VERSION ""

NS_ :

BS_:

BU_: BAP_Tester BedienDisp_vo BedienSG_hi CGS DDA Gateway Gateway_PAG GurtMikrofon OTA_FC ZR_High ZR_LIMU ZR_MIB_TOP_ab_Gen3 ZR_Standard

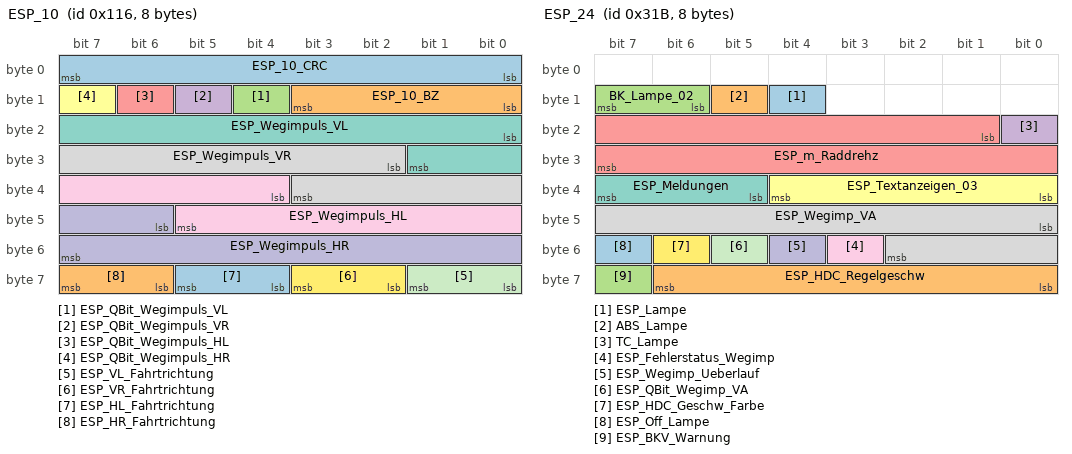
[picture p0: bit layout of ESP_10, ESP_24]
BO_ 278 ESP_10: 8 Gateway_MQB
 SG_ ESP_10_CRC : 0|8@1+ (1,0) [0|255] "" Airbag_MQB,Motor_Diesel_MQB,Motor_Hybrid_MQB,Motor_Otto_MQB
 SG_ ESP_10_BZ : 8|4@1+ (1,0) [0|15] "" Airbag_MQB,Motor_Diesel_MQB,Motor_Hybrid_MQB,Motor_Otto_MQB
 SG_ ESP_QBit_Wegimpuls_VL : 12|1@1+ (1,0) [0|1] "" Getriebe_DQ_Hybrid_MQB,Getriebe_DQ_MQB,Motor_Diesel_MQB,Motor_Hybrid_MQB,Motor_Otto_MQB
 SG_ ESP_QBit_Wegimpuls_VR : 13|1@1+ (1,0) [0|1] "" Getriebe_DQ_Hybrid_MQB,Getriebe_DQ_MQB,Motor_Diesel_MQB,Motor_Hybrid_MQB,Motor_Otto_MQB
 SG_ ESP_QBit_Wegimpuls_HL : 14|1@1+ (1,0) [0|1] "" Getriebe_DQ_Hybrid_MQB,Getriebe_DQ_MQB,Motor_Diesel_MQB,Motor_Hybrid_MQB,Motor_Otto_MQB
 SG_ ESP_QBit_Wegimpuls_HR : 15|1@1+ (1,0) [0|1] "" Getriebe_DQ_Hybrid_MQB,Getriebe_DQ_MQB,Motor_Diesel_MQB,Motor_Hybrid_MQB,Motor_Otto_MQB
 SG_ ESP_Wegimpuls_VL : 16|10@1+ (1,0) [0|1000] "" Getriebe_DQ_Hybrid_MQB,Getriebe_DQ_MQB,Motor_Diesel_MQB,Motor_Hybrid_MQB,Motor_Otto_MQB
 SG_ ESP_Wegimpuls_VR : 26|10@1+ (1,0) [0|1000] "" Getriebe_DQ_Hybrid_MQB,Getriebe_DQ_MQB,Motor_Diesel_MQB,Motor_Hybrid_MQB,Motor_Otto_MQB
 SG_ ESP_Wegimpuls_HL : 36|10@1+ (1,0) [0|1000] "" Getriebe_DQ_Hybrid_MQB,Getriebe_DQ_MQB,Motor_Diesel_MQB,Motor_Hybrid_MQB,Motor_Otto_MQB
 SG_ ESP_Wegimpuls_HR : 46|10@1+ (1,0) [0|1000] "" Getriebe_DQ_Hybrid_MQB,Getriebe_DQ_MQB,Motor_Diesel_MQB,Motor_Hybrid_MQB,Motor_Otto_MQB
 SG_ ESP_VL_Fahrtrichtung : 56|2@1+ (1,0) [0|3] "" Airbag_MQB,Getriebe_DQ_Hybrid_MQB,Getriebe_DQ_MQB,Motor_Diesel_MQB,Motor_Hybrid_MQB,Motor_Otto_MQB
 SG_ ESP_VR_Fahrtrichtung : 58|2@1+ (1,0) [0|3] "" Airbag_MQB,Getriebe_DQ_Hybrid_MQB,Getriebe_DQ_MQB,Motor_Diesel_MQB,Motor_Hybrid_MQB,Motor_Otto_MQB
 SG_ ESP_HL_Fahrtrichtung : 60|2@1+ (1,0) [0|3] "" Airbag_MQB,Getriebe_DQ_Hybrid_MQB,Getriebe_DQ_MQB,Motor_Diesel_MQB,Motor_Hybrid_MQB,Motor_Otto_MQB
 SG_ ESP_HR_Fahrtrichtung : 62|2@1+ (1,0) [0|3] "" Airbag_MQB,Getriebe_DQ_Hybrid_MQB,Getriebe_DQ_MQB,Motor_Diesel_MQB,Motor_Hybrid_MQB,Motor_Otto_MQB

BO_ 253 ESP_21: 8 Gateway
 SG_ CHECKSUM : 0|8@1+ (1,0) [0|255] ""  Vector__XXX
 SG_ COUNTER : 8|4@1+ (1,0) [0|15] ""  Vector__XXX
 SG_ BR_Eingriffsmoment : 12|10@1+ (1,-509) [-509|509] ""  Vector__XXX
 SG_ ESP_Diagnose : 23|1@1+ (1.0,0.0) [0.0|1] ""  ZR_High
 SG_ ESC_v_Signal_Qualifier_High_Low : 24|3@1+ (1.0,0.0) [0.0|7] ""  Vector__XXX
 SG_ ESP_Vorsteuerung : 28|1@1+ (1.0,0.0) [0.0|1] ""  Vector__XXX
 SG_ OBD_Schlechtweg : 30|1@1+ (1.0,0.0) [0.0|1] ""  ZR_High
 SG_ OBD_QBit_Schlechtweg : 31|1@1+ (1.0,0.0) [0.0|1] ""  ZR_High
 SG_ ESP_v_Signal : 32|16@1+ (0.01,0) [0.00|655.32] "Unit_KiloMeterPerHour"  BedienSG_hi,DDA,OTA_FC,ZR_High,ZR_LIMU,ZR_MIB_TOP_ab_Gen3,ZR_Standard
 SG_ ASR_Tastung_passiv : 48|1@1+ (1.0,0.0) [0.0|1] ""  OTA_FC
 SG_ ESP_Tastung_passiv : 49|1@1+ (1.0,0.0) [0.0|1] ""  OTA_FC,ZR_High,ZR_LIMU,ZR_MIB_TOP_ab_Gen3
 SG_ ESP_Systemstatus : 50|1@1+ (1.0,0.0) [0.0|1] ""  OTA_FC
 SG_ ASR_Schalteingriff : 51|2@1+ (1.0,0.0) [0.0|3] ""  Vector__XXX
 SG_ ESP_QBit_v_Signal : 55|1@1+ (1.0,0.0) [0.0|1] ""  ZR_High,ZR_LIMU,ZR_MIB_TOP_ab_Gen3,ZR_Standard
 SG_ ABS_Bremsung : 56|1@1+ (1.0,0.0) [0.0|1] ""  OTA_FC,ZR_High,ZR_LIMU,ZR_MIB_TOP_ab_Gen3
 SG_ ASR_Anf : 57|1@1+ (1.0,0.0) [0.0|1] ""  ZR_High
 SG_ MSR_Anf : 58|1@1+ (1.0,0.0) [0.0|1] ""  OTA_FC,ZR_High
 SG_ EBV_Eingriff : 59|1@1+ (1.0,0.0) [0.0|1] ""  Vector__XXX
 SG_ EDS_Eingriff : 60|1@1+ (1.0,0.0) [0.0|1] ""  Vector__XXX
 SG_ ESP_Eingriff : 61|1@1+ (1.0,0.0) [0.0|1] ""  OTA_FC,ZR_High
 SG_ ESP_ASP : 62|1@1+ (1.0,0.0) [0.0|1] ""  ZR_High
 SG_ ESC_Neutralschaltung : 63|1@1+ (1.0,0.0) [0.0|1] ""  Vector__XXX

BO_ 795 ESP_24: 8 Gateway
 SG_ ESP_Lampe : 12|1@1+ (1,0) [0|1] ""  Sub_Gateway
 SG_ ABS_Lampe : 13|1@1+ (1,0) [0|1] ""  Sub_Gateway
 SG_ BK_Lampe_02 : 14|2@1+ (1,0) [0|3] ""  Sub_Gateway
 SG_ TC_Lampe : 16|1@1+ (1,0) [0|1] ""  Sub_Gateway
 SG_ ESP_m_Raddrehz : 17|15@1+ (0.002,0) [0|65.278] "Unit_Hertz"  Sub_Gateway
 SG_ ESP_Textanzeigen_03 : 32|5@1+ (1,0) [0|31] ""  Sub_Gateway
 SG_ ESP_Meldungen : 37|3@1+ (1,0) [0|7] ""  Sub_Gateway
 SG_ ESP_Wegimp_VA : 40|11@1+ (1,0) [0|2047] ""  Sub_Gateway
 SG_ ESP_Fehlerstatus_Wegimp : 51|1@1+ (1,0) [0|1] ""  Sub_Gateway
 SG_ ESP_Wegimp_Ueberlauf : 52|1@1+ (1,0) [0|1] ""  Sub_Gateway
 SG_ ESP_QBit_Wegimp_VA : 53|1@1+ (1,0) [0|1] ""  Sub_Gateway
 SG_ ESP_HDC_Geschw_Farbe : 54|1@1+ (1,0) [0|1] ""  Sub_Gateway
 SG_ ESP_Off_Lampe : 55|1@1+ (1,0) [0|1] ""  Sub_Gateway
 SG_ ESP_HDC_Regelgeschw : 56|7@1+ (0.32,0) [0.32|39.68] "Unit_KiloMeterPerHour"  Sub_Gateway
 SG_ ESP_BKV_Warnung : 63|1@1+ (1,0) [0|1] ""  Sub_Gateway

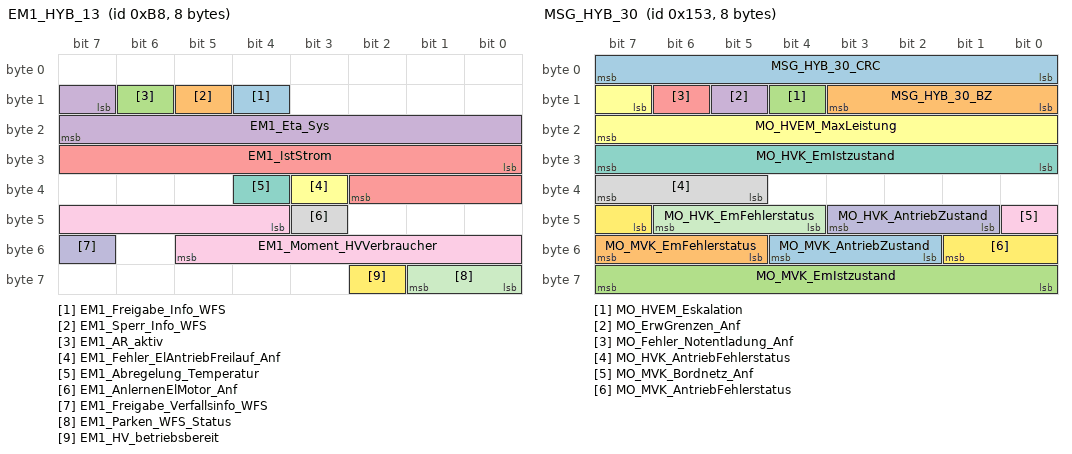
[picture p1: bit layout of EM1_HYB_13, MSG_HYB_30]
BO_ 184 EM1_HYB_13: 8 Gateway
 SG_ EM1_Freigabe_Info_WFS : 12|1@1+ (1,0) [0|1] ""  Sub_Gateway
 SG_ EM1_Sperr_Info_WFS : 13|1@1+ (1,0) [0|1] ""  Sub_Gateway
 SG_ EM1_AR_aktiv : 14|1@1+ (1,0) [0|1] ""  Sub_Gateway
 SG_ EM1_Eta_Sys : 15|9@1+ (0.2,0) [0|101.8] "Unit_PerCent"  Sub_Gateway
 SG_ EM1_IstStrom : 24|11@1+ (1,-1023) [-1023|1022] "Unit_Amper"  Sub_Gateway
 SG_ EM1_Fehler_ElAntriebFreilauf_Anf : 35|1@1+ (1,0) [0|1] ""  Sub_Gateway
 SG_ EM1_Abregelung_Temperatur : 36|1@1+ (1,0) [0|1] ""  Sub_Gateway
 SG_ EM1_AnlernenElMotor_Anf : 43|1@1+ (1,0) [0|1] ""  Sub_Gateway
 SG_ EM1_Moment_HVVerbraucher : 44|10@1+ (1,-511) [-511|511] "Unit_NewtoMeter"  Sub_Gateway
 SG_ EM1_Freigabe_Verfallsinfo_WFS : 55|1@1+ (1,0) [0|1] ""  Sub_Gateway
 SG_ EM1_Parken_WFS_Status : 56|2@1+ (1,0) [0|3] ""  Sub_Gateway
 SG_ EM1_HV_betriebsbereit : 58|1@1+ (1,0) [0|1] ""  Sub_Gateway

BO_ 339 MSG_HYB_30: 8 Gateway
 SG_ MSG_HYB_30_CRC : 0|8@1+ (1,0) [0|255] ""  Ladegeraet_Konzern
 SG_ MSG_HYB_30_BZ : 8|4@1+ (1,0) [0|15] ""  Ladegeraet_Konzern
 SG_ MO_HVEM_Eskalation : 12|1@1+ (1,0) [0|1] "" Vector__XXX
 SG_ MO_ErwGrenzen_Anf : 13|1@1+ (1,0) [0|1] ""  BMC_MLBevo
 SG_ MO_Fehler_Notentladung_Anf : 14|1@1+ (1,0) [0|1] "" Vector__XXX
 SG_ MO_HVEM_MaxLeistung : 15|9@1+ (50,0) [0|25450] "Unit_Watt" Vector__XXX
 SG_ MO_HVK_EmIstzustand : 24|8@1+ (1,0) [0|255] "" Vector__XXX
 SG_ MO_HVK_AntriebFehlerstatus : 37|3@1+ (1,0) [0|7] "" Vector__XXX
 SG_ MO_MVK_Bordnetz_Anf : 40|1@1+ (1,0) [0|1] "" Vector__XXX
 SG_ MO_HVK_AntriebZustand : 41|3@1+ (1,0) [0|7] ""  TME
 SG_ MO_HVK_EmFehlerstatus : 44|3@1+ (1,0) [0|7] "" Vector__XXX
 SG_ MO_MVK_AntriebFehlerstatus : 47|3@1+ (1,0) [0|7] "" Vector__XXX
 SG_ MO_MVK_AntriebZustand : 50|3@1+ (1,0) [0|7] "" Vector__XXX
 SG_ MO_MVK_EmFehlerstatus : 53|3@1+ (1,0) [0|7] "" Vector__XXX
 SG_ MO_MVK_EmIstzustand : 56|8@1+ (1,0) [0|255] "" Vector__XXX

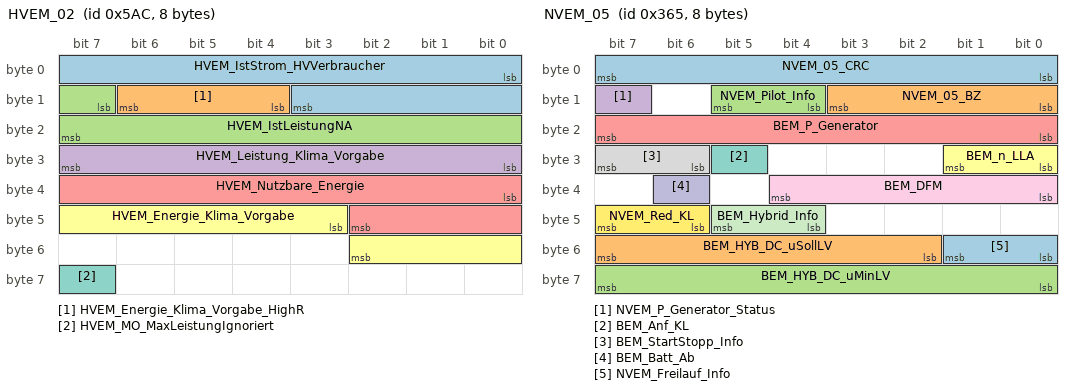
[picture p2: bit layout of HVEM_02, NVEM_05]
BO_ 1452 HVEM_02: 8 Gateway
 SG_ HVEM_IstStrom_HVVerbraucher : 0|12@1+ (0.1,-204.7) [-204.7|204.6] "Unit_Amper" Vector__XXX
 SG_ HVEM_Energie_Klima_Vorgabe_HighR : 12|3@1+ (10,0) [0|50] "Unit_WattHour"  TME
 SG_ HVEM_IstLeistungNA : 15|9@1+ (50,0) [0|25450] "Unit_Watt" Vector__XXX
 SG_ HVEM_Leistung_Klima_Vorgabe : 24|8@1+ (50,0) [0|12650] "Unit_Watt"  TME
 SG_ HVEM_Nutzbare_Energie : 32|11@1+ (50,0) [0|102200] "Unit_WattHour"  Ladegeraet_Konzern
 SG_ HVEM_Energie_Klima_Vorgabe : 43|8@1+ (50,0) [0|12650] "Unit_WattHour"  TME
 SG_ HVEM_MO_MaxLeistungIgnoriert : 63|1@1+ (1,0) [0|1] "" Vector__XXX

BO_ 869 NVEM_05: 8 Gateway
 SG_ NVEM_05_CRC : 0|8@1+ (1,0) [0|255] "" Vector__XXX
 SG_ NVEM_05_BZ : 8|4@1+ (1,0) [0|15] "" Vector__XXX
 SG_ NVEM_Pilot_Info : 12|2@1+ (1,0) [0|3] "" Vector__XXX
 SG_ NVEM_P_Generator_Status : 15|1@1+ (1,0) [0|1] "" Vector__XXX
 SG_ BEM_P_Generator : 16|8@1+ (50,0) [0|12700] "Unit_Watt" Vector__XXX
 SG_ BEM_n_LLA : 24|2@1+ (1,0) [0|3] "" Vector__XXX
 SG_ BEM_Anf_KL : 29|1@1+ (1,0) [0|1] "" Vector__XXX
 SG_ BEM_StartStopp_Info : 30|2@1+ (1,0) [0|3] "" Vector__XXX
 SG_ BEM_DFM : 32|5@1+ (3.225,0.025) [0.025|100] "" Vector__XXX
 SG_ BEM_Batt_Ab : 38|1@1+ (1,0) [0|1] ""  DCDC_800V_PAG,DCDC_IHEV
 SG_ BEM_Hybrid_Info : 44|2@1+ (1,0) [0|3] "" Vector__XXX
 SG_ NVEM_Red_KL : 46|2@1+ (1,0) [0|3] ""  TME
 SG_ NVEM_Freilauf_Info : 48|2@1+ (1,0) [0|3] "" Vector__XXX
 SG_ BEM_HYB_DC_uSollLV : 50|6@1+ (0.1,10.6) [10.6|16] "Unit_Volt"  DCDC_800V_PAG,DCDC_HV,LE_MLBevo
 SG_ BEM_HYB_DC_uMinLV : 56|8@1+ (0.1,0) [0|25.3] "Unit_Volt" Vector__XXX

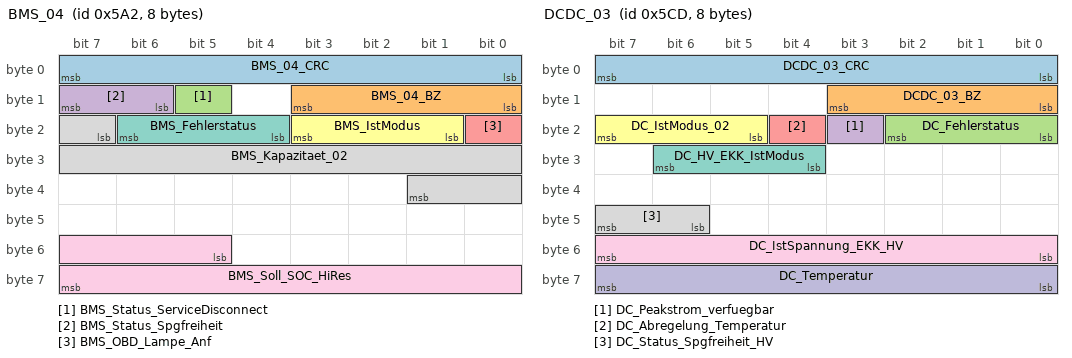
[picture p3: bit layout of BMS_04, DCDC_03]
BO_ 1442 BMS_04: 8 BMC_MLBevo
 SG_ BMS_04_CRC : 0|8@1+ (1,0) [0|255] ""  Gateway,Gateway_PAG,Sub_Gateway
 SG_ BMS_04_BZ : 8|4@1+ (1,0) [0|15] ""  Gateway,Gateway_PAG,Sub_Gateway
 SG_ BMS_Status_ServiceDisconnect : 13|1@1+ (1,0) [0|1] ""  DCDC_800V_PAG,DCDC_HV,Gateway,Gateway_PAG,Sub_Gateway
 SG_ BMS_Status_Spgfreiheit : 14|2@1+ (1,0) [0|3] ""  Gateway,Gateway_PAG,Sub_Gateway
 SG_ BMS_OBD_Lampe_Anf : 16|1@1+ (1,0) [0|1] ""  Gateway,Gateway_PAG,Sub_Gateway
 SG_ BMS_IstModus : 17|3@1+ (1,0) [0|7] ""  AWC,Gateway,Gateway_PAG,Ladegeraet_Konzern,LE1,LE2,LE2_3_MLBevo_LB,Sub_Gateway,TME
 SG_ BMS_Fehlerstatus : 20|3@1+ (1,0) [0|7] ""  AWC,DCDC_800V_PAG,DCDC_HV,Gateway,Gateway_PAG,Ladegeraet_Konzern,Sub_Gateway
 SG_ BMS_Kapazitaet_02 : 23|11@1+ (0.2,0) [0|409.2] "Unit_AmperHour"  Gateway,Gateway_PAG,Ladegeraet_Konzern,Sub_Gateway
 SG_ BMS_Soll_SOC_HiRes : 53|11@1+ (0.05,0) [0|100] "Unit_PerCent"  Gateway,Gateway_PAG,Sub_Gateway

BO_ 1485 DCDC_03: 8 DCDC_800V_PAG
 SG_ DCDC_03_CRC : 0|8@1+ (1,0) [0|255] ""  Gateway,Gateway_PAG,Sub_Gateway
 SG_ DCDC_03_BZ : 8|4@1+ (1,0) [0|15] ""  Gateway,Gateway_PAG,Sub_Gateway
 SG_ DC_Fehlerstatus : 16|3@1+ (1,0) [0|7] ""  Gateway,Gateway_PAG,Sub_Gateway
 SG_ DC_Peakstrom_verfuegbar : 19|1@1+ (1,0) [0|1] ""  Gateway,Gateway_PAG,Sub_Gateway
 SG_ DC_Abregelung_Temperatur : 20|1@1+ (1,0) [0|1] ""  Gateway_PAG,Sub_Gateway,TME
 SG_ DC_IstModus_02 : 21|3@1+ (1,0) [0|7] ""  DCDC_HV_02,Gateway,Gateway_PAG,Ladegeraet_Konzern,Sub_Gateway,TME
 SG_ DC_HV_EKK_IstModus : 28|3@1+ (1,0) [0|7] ""  Gateway,Gateway_PAG,Sub_Gateway,TME
 SG_ DC_Status_Spgfreiheit_HV : 46|2@1+ (1,0) [0|3] ""  Gateway,Gateway_PAG,Sub_Gateway
 SG_ DC_IstSpannung_EKK_HV : 48|8@1+ (2,0) [0|508] "Unit_Volt"  Gateway,Gateway_PAG,Sub_Gateway
 SG_ DC_Temperatur : 56|8@1+ (1,-40) [-40|213] "Unit_DegreCelsi"  Gateway,Gateway_PAG,Sub_Gateway,TME

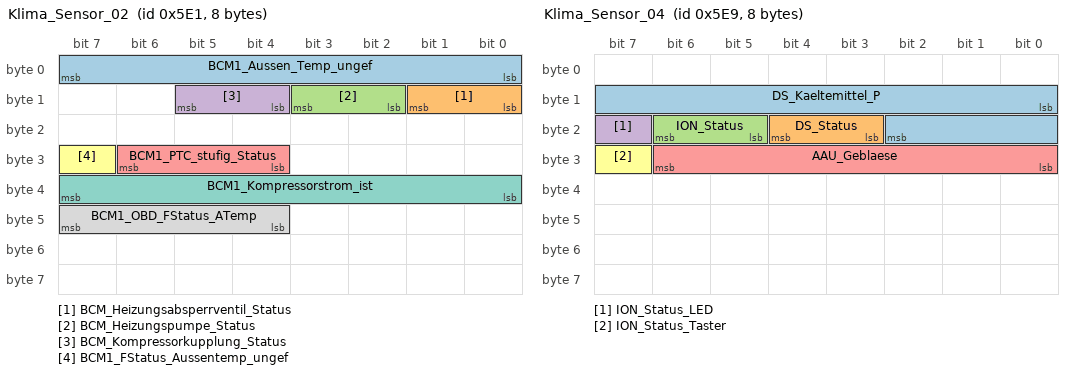
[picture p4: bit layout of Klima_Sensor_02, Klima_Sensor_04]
BO_ 1505 Klima_Sensor_02: 8 Gateway
 SG_ BCM1_Aussen_Temp_ungef : 0|8@1+ (0.5,-50) [-50|76] "Unit_DegreCelsi"  BMC_MLBevo,BMS_NV,FCU_MLBevo_FCEV,Ladegeraet_Konzern,TME
 SG_ BCM_Heizungsabsperrventil_Status : 8|2@1+ (1,0) [0|3] "" Vector__XXX
 SG_ BCM_Heizungspumpe_Status : 10|2@1+ (1,0) [0|3] "" Vector__XXX
 SG_ BCM_Kompressorkupplung_Status : 12|2@1+ (1,0) [0|3] "" Vector__XXX
 SG_ BCM1_PTC_stufig_Status : 28|3@1+ (1,0) [0|7] "" Vector__XXX
 SG_ BCM1_FStatus_Aussentemp_ungef : 31|1@1+ (1,0) [0|1] ""  TME
 SG_ BCM1_Kompressorstrom_ist : 32|8@1+ (4,0) [0|1000] "Unit_MilliAmper" Vector__XXX
 SG_ BCM1_OBD_FStatus_ATemp : 44|4@1+ (1,0) [0|15] ""  BMC_MLBevo,Ladegeraet_Konzern,TME

BO_ 1513 Klima_Sensor_04: 8 Gateway
 SG_ DS_Kaeltemittel_P : 8|11@1+ (0.0161,0) [0|32.9245] "Unit_Bar"  TME
 SG_ DS_Status : 19|2@1+ (1,0) [0|3] ""  TME
 SG_ ION_Status : 21|2@1+ (1,0) [0|3] "" Vector__XXX
 SG_ ION_Status_LED : 23|1@1+ (1,0) [0|1] "" Vector__XXX
 SG_ AAU_Geblaese : 24|7@1+ (1,0) [0|100] "Unit_PerCent" Vector__XXX
 SG_ ION_Status_Taster : 31|1@1+ (1,0) [0|1] "" Vector__XXX

BO_ 1600 Motor_07: 8 Motor_Diesel_MQB
 SG_ MO_QBit_Ansaugluft_Temp : 0|1@1+ (1,0) [0|1] "" Gateway_MQB
 SG_ MO_QBit_Oel_Temp : 1|1@1+ (1,0) [0|1] "" Gateway_MQB,Getriebe_DQ_Hybrid_MQB,Getriebe_DQ_MQB
 SG_ MO_QBit_Kuehlmittel_Temp : 2|1@1+ (1,0) [0|1] "" Gateway_MQB,Getriebe_DQ_Hybrid_MQB,Getriebe_DQ_MQB,LEH_MQB
 SG_ MO_Stellgliedtest_Soundaktuator : 3|1@1+ (1,0) [0|1] "" Gateway_MQB
 SG_ MO_HYB_Fehler_HV_Netz : 4|1@1+ (1,0) [0|1] "" Gateway_MQB
 SG_ MO_aktives_Getriebeheizen : 5|1@1+ (1,0) [0|1] "" Gateway_MQB,Getriebe_DQ_Hybrid_MQB,Getriebe_DQ_MQB
 SG_ MO_Absperrventil_oeffnen : 6|2@1+ (1,0) [0|3] "" Gateway_MQB
 SG_ MO_Ansaugluft_Temp : 8|8@1+ (0.75,-48) [-48|141.75] "Unit_DegreCelsi" Gateway_MQB
 SG_ MO_Oel_Temp : 16|8@1+ (1,-60) [-60|192] "Unit_DegreCelsi" Gateway_MQB,Getriebe_DQ_Hybrid_MQB,Getriebe_DQ_MQB
 SG_ MO_Kuehlmittel_Temp : 24|8@1+ (0.75,-48) [-48|141.75] "Unit_DegreCelsi" Gateway_MQB,Getriebe_DQ_Hybrid_MQB,Getriebe_DQ_MQB,LEH_MQB
 SG_ MO_Hoeheninfo : 32|8@1+ (0.00781,0) [0|1.98374] "" Gateway_MQB,Getriebe_DQ_Hybrid_MQB,Getriebe_DQ_MQB
 SG_ MO_Kennfeldk : 40|1@1+ (1,0) [0|1] "" Gateway_MQB
 SG_ MO_Versionsinfo : 41|6@1+ (1,0) [0|63] "" Gateway_MQB
 SG_ MO_Getriebe_kuehlen : 47|1@1+ (1,0) [0|1] "" Gateway_MQB,Getriebe_DQ_Hybrid_MQB,Getriebe_DQ_MQB
 SG_ MO_Mom_Traegheit_02 : 48|5@1+ (0.01,0) [0|0.31] "Unit_KiloGramMeterSquar" Gateway_MQB,Getriebe_DQ_Hybrid_MQB,Getriebe_DQ_MQB
 SG_ MO_Heizungspumpenansteuerung : 53|4@1+ (10,0) [0|100] "Unit_PerCent" Gateway_MQB
 SG_ MO_SpannungsAnf : 57|1@1+ (1,0) [0|1] "" Gateway_MQB
 SG_ MO_Nachlaufzeit_Heizungspumpe : 58|6@1+ (15,0) [0|945] "Unit_Secon" Gateway_MQB

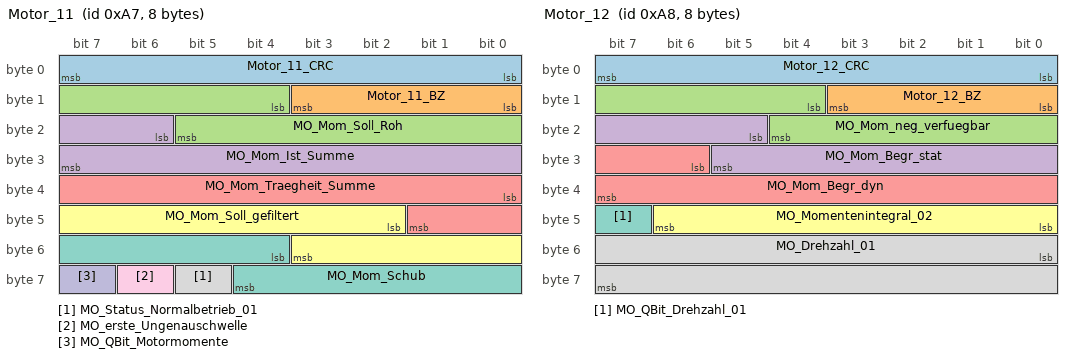
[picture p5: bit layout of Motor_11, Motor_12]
BO_ 167 Motor_11: 8 Motor_Diesel_MQB
 SG_ Motor_11_CRC : 0|8@1+ (1,0) [0|255] "" Gateway_MQB,Getriebe_DQ_Hybrid_MQB,Getriebe_DQ_MQB
 SG_ Motor_11_BZ : 8|4@1+ (1,0) [0|15] "" Gateway_MQB,Getriebe_DQ_Hybrid_MQB,Getriebe_DQ_MQB
 SG_ MO_Mom_Soll_Roh : 12|10@1+ (1,-509) [-509|509] "Unit_NewtoMeter" Gateway_MQB,Getriebe_DQ_Hybrid_MQB,Getriebe_DQ_MQB
 SG_ MO_Mom_Ist_Summe : 22|10@1+ (1,-509) [-509|509] "Unit_NewtoMeter" Gateway_MQB,Getriebe_DQ_Hybrid_MQB,Getriebe_DQ_MQB,SAK_MQB
 SG_ MO_Mom_Traegheit_Summe : 32|10@1+ (1,-509) [-509|509] "Unit_NewtoMeter" Gateway_MQB,Getriebe_DQ_Hybrid_MQB,Getriebe_DQ_MQB
 SG_ MO_Mom_Soll_gefiltert : 42|10@1+ (1,-509) [-509|509] "Unit_NewtoMeter" Gateway_MQB,Getriebe_DQ_Hybrid_MQB,Getriebe_DQ_MQB
 SG_ MO_Mom_Schub : 52|9@1+ (1,-509) [-509|0] "Unit_NewtoMeter" Gateway_MQB,Getriebe_DQ_Hybrid_MQB,Getriebe_DQ_MQB
 SG_ MO_Status_Normalbetrieb_01 : 61|1@1+ (1,0) [0|1] "" Gateway_MQB,Getriebe_DQ_Hybrid_MQB,Getriebe_DQ_MQB
 SG_ MO_erste_Ungenauschwelle : 62|1@1+ (1,0) [0|1] "" Gateway_MQB
 SG_ MO_QBit_Motormomente : 63|1@1+ (1,0) [0|1] "" Gateway_MQB,Getriebe_DQ_Hybrid_MQB,Getriebe_DQ_MQB

BO_ 168 Motor_12: 8 Motor_Diesel_MQB
 SG_ Motor_12_CRC : 0|8@1+ (1,0) [0|255] "" Gateway_MQB,Getriebe_DQ_Hybrid_MQB,Getriebe_DQ_MQB,LEH_MQB
 SG_ Motor_12_BZ : 8|4@1+ (1,0) [0|15] "" BMS_MQB,Gateway_MQB,Getriebe_DQ_Hybrid_MQB,Getriebe_DQ_MQB,LEH_MQB
 SG_ MO_Mom_neg_verfuegbar : 12|9@1+ (1,-509) [-509|0] "Unit_NewtoMeter" Gateway_MQB
 SG_ MO_Mom_Begr_stat : 21|9@1+ (1,0) [0|509] "Unit_NewtoMeter" Gateway_MQB,Getriebe_DQ_Hybrid_MQB,Getriebe_DQ_MQB
 SG_ MO_Mom_Begr_dyn : 30|10@1+ (1,-509) [-509|509] "Unit_NewtoMeter" Gateway_MQB
 SG_ MO_Momentenintegral_02 : 40|7@1+ (1,0) [0|100] "Unit_PerCent" Gateway_MQB,Getriebe_DQ_Hybrid_MQB,Getriebe_DQ_MQB
 SG_ MO_QBit_Drehzahl_01 : 47|1@1+ (1,0) [0|1] "" BMS_MQB,Gateway_MQB,Getriebe_DQ_Hybrid_MQB,Getriebe_DQ_MQB,LEH_MQB
 SG_ MO_Drehzahl_01 : 48|16@1+ (0.25,0) [0|16383] "Unit_MinutInver" BMS_MQB,Gateway_MQB,Getriebe_DQ_Hybrid_MQB,Getriebe_DQ_MQB,LEH_MQB,SAK_MQB

BO_ 958 Motor_14: 8 Gateway
 SG_ CHECKSUM : 0|8@1+ (1,0) [0|255] ""  XXX
 SG_ COUNTER : 8|4@1+ (1,0) [0|15] ""  XXX
 SG_ MO_StartStopp_Status : 12|2@1+ (1,0) [0|3] ""  Sub_Gateway,TME
 SG_ MO_StartStopp_Wiederstart : 14|1@1+ (1,0) [0|1] ""  BMS_NV,Sub_Gateway,TME
 SG_ MO_StartStopp_Motorstopp : 15|1@1+ (1,0) [0|1] ""  BMS_NV,Sub_Gateway,TME
 SG_ MO_Freig_Reku : 16|2@1+ (1,0) [0|3] ""  Sub_Gateway
 SG_ MO_Kl_75 : 18|1@1+ (1,0) [0|1] ""  Sub_Gateway,TME
 SG_ MO_Kl_50 : 19|1@1+ (1,0) [0|1] ""  DCDC_IHEV,Ladegeraet_Konzern,Sub_Gateway
 SG_ MO_Gangposition : 20|4@1+ (1,0) [0|15] ""  AWC,Sub_Gateway,TME
 SG_ MO_StartStopp_Fahrerwunsch : 24|2@1+ (1,0) [0|3] ""  Sub_Gateway,TME
 SG_ MO_HYB_Fahrbereitschaft : 26|1@1+ (1,0) [0|1] ""  AWC,BMS_NV,Ladegeraet_Konzern,Sub_Gateway,TME
 SG_ MO_Ext_E_Fahrt_aktiv : 27|1@1+ (1,0) [0|1] ""  Sub_Gateway,TME
 SG_ MO_Fahrer_bremst : 28|1@1+ (1,0) [0|1] ""  Sub_Gateway
 SG_ MO_QBit_Fahrer_bremst : 29|1@1+ (1,0) [0|1] ""  Sub_Gateway
 SG_ MO_BLS : 30|1@1+ (1,0) [0|1] ""  Sub_Gateway
 SG_ MO_Konsistenz_Bremsped : 31|1@1+ (1,0) [0|1] ""  Sub_Gateway
 SG_ MO_KomFehler_ESP : 32|1@1+ (1,0) [0|1] ""  Sub_Gateway
 SG_ MO_Klima_Eingr : 33|2@1+ (1,0) [0|3] ""  Sub_Gateway,TME
 SG_ MO_Aussp_Anlass : 35|1@1+ (1,0) [0|1] ""  Sub_Gateway
 SG_ MO_Freig_Anlass : 36|1@1+ (1,0) [0|1] ""  Sub_Gateway
 SG_ MO_Kuppl_schalter : 37|1@1+ (1,0) [0|1] ""  Sub_Gateway
 SG_ MO_Interlock : 38|1@1+ (1,0) [0|1] ""  Sub_Gateway
 SG_ MO_Motor_laeuft : 39|1@1+ (1,0) [0|1] ""  Sub_Gateway,TME
 SG_ MO_Kickdown : 40|1@1+ (1,0) [0|1] ""  Sub_Gateway,TME
 SG_ MO_QBit_KL_75 : 41|1@1+ (1,0) [0|1] ""  Sub_Gateway
 SG_ MO_EKlKomLeiRed : 42|2@1+ (1,0) [0|3] ""  Sub_Gateway
 SG_ MO_Handshake_STH : 44|1@1+ (1,0) [0|1] ""  Sub_Gateway
 SG_ MO_BKV_Unterdruckwarnung : 45|1@1+ (1,0) [0|1] ""  Sub_Gateway
 SG_ MO_Freigabe_Segeln : 46|1@1+ (1,0) [0|1] ""  Sub_Gateway
 SG_ MO_PTC_Status : 47|3@1+ (1,0) [0|7] ""  Sub_Gateway
 SG_ MO_QBit_Gangposition : 50|1@1+ (1,0) [0|1] ""  Sub_Gateway
 SG_ MO_Signalquelle_Gangposition : 51|1@1+ (1,0) [0|1] ""  Sub_Gateway
 SG_ MO_Remotestart_Betrieb : 52|1@1+ (1,0) [0|1] ""  Sub_Gateway
 SG_ MO_Remotestart_moeglich : 53|1@1+ (1,0) [0|1] ""  Sub_Gateway
 SG_ MO_FMAus_aktiv : 55|1@1+ (1,0) [0|1] ""  BMS_NV,Sub_Gateway
 SG_ MO_FMAus_Startvariante : 56|2@1+ (1,0) [0|3] ""  Sub_Gateway
 SG_ MO_BMS_NV_Anf_stuetzen : 58|1@1+ (1,0) [0|1] ""  Sub_Gateway
 SG_ MO_Zylinderabschaltung : 59|2@1+ (1,0) [0|3] ""  Sub_Gateway
 SG_ MO_HYB_VM_aktiv : 61|1@1+ (1,0) [0|1] ""  Sub_Gateway
 SG_ MO_StartVorauss_erfuellt : 62|2@1+ (1,0) [0|3] ""  AWC,Ladegeraet_Konzern,Sub_Gateway

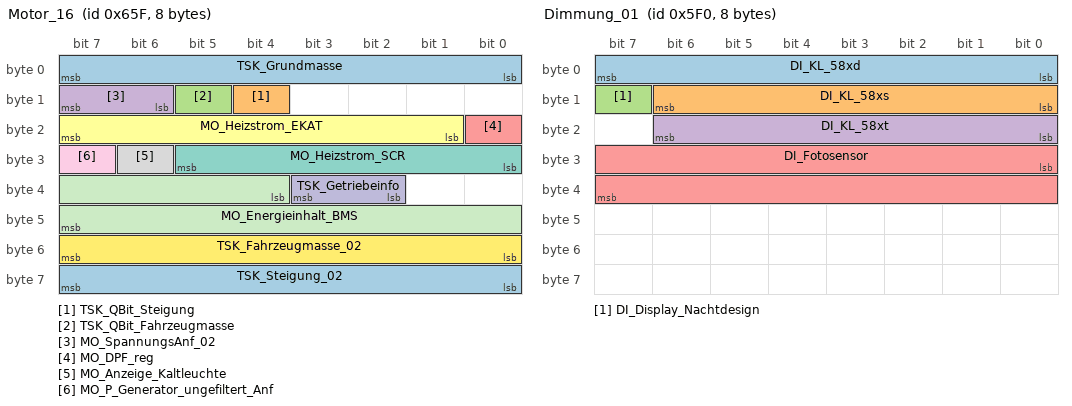
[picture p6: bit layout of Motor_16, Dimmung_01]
BO_ 1631 Motor_16: 8 Gateway
 SG_ TSK_Grundmasse : 0|8@1+ (32,0) [0|8128] "Unit_KiloGram"  ZR_High
 SG_ TSK_QBit_Steigung : 12|1@1+ (1.0,0.0) [0.0|1] ""  Vector__XXX
 SG_ TSK_QBit_Fahrzeugmasse : 13|1@1+ (1.0,0.0) [0.0|1] ""  ZR_High
 SG_ MO_SpannungsAnf_02 : 14|2@1+ (1.0,0.0) [0.0|3] ""  Vector__XXX
 SG_ MO_DPF_reg : 16|1@1+ (1.0,0.0) [0.0|1] ""  ZR_High
 SG_ MO_Heizstrom_EKAT : 17|7@1+ (1,0) [0|126] "Unit_Amper"  Vector__XXX
 SG_ MO_Heizstrom_SCR : 24|6@1+ (1,0) [0|62] "Unit_Amper"  Vector__XXX
 SG_ MO_Anzeige_Kaltleuchte : 30|1@1+ (1.0,0.0) [0.0|1] ""  Vector__XXX
 SG_ MO_P_Generator_ungefiltert_Anf : 31|1@1+ (1.0,0.0) [0.0|1] ""  Vector__XXX
 SG_ TSK_Getriebeinfo : 34|2@1+ (1.0,0.0) [0.0|3] ""  Vector__XXX
 SG_ MO_Energieinhalt_BMS : 36|12@1+ (25,0) [0|102325] "Unit_WattHour"  Vector__XXX
 SG_ TSK_Fahrzeugmasse_02 : 48|8@1+ (32,0) [0|8128] "Unit_KiloGram"  OTA_FC,ZR_High
 SG_ TSK_Steigung_02 : 56|8@1+ (0.8,-101.6) [-100.8|101.6] "Unit_PerCent"  OTA_FC

BO_ 1648 Motor_18: 8 Gateway
 SG_ MO_max_Ladedruck : 0|6@1+ (0.1,0) [0|6.3] "Unit_Bar"  Sub_Gateway
 SG_ MO_ANC_Kennfeld_Anf : 6|2@1+ (1,0) [0|3] ""  Sub_Gateway
 SG_ MO_Bremslicht_Reku : 8|1@1+ (1,0) [0|1] ""  Sub_Gateway
 SG_ MO_StartStopp_PopUp : 9|2@1+ (1,0) [0|3] ""  Sub_Gateway
 SG_ MO1_Sperr_Info_WFS : 11|1@1+ (1,0) [0|1] ""  Sub_Gateway
 SG_ MO1_Freigabe_Info_WFS : 12|1@1+ (1,0) [0|1] ""  Sub_Gateway
 SG_ MO_EPCL : 13|3@1+ (1,0) [0|7] ""  Sub_Gateway
 SG_ MO_Zylabsch_Texte_02 : 16|4@1+ (1,0) [0|15] ""  Sub_Gateway
 SG_ MO_Fahrzeugtyp : 20|3@1+ (1,0) [0|7] ""  BMS_NV,Sub_Gateway
 SG_ MO_NMAX_Schaltanzeige : 23|9@1+ (25,0) [0|12775] "Unit_MinutInver"  Sub_Gateway
 SG_ MO_Abstellzeit : 32|8@1+ (8,0) [0|2024] "Unit_Minut"  BMS_NV,Sub_Gateway,TME
 SG_ MO_Abstellzeit_Status : 40|2@1+ (1,0) [0|3] ""  BMS_NV,Sub_Gateway,TME
 SG_ MO1_Freigabe_Verfallsinfo_WFS : 42|1@1+ (1,0) [0|1] ""  Sub_Gateway
 SG_ MO_Hybrid_StartStopp_LED : 43|2@1+ (1,0) [0|3] ""  Sub_Gateway
 SG_ MO_Fehler_Zylabsch : 45|2@1+ (1,0) [0|3] ""  Sub_Gateway
 SG_ MO_Anzahl_Abgesch_Zyl : 47|3@1+ (1,0) [0|7] ""  Sub_Gateway
 SG_ MO_Zylabsch_Texte : 50|2@1+ (1,0) [0|3] ""  Sub_Gateway
 SG_ MO_Ethanol_BS_Texte : 52|3@1+ (1,0) [0|7] ""  Sub_Gateway
 SG_ MO_Drehzahl_Warnung : 55|1@1+ (1,0) [0|1] ""  Sub_Gateway
 SG_ MO_obere_Drehzahlgrenze : 56|8@1+ (50,0) [50|12750] "Unit_MinutInver"  Sub_Gateway

BO_ 967 Motor_26: 8 Gateway
 SG_ MO_Kuehlerluefter_MUX M : 0|1@1+ (1,0) [0|1] ""  TME
 SG_ MO_Kuehlerluefter_1 m0 : 1|7@1+ (1,0) [0|100] "Unit_PerCent"  TME
 SG_ MO_Kuehlerluefter_2 m1 : 1|7@1+ (1,0) [0|100] "Unit_PerCent"  TME
 SG_ MO_EFLEX_Lampe : 8|2@1+ (1,0) [0|3] "" Vector__XXX
 SG_ MO_KJS_nicht_bereit : 10|1@1+ (1,0) [0|1] "" Vector__XXX
 SG_ MO_ITM_Warnung_Pumpe : 11|1@1+ (1,0) [0|1] "" Vector__XXX
 SG_ WIV_Anzeige_aktiv : 12|1@1+ (1,0) [0|1] "" Vector__XXX
 SG_ WIV_Oelmin_Warn : 13|1@1+ (1,0) [0|1] "" Vector__XXX
 SG_ WIV_Sensorfehler : 14|1@1+ (1,0) [0|1] "" Vector__XXX
 SG_ WIV_Schieflage : 15|1@1+ (1,0) [0|1] "" Vector__XXX
 SG_ WIV_Oelstand : 16|4@1+ (12.5,0) [0|100] "Unit_PerCent" Vector__XXX
 SG_ MO_Zustand_HWP : 20|2@1+ (1,0) [0|3] ""  TME
 SG_ OLEV_Systemstoerung : 22|1@1+ (1,0) [0|1] "" Vector__XXX
 SG_ MO_Oelwarnung_max : 23|1@1+ (1,0) [0|1] "" Vector__XXX
 SG_ WIV_Oelsystem_aktiv : 24|1@1+ (1,0) [0|1] "" Vector__XXX
 SG_ WIV_nicht_betriebswarm : 25|1@1+ (1,0) [0|1] "" Vector__XXX
 SG_ WIV_Ueberfuell_Warn : 26|1@1+ (1,0) [0|1] "" Vector__XXX
 SG_ WIV_laufender_Motor : 27|1@1+ (1,0) [0|1] "" Vector__XXX
 SG_ MO_E_Warnungen : 28|4@1+ (1,0) [0|15] "" Vector__XXX
 SG_ MO_Text_Motorstart : 32|4@1+ (1,0) [0|15] "" Vector__XXX
 SG_ MO_E_Texte : 36|4@1+ (1,0) [0|15] "" Vector__XXX
 SG_ WIV_Oeldyn_avl : 40|1@1+ (1,0) [0|1] "" Vector__XXX
 SG_ MO_Text_Partikelfil_Reg : 41|1@1+ (1,0) [0|1] "" Vector__XXX
 SG_ OLEV_Oelstand_nicht_vorhanden : 42|1@1+ (1,0) [0|1] "" Vector__XXX
 SG_ WIV_Oelmenge : 43|5@1+ (125,0) [0|3875] "Unit_MilliLiter" Vector__XXX
 SG_ MO_Systemlampe : 48|1@1+ (1,0) [0|1] "" Vector__XXX
 SG_ MO_OBD2_Lampe : 49|1@1+ (1,0) [0|1] "" Vector__XXX
 SG_ MO_Heissleuchte : 50|1@1+ (1,0) [0|1] ""  TME
 SG_ MO_Partikel_Lampe : 51|1@1+ (1,0) [0|1] "" Vector__XXX
 SG_ MO_RedFahrleistung_Lampe : 52|1@1+ (1,0) [0|1] "" Vector__XXX
 SG_ WIV_Oelstand_nicht_vorhanden : 53|1@1+ (1,0) [0|1] "" Vector__XXX
 SG_ WIV_nachfuellanzeige_ein : 54|1@1+ (1,0) [0|1] "" Vector__XXX
 SG_ WIV_Ueberfuell_deaktiv : 55|1@1+ (1,0) [0|1] "" Vector__XXX
 SG_ WIV_Unterfuell_Warn : 56|1@1+ (1,0) [0|1] "" Vector__XXX
 SG_ MO_Tankdeckel_Lampe : 57|1@1+ (1,0) [0|1] "" Vector__XXX
 SG_ MO_Text_Tankdeckelwarn : 58|1@1+ (1,0) [0|1] "" Vector__XXX
 SG_ MO_Vorglueh_Lampe : 59|1@1+ (1,0) [0|1] "" Vector__XXX
 SG_ WIV_Oeldr_Warn_Motor : 60|1@1+ (1,0) [0|1] "" Vector__XXX
 SG_ MO_E_Mode : 61|3@1+ (1,0) [0|7] "" Vector__XXX

BO_ 916 WBA_03: 8 Gateway
 SG_ WBA_03_CRC : 0|8@1+ (1,0) [0|255] ""  Sub_Gateway
 SG_ WBA_03_BZ : 8|4@1+ (1,0) [0|15] ""  Sub_Gateway
 SG_ WBA_Fahrstufe_02 : 12|4@1+ (1,0) [0|15] ""  Sub_Gateway
 SG_ WBA_ZielFahrstufe : 16|4@1+ (1,0) [0|15] ""  Sub_Gateway
 SG_ WBA_GE_Warnung_02 : 20|4@1+ (1,0) [0|15] ""  Sub_Gateway
 SG_ WBA_eing_Gang_02 : 24|4@1+ (1,0) [0|15] ""  Sub_Gateway
 SG_ WBA_GE_Texte : 28|3@1+ (1,0) [0|7] ""  Sub_Gateway
 SG_ WBA_Segeln_aktiv : 31|1@1+ (1,0) [0|1] ""  Sub_Gateway
 SG_ WBA_Schaltschema : 32|5@1+ (1,0) [0|31] ""  Sub_Gateway
 SG_ WBA_GE_Zusatzwarnungen : 37|3@1+ (1,0) [0|7] ""  Sub_Gateway
 SG_ GE_Sollgang : 40|4@1+ (1,0) [0|15] ""  Sub_Gateway
 SG_ GE_Tipschaltempf_verfuegbar : 44|1@1+ (1,0) [0|1] ""  Sub_Gateway
 SG_ WBA_GE_Texte_02 : 45|3@1+ (1,0) [0|7] ""  Sub_Gateway
 SG_ WBA_GE_Texte_03 : 48|4@1+ (1,0) [0|15] ""  Sub_Gateway
 SG_ WBA_Blinken : 54|1@1+ (1,0) [0|1] ""  Sub_Gateway
 SG_ GE_Wiederstart_Anz_Std : 55|1@1+ (1,0) [0|1] ""  Sub_Gateway
 SG_ GE_Stoppverbot_Anz_01 : 56|1@1+ (1,0) [0|1] ""  Sub_Gateway
 SG_ GE_Stoppverbot_Anz_02 : 57|1@1+ (1,0) [0|1] ""  Sub_Gateway
 SG_ GE_Stoppverbot_Anz_03 : 58|1@1+ (1,0) [0|1] ""  Sub_Gateway
 SG_ GE_Stoppverbot_Anz_04 : 59|1@1+ (1,0) [0|1] ""  Sub_Gateway
 SG_ GE_Stoppverbot_Anz_05 : 60|1@1+ (1,0) [0|1] ""  Sub_Gateway
 SG_ GE_Stoppverbot_Anz_06 : 61|1@1+ (1,0) [0|1] ""  Sub_Gateway
 SG_ GE_Stoppverbot_Anz_07 : 62|1@1+ (1,0) [0|1] ""  Sub_Gateway
 SG_ GE_Stoppverbot_Anz_Std : 63|1@1+ (1,0) [0|1] ""  Sub_Gateway

BO_ 1283 HVK_01: 8 Gateway
 SG_ HVK_01_CRC : 0|8@1+ (1,0) [0|255] ""  BMC_MLBevo,DCDC_800V_PAG,DCDC_HV,DCDC_HV_02,FCU_MLBevo_FCEV,Ladegeraet_2,Ladegeraet_Konzern,LE1,LE2,LE_MLBevo,TME
 SG_ HVK_01_BZ : 8|4@1+ (1,0) [0|15] ""  BMC_MLBevo,DCDC_800V_PAG,DCDC_HV,DCDC_HV_02,FCU_MLBevo_FCEV,Ladegeraet_2,Ladegeraet_Konzern,LE1,LE2,LE_MLBevo,TME
 SG_ HVK_Istmodus_Anf : 12|1@1+ (1,0) [0|1] ""  BMC_MLBevo,DCDC_HV,FCU_MLBevo_FCEV,Ladegeraet_2,Ladegeraet_Konzern,LE1,LE2,LE_MLBevo
 SG_ HVK_TN1_Sollmodus : 13|2@1+ (1,0) [0|3] ""  DCDC_HV_02,FCU_MLBevo_FCEV
 SG_ HVK_MO_EmSollzustand : 16|8@1+ (1,0) [0|255] ""  FCU_MLBevo_FCEV
 SG_ HVK_BMS_Sollmodus : 24|3@1+ (1,0) [0|7] ""  BMC_MLBevo,FCU_MLBevo_FCEV
 SG_ HVK_DCDC_Sollmodus : 27|3@1+ (1,0) [0|7] ""  DCDC_800V_PAG,DCDC_HV,FCU_MLBevo_FCEV,LE_MLBevo
 SG_ HVK_EKK_Sollmodus : 30|3@1+ (1,0) [0|7] ""  FCU_MLBevo_FCEV,TME
 SG_ HVK_HVPTC_Sollmodus : 33|3@1+ (1,0) [0|7] ""  FCU_MLBevo_FCEV,TME
 SG_ HVK_HVLM_Sollmodus : 36|3@1+ (1,0) [0|7] ""  DCDC_HV_02,FCU_MLBevo_FCEV,Ladegeraet_Konzern
 SG_ HVK_HV_Netz_Warnungen : 39|2@1+ (1,0) [0|3] ""  FCU_MLBevo_FCEV
 SG_ HV_Bordnetz_aktiv : 41|1@1+ (1,0) [0|1] ""  DCDC_HV_02,FCU_MLBevo_FCEV,Ladegeraet_Konzern,LE1,LE2,LE_MLBevo
 SG_ HV_Bordnetz_Fehler : 42|1@1+ (1,0) [0|1] ""  FCU_MLBevo_FCEV,Ladegeraet_Konzern,TME
 SG_ HVK_Gesamtst_Spgfreiheit : 43|2@1+ (1,0) [0|3] ""  FCU_MLBevo_FCEV
 SG_ HVK_AktiveEntladung_Anf : 45|1@1+ (1,0) [0|1] ""  DCDC_800V_PAG,DCDC_HV,DCDC_HV_02,FCU_MLBevo_FCEV,LE1,LE2,LE_MLBevo
 SG_ HVK_Iso_Messung_Start : 50|3@1+ (1,0) [0|7] ""  BMC_MLBevo,FCU_MLBevo_FCEV
 SG_ HVK_DCDC_EKK_Sollmodus : 62|2@1+ (1,0) [0|3] ""  DCDC_800V_PAG,FCU_MLBevo_FCEV

BO_ 949 Klima_11: 8 Gateway
 SG_ KL_Drehz_Anh : 0|1@1+ (1,0) [0|1] ""  TME
 SG_ KL_Vorwarn_Komp_ein : 1|1@1+ (1,0) [0|1] ""  TME
 SG_ KL_AC_Schalter : 2|1@1+ (1,0) [0|1] ""  TME
 SG_ KL_Komp_Moment_alt : 3|1@1+ (1,0) [0|1] ""  TME
 SG_ KL_Vorwarn_Zuheizer_ein : 6|1@1+ (1,0) [0|1] "" Vector__XXX
 SG_ KL_Zustand : 7|1@1+ (1,0) [0|1] ""  TME
 SG_ KL_Kompressorkupplung_linear : 8|8@1+ (20,0) [0|4000] "Unit_MilliAmper" Vector__XXX
 SG_ KL_Charisma_FahrPr : 16|4@1+ (1,0) [0|15] ""  TME
 SG_ KL_Charisma_Status : 20|2@1+ (1,0) [0|3] ""  TME
 SG_ KL_nachtr_Stopp_Anf : 22|1@1+ (1,0) [0|1] "" Vector__XXX
 SG_ KL_T_Charge : 23|1@1+ (1,0) [0|1] "" Vector__XXX
 SG_ KL_Last_Kompr : 24|8@1+ (0.25,0) [0|63.5] "Unit_NewtoMeter"  TME
 SG_ KL_Spannungs_Anf : 32|2@1+ (1,0) [0|3] "" Vector__XXX
 SG_ KL_Thermomanagement : 34|2@1+ (1,0) [0|3] ""  TME
 SG_ KL_StartStopp_Info : 36|2@1+ (1,0) [0|3] ""  TME
 SG_ KL_Freilauf_Info : 38|2@1+ (1,0) [0|3] "" Vector__XXX
 SG_ KL_Anf_KL : 40|8@1+ (0.4,0) [0|101.6] "Unit_PerCent"  TME
 SG_ KL_el_Zuheizer_Stufe : 48|3@1+ (1,0) [0|7] ""  TME
 SG_ KL_Ausstattung_Klima : 51|3@1+ (1,0) [0|7] "" Vector__XXX
 SG_ KL_Variante_Standheizung : 54|2@1+ (1,0) [0|3] "" Vector__XXX

BO_ 1640 Klima_12: 8 Gateway
 SG_ KL_LRH_Taster : 0|1@1+ (1,0) [0|1] "" Vector__XXX
 SG_ KL_LRH_Stufe : 1|2@1+ (1,0) [0|3] "" Vector__XXX
 SG_ HSH_Taster : 3|2@1+ (1,0) [0|3] "" Vector__XXX
 SG_ FSH_Taster : 5|1@1+ (1,0) [0|1] "" Vector__XXX
 SG_ KL_Zuheizer_Freigabe : 6|1@1+ (1,0) [0|1] ""  TME
 SG_ KL_Beschlagsgefahr : 7|1@1+ (1,0) [0|1] ""  TME
 SG_ KL_SIH_Soll_li : 8|3@1+ (1,0) [0|7] ""  TME
 SG_ KL_SIH_Soll_re : 11|3@1+ (1,0) [0|7] ""  TME
 SG_ KRH_Soll_li : 14|2@1+ (1,0) [0|3] "" Vector__XXX
 SG_ KL_SIL_Soll_li : 16|3@1+ (1,0) [0|7] ""  TME
 SG_ KL_SIL_Soll_re : 19|3@1+ (1,0) [0|7] ""  TME
 SG_ KRH_Soll_re : 22|2@1+ (1,0) [0|3] "" Vector__XXX
 SG_ KL_Geblspng_Soll : 24|8@1+ (0.05,1.45) [1.5|14] "Unit_Volt" Vector__XXX
 SG_ KL_Geblspng_Fond_Soll : 32|8@1+ (0.05,1.45) [1.5|14] "Unit_Volt" Vector__XXX
 SG_ KL_I_Geblaese : 40|8@1+ (0.25,0) [0|63.5] "Unit_Amper" Vector__XXX
 SG_ KL_Kompressorstrom_soll : 48|10@1+ (1,0) [0|1021] ""  TME
 SG_ KL_Umluftklappe_Status : 58|4@1+ (1,0) [0|15] ""  TME
 SG_ KL_PTC_Verbauinfo : 62|2@1+ (1,0) [0|3] "" Vector__XXX

BO_ 1520 Dimmung_01: 8 Gateway_MQB
 SG_ DI_KL_58xd : 0|8@1+ (1,0) [0|253] "" Airbag_MQB
 SG_ DI_KL_58xs : 8|7@1+ (1,0) [0|100] "Unit_PerCent" Vector__XXX
 SG_ DI_Display_Nachtdesign : 15|1@1+ (1,0) [0|1] "" Vector__XXX
 SG_ DI_KL_58xt : 16|7@1+ (1,0) [0|100] "Unit_PerCent" Vector__XXX
 SG_ DI_Fotosensor : 24|16@1+ (1,0) [0|65535] "" Vector__XXX

BO_ 870 Blinkmodi_02: 8 Gateway
 SG_ BM_ZV_auf : 12|1@1+ (1.0,0.0) [0.0|1] ""  ZR_High
 SG_ BM_ZV_zu : 13|1@1+ (1.0,0.0) [0.0|1] ""  ZR_High
 SG_ BM_DWA_ein : 14|1@1+ (1.0,0.0) [0.0|1] ""  ZR_High
 SG_ BM_DWA_Alarm : 15|1@1+ (1.0,0.0) [0.0|1] ""  ZR_High
 SG_ BM_Crash : 16|1@1+ (1.0,0.0) [0.0|1] ""  ZR_High
 SG_ BM_Panik : 17|1@1+ (1.0,0.0) [0.0|1] ""  ZR_High
 SG_ BM_Not_Bremsung : 18|1@1+ (1.0,0.0) [0.0|1] ""  ZR_High
 SG_ BM_GDO : 19|1@1+ (1.0,0.0) [0.0|1] ""  Vector__XXX
 SG_ BM_Warnblinken : 20|1@1+ (1.0,0.0) [0.0|1] ""  ZR_High
 SG_ BM_Taxi_Notalarm : 21|1@1+ (1.0,0.0) [0.0|1] ""  ZR_High
 SG_ BM_Telematik : 22|1@1+ (1.0,0.0) [0.0|1] ""  ZR_High
 SG_ BM_links : 23|1@1+ (1.0,0.0) [0.0|1] ""  ZR_High
 SG_ BM_rechts : 24|1@1+ (1.0,0.0) [0.0|1] ""  ZR_High
 SG_ Blinken_li_Fzg_Takt : 25|1@1+ (1.0,0.0) [0.0|1] ""  ZR_High
 SG_ Blinken_re_Fzg_Takt : 26|1@1+ (1.0,0.0) [0.0|1] ""  ZR_High
 SG_ Blinken_li_Kombi_Takt : 27|1@1+ (1.0,0.0) [0.0|1] ""  ZR_High,ZR_LIMU,ZR_MIB_TOP_ab_Gen3,ZR_Standard
 SG_ Blinken_re_Kombi_Takt : 28|1@1+ (1.0,0.0) [0.0|1] ""  ZR_High,ZR_LIMU,ZR_MIB_TOP_ab_Gen3,ZR_Standard
 SG_ BM_NBA_n_codiert_n_aktiv : 29|1@1+ (1.0,0.0) [0.0|1] ""  Vector__XXX
 SG_ BM_NBA_Status : 30|2@1+ (1.0,0.0) [0.0|3] ""  Vector__XXX
 SG_ BM_WBT_Beleuchtung : 32|1@1+ (1.0,0.0) [0.0|1] ""  ZR_High
 SG_ BM_HD_Oeffnung_angelernt : 33|1@1+ (1.0,0.0) [0.0|1] ""  Vector__XXX
 SG_ BM_Autobahn : 34|1@1+ (1.0,0.0) [0.0|1] ""  ZR_High,ZR_LIMU,ZR_MIB_TOP_ab_Gen3
 SG_ BM_Rollenmodus_Blinken : 35|1@1+ (1.0,0.0) [0.0|1] ""  Vector__XXX
 SG_ BM_Recas : 36|1@1+ (1.0,0.0) [0.0|1] ""  ZR_High
 SG_ BM_Wischblinken : 37|1@1+ (1.0,0.0) [0.0|1] ""  ZR_High
 SG_ BM_Telematik_Abbruchgrund : 38|6@1+ (1.0,0.0) [0.0|63] ""  Vector__XXX
 SG_ BM_PiloPa : 44|1@1+ (1.0,0.0) [0.0|1] ""  ZR_High
 SG_ DWA_Alarmquelle : 59|5@1+ (1.0,0.0) [0.0|31] ""  ZR_High

BO_ 987 Gateway_72: 8 Gateway_MQB
 SG_ BCM_01_alt : 0|1@1+ (1,0) [0|1] "" Airbag_MQB
 SG_ SMLS_01_alt : 1|1@1+ (1,0) [0|1] "" Motor_Diesel_MQB,Motor_Otto_MQB
 SG_ ZV_02_alt : 2|1@1+ (1,0) [0|1] "" Getriebe_DQ_Hybrid_MQB,Getriebe_DQ_MQB,Motor_Diesel_MQB,Motor_Hybrid_MQB,Motor_Otto_MQB
 SG_ Wischer_01_alt : 3|1@1+ (1,0) [0|1] "" Motor_Diesel_MQB,Motor_Hybrid_MQB,Motor_Otto_MQB
 SG_ Anhaenger_01_alt : 4|1@1+ (1,0) [0|1] "" Getriebe_DQ_Hybrid_MQB,Getriebe_DQ_MQB
 SG_ Klima_Sensor_02_alt : 5|1@1+ (1,0) [0|1] "" Getriebe_DQ_Hybrid_MQB,Getriebe_DQ_MQB,Motor_Diesel_MQB,Motor_Hybrid_MQB,Motor_Otto_MQB
 SG_ VSG_01_alt : 6|1@1+ (1,0) [0|1] "" Airbag_MQB
 SG_ Klima_01_alt : 7|1@1+ (1,0) [0|1] "" Vector__XXX
 SG_ WFS_01_alt : 8|1@1+ (1,0) [0|1] "" Vector__XXX
 SG_ Licht_Anf_01_alt : 9|1@1+ (1,0) [0|1] "" Vector__XXX
 SG_ ZV_HFS_offen : 20|1@1+ (1,0) [0|1] "" Vector__XXX
 SG_ ZV_HBFS_offen : 21|1@1+ (1,0) [0|1] "" Vector__XXX
 SG_ VS_VD_offen_ver : 22|1@1+ (1,0) [0|1] "" Airbag_MQB
 SG_ VS_VD_zu_ver : 23|1@1+ (1,0) [0|1] "" Vector__XXX
 SG_ ZV_BT_offen : 24|1@1+ (1,0) [0|1] "" Vector__XXX
 SG_ BCM1_Rueckfahrlicht_Schalter : 25|1@1+ (1,0) [0|1] "" Airbag_MQB
 SG_ ZV_FT_offen : 26|1@1+ (1,0) [0|1] "" Getriebe_DQ_Hybrid_MQB,Getriebe_DQ_MQB,Motor_Diesel_MQB,Motor_Hybrid_MQB,Motor_Otto_MQB
 SG_ Wischer_vorne_aktiv : 27|1@1+ (1,0) [0|1] "" Motor_Diesel_MQB,Motor_Hybrid_MQB,Motor_Otto_MQB
 SG_ AAG_Anhaenger_erkannt : 28|1@1+ (1,0) [0|1] "" Getriebe_DQ_Hybrid_MQB,Getriebe_DQ_MQB
 SG_ BCM1_MH_Schalter : 29|1@1+ (1,0) [0|1] "" Vector__XXX
 SG_ ZV_HD_offen : 30|1@1+ (1,0) [0|1] "" Vector__XXX
 SG_ Waschen_vorne_aktiv : 31|1@1+ (1,0) [0|1] "" Vector__XXX
 SG_ KL_Thermomanagement : 32|2@1+ (1,0) [0|3] "" Vector__XXX
 SG_ WFS_Schluessel_Fahrberecht : 34|4@1+ (1,0) [0|15] "" Vector__XXX
 SG_ BCM1_RFahrlicht_Fzg_Anf : 38|1@1+ (1,0) [0|1] "" Vector__XXX
 SG_ BCM1_RFahrlicht_Ahg_Anf : 39|1@1+ (1,0) [0|1] "" Vector__XXX
 SG_ BH_Fernlicht : 49|1@1+ (1,0) [0|1] "" Vector__XXX
 SG_ BH_Blinker_li : 50|1@1+ (1,0) [0|1] "" Motor_Diesel_MQB,Motor_Otto_MQB
 SG_ BH_Blinker_re : 51|1@1+ (1,0) [0|1] "" Motor_Diesel_MQB,Motor_Otto_MQB
 SG_ BCM1_OBD_FStatus_ATemp : 52|4@1+ (1,0) [0|15] "" Getriebe_DQ_Hybrid_MQB,Getriebe_DQ_MQB,Motor_Diesel_MQB,Motor_Hybrid_MQB,Motor_Otto_MQB
 SG_ BCM1_Aussen_Temp_ungef : 56|8@1+ (0.5,-50) [-50|76] "Unit_DegreCelsi" Getriebe_DQ_Hybrid_MQB,Getriebe_DQ_MQB,Motor_Diesel_MQB,Motor_Hybrid_MQB,Motor_Otto_MQB

BO_ 299 GRA_ACC_01: 8 Gateway
 SG_ CHECKSUM : 0|8@1+ (1,0) [0|255] ""  Vector__XXX
 SG_ COUNTER : 8|4@1+ (1,0) [0|15] ""  Vector__XXX
 SG_ GRA_Hauptschalter : 12|1@1+ (1.0,0.0) [0.0|1] ""  ZR_High
 SG_ GRA_Abbrechen : 13|1@1+ (1.0,0.0) [0.0|1] ""  ZR_High
 SG_ GRA_Typ_Hauptschalter : 14|1@1+ (1.0,0.0) [0.0|1] ""  ZR_High
 SG_ GRA_Limiter : 15|1@1+ (1.0,0.0) [0.0|1] ""  ZR_High
 SG_ GRA_Tip_Setzen : 16|1@1+ (1.0,0.0) [0.0|1] ""  ZR_High
 SG_ GRA_Tip_Hoch : 17|1@1+ (1.0,0.0) [0.0|1] ""  ZR_High
 SG_ GRA_Tip_Runter : 18|1@1+ (1.0,0.0) [0.0|1] ""  ZR_High
 SG_ GRA_Tip_Wiederaufnahme : 19|1@1+ (1.0,0.0) [0.0|1] ""  ZR_High
 SG_ GRA_Verstellung_Zeitluecke : 20|2@1+ (1.0,0.0) [0.0|3] ""  ZR_High
 SG_ GRA_Codierung : 22|2@1+ (1.0,0.0) [0.0|3] ""  ZR_High
 SG_ GRA_Fehler : 24|1@1+ (1.0,0.0) [0.0|1] ""  ZR_High
 SG_ GRA_LIM_Taste_verfuegbar : 25|1@1+ (1.0,0.0) [0.0|1] ""  ZR_High
 SG_ GRA_Tip_Stufe_2 : 26|1@1+ (1.0,0.0) [0.0|1] ""  ZR_High
 SG_ GRA_ButtonTypeInfo : 27|3@1+ (1.0,0.0) [0.0|7] ""  ZR_High
 SG_ GRA_TravelAssist : 30|1@1+ (1.0,0.0) [0.0|1] ""  Vector__XXX
 SG_ GRA_reserveByte4 : 31|1@1+ (1.0,0.0) [0.0|1] ""  Vector__XXX
 SG_ GRA_reserveByte5 : 32|8@1+ (1.0,0.0) [0.0|255] ""  Vector__XXX
 SG_ GRA_reserveByte6 : 40|8@1+ (1.0,0.0) [0.0|255] ""  Vector__XXX
 SG_ GRA_reserveByte7 : 48|8@1+ (1.0,0.0) [0.0|255] ""  Vector__XXX
 SG_ GRA_reserveByte8 : 56|8@1+ (1.0,0.0) [0.0|255] ""  Vector__XXX

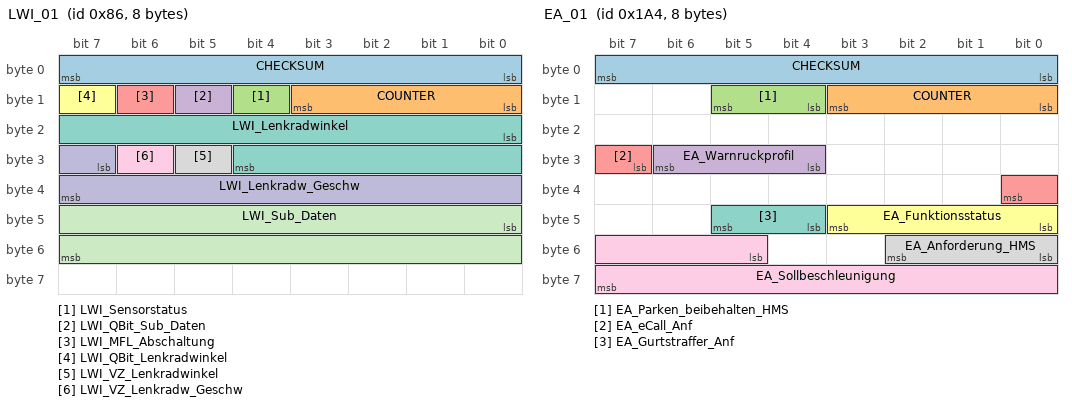
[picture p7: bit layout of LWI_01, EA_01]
BO_ 134 LWI_01: 8 Gateway
 SG_ CHECKSUM : 0|8@1+ (1,0) [0|255] "" Vector__XXX
 SG_ COUNTER : 8|4@1+ (1,0) [0|15] "" Vector__XXX
 SG_ LWI_Sensorstatus : 12|1@1+ (1,0) [0|1] "" ZR_High,ZR_LIMU,ZR_MIB_TOP_ab_Gen3,ZR_Standard
 SG_ LWI_QBit_Sub_Daten : 13|1@1+ (1,0) [0|1] "" ZR_High
 SG_ LWI_MFL_Abschaltung : 14|1@1+ (1,0) [0|1] "" ZR_High
 SG_ LWI_QBit_Lenkradwinkel : 15|1@1+ (1,0) [0|1] "" ZR_High,ZR_LIMU,ZR_MIB_TOP_ab_Gen3,ZR_Standard
 SG_ LWI_Lenkradwinkel : 16|13@1+ (0.0843,0) [0|800] "Unit_DegreOfArc" OTA_FC,ZR_High,ZR_LIMU,ZR_MIB_TOP_ab_Gen3,ZR_Standard
 SG_ LWI_VZ_Lenkradwinkel : 29|1@1+ (1,0) [0|1] "" OTA_FC,ZR_High,ZR_LIMU,ZR_MIB_TOP_ab_Gen3,ZR_Standard
 SG_ LWI_VZ_Lenkradw_Geschw : 30|1@1+ (1,0) [0|1] "" ZR_High
 SG_ LWI_Lenkradw_Geschw : 31|9@1+ (5,0) [0|2500] "Unit_DegreOfArcPerSecon" OTA_FC,ZR_High
 SG_ LWI_Sub_Daten : 40|16@1+ (1,0) [0|65535] "" Vector__XXX

BO_ 420 EA_01: 8 Gateway
 SG_ CHECKSUM : 0|8@1+ (1,0) [0|255] ""  Vector__XXX
 SG_ COUNTER : 8|4@1+ (1,0) [0|15] ""  Vector__XXX
 SG_ EA_Parken_beibehalten_HMS : 12|2@1+ (1.0,0.0) [0.0|3] ""  Vector__XXX
 SG_ EA_Warnruckprofil : 28|3@1+ (1.0,0.0) [0.0|7] ""  Vector__XXX
 SG_ EA_eCall_Anf : 31|2@1+ (1.0,0.0) [0.0|3] ""  ZR_High
 SG_ EA_Funktionsstatus : 40|4@1+ (1.0,0.0) [0.0|15] ""  ZR_High
 SG_ EA_Gurtstraffer_Anf : 44|2@1+ (1.0,0.0) [0.0|3] ""  Vector__XXX
 SG_ EA_Anforderung_HMS : 48|3@1+ (1.0,0.0) [0.0|7] ""  Vector__XXX
 SG_ EA_Sollbeschleunigung : 53|11@1+ (0.005,-7.22) [-7.220|3.005] "Unit_MeterPerSeconSquar"  Vector__XXX

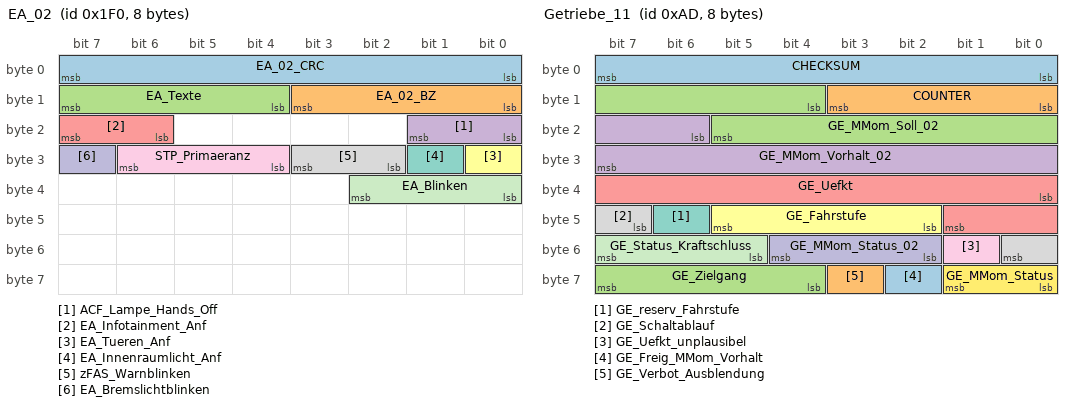
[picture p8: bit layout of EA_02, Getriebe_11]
BO_ 496 EA_02: 8 Gateway
 SG_ EA_02_CRC : 0|8@1+ (1,0) [0|255] ""  Vector__XXX
 SG_ EA_02_BZ : 8|4@1+ (1,0) [0|15] ""  Vector__XXX
 SG_ EA_Texte : 12|4@1+ (1.0,0.0) [0.0|15] ""  ZR_High
 SG_ ACF_Lampe_Hands_Off : 16|2@1+ (1.0,0.0) [0.0|3] ""  Vector__XXX
 SG_ EA_Infotainment_Anf : 22|2@1+ (1.0,0.0) [0.0|3] ""  ZR_High,ZR_LIMU,ZR_MIB_TOP_ab_Gen3,ZR_Standard
 SG_ EA_Tueren_Anf : 24|1@1+ (1.0,0.0) [0.0|1] ""  ZR_High
 SG_ EA_Innenraumlicht_Anf : 25|1@1+ (1.0,0.0) [0.0|1] ""  ZR_High
 SG_ zFAS_Warnblinken : 26|2@1+ (1.0,0.0) [0.0|3] ""  ZR_High
 SG_ STP_Primaeranz : 28|3@1+ (1.0,0.0) [0.0|7] ""  Vector__XXX
 SG_ EA_Bremslichtblinken : 31|1@1+ (1.0,0.0) [0.0|1] ""  Vector__XXX
 SG_ EA_Blinken : 32|3@1+ (1.0,0.0) [0.0|7] ""  Vector__XXX

BO_ 695 RCTA_01: 8 XXX
 SG_ RCTA_01_BZ : 8|4@1+ (1,0) [0|15] "" XXX
 SG_ RCTA_01_CRC : 0|8@1+ (1,0) [0|255] "" XXX

BO_ 173 Getriebe_11: 8 Gateway
 SG_ CHECKSUM : 0|8@1+ (1,0) [0|255] ""  Vector__XXX
 SG_ COUNTER : 8|4@1+ (1,0) [0|15] ""  Vector__XXX
 SG_ GE_MMom_Soll_02 : 12|10@1+ (1,-509) [-509|509] ""  Vector__XXX
 SG_ GE_MMom_Vorhalt_02 : 22|10@1+ (1,-509) [-509|509] ""  Vector__XXX
 SG_ GE_Uefkt : 32|10@1+ (0.1,0) [0.0|102.2] ""  Vector__XXX
 SG_ GE_Fahrstufe : 42|4@1+ (1.0,0.0) [0.0|15] ""  DDA,OTA_FC,ZR_High,ZR_LIMU,ZR_MIB_TOP_ab_Gen3
 SG_ GE_reserv_Fahrstufe : 46|1@1+ (1,0) [0|1] ""  Vector__XXX
 SG_ GE_Schaltablauf : 47|2@1+ (1.0,0.0) [0.0|3] ""  Vector__XXX
 SG_ GE_Uefkt_unplausibel : 49|1@1+ (1.0,0.0) [0.0|1] ""  Vector__XXX
 SG_ GE_MMom_Status_02 : 50|3@1+ (1.0,0.0) [0.0|7] ""  Vector__XXX
 SG_ GE_Status_Kraftschluss : 53|3@1+ (1.0,0.0) [0.0|7] ""  Vector__XXX
 SG_ GE_MMom_Status : 56|2@1+ (1.0,0.0) [0.0|3] ""  Vector__XXX
 SG_ GE_Freig_MMom_Vorhalt : 58|1@1+ (1.0,0.0) [0.0|1] ""  Vector__XXX
 SG_ GE_Verbot_Ausblendung : 59|1@1+ (1.0,0.0) [0.0|1] ""  Vector__XXX
 SG_ GE_Zielgang : 60|4@1+ (1.0,0.0) [0.0|15] ""  OTA_FC,ZR_High

BO_ 1411 ZV_02: 8 Gateway
 SG_ BCM_FH_Freigabe : 12|1@1+ (1.0,0.0) [0.0|1] ""  BedienDisp_vo
 SG_ BCM_Komfortfkt_Freigabe : 13|1@1+ (1.0,0.0) [0.0|1] ""  Vector__XXX
 SG_ BCM_HSK_Freigabe : 14|1@1+ (1.0,0.0) [0.0|1] ""  Vector__XXX
 SG_ BCM_Verdeck_Freigabe : 15|1@1+ (1.0,0.0) [0.0|1] ""  ZR_High
 SG_ ZV_verriegelt_intern_ist : 16|1@1+ (1.0,0.0) [0.0|1] ""  DDA,OTA_FC,ZR_High
 SG_ ZV_verriegelt_extern_ist : 17|1@1+ (1.0,0.0) [0.0|1] ""  DDA,OTA_FC,ZR_High
 SG_ ZV_verriegelt_intern_soll : 18|1@1+ (1.0,0.0) [0.0|1] ""  ZR_High
 SG_ ZV_verriegelt_extern_soll : 19|1@1+ (1.0,0.0) [0.0|1] ""  OTA_FC,ZR_High,ZR_LIMU,ZR_MIB_TOP_ab_Gen3,ZR_Standard
 SG_ ZV_gesafet_extern_ist : 20|1@1+ (1.0,0.0) [0.0|1] ""  ZR_High
 SG_ ZV_gesafet_extern_soll : 21|1@1+ (1.0,0.0) [0.0|1] ""  ZR_High,ZR_LIMU,ZR_MIB_TOP_ab_Gen3
 SG_ ZV_Einzeltuerentriegelung : 22|1@1+ (1.0,0.0) [0.0|1] ""  Vector__XXX
 SG_ ZV_Heckeinzelentriegelung : 23|1@1+ (1.0,0.0) [0.0|1] ""  Vector__XXX
 SG_ ZV_FT_offen : 24|1@1+ (1.0,0.0) [0.0|1] ""  DDA,OTA_FC,ZR_High,ZR_LIMU,ZR_MIB_TOP_ab_Gen3,ZR_Standard
 SG_ ZV_BT_offen : 25|1@1+ (1.0,0.0) [0.0|1] ""  DDA,OTA_FC,ZR_High,ZR_LIMU,ZR_MIB_TOP_ab_Gen3,ZR_Standard
 SG_ ZV_HFS_offen : 26|1@1+ (1.0,0.0) [0.0|1] ""  DDA,OTA_FC,ZR_High,ZR_LIMU,ZR_MIB_TOP_ab_Gen3,ZR_Standard
 SG_ ZV_HBFS_offen : 27|1@1+ (1.0,0.0) [0.0|1] ""  DDA,OTA_FC,ZR_High,ZR_LIMU,ZR_MIB_TOP_ab_Gen3,ZR_Standard
 SG_ ZV_HD_offen : 28|1@1+ (1.0,0.0) [0.0|1] ""  DDA,OTA_FC,ZR_High,ZR_LIMU,ZR_MIB_TOP_ab_Gen3,ZR_Standard
 SG_ ZV_HS_offen : 29|1@1+ (1.0,0.0) [0.0|1] ""  OTA_FC,ZR_High
 SG_ IRUE_aktiv : 30|1@1+ (1.0,0.0) [0.0|1] ""  ZR_High
 SG_ DWA_aktiv : 31|1@1+ (1.0,0.0) [0.0|1] ""  ZR_High
 SG_ HD_Hauptraste : 32|1@1+ (1.0,0.0) [0.0|1] ""  OTA_FC,ZR_High
 SG_ HD_Vorraste : 33|1@1+ (1.0,0.0) [0.0|1] ""  OTA_FC,ZR_High
 SG_ FFB_CarFinder : 38|1@1+ (1.0,0.0) [0.0|1] ""  Vector__XXX
 SG_ FFB_Komfortoeffnen : 39|1@1+ (1.0,0.0) [0.0|1] ""  Vector__XXX
 SG_ FFB_Komfortschliessen : 40|1@1+ (1.0,0.0) [0.0|1] ""  Vector__XXX
 SG_ ZV_Schluessel_Zugang : 42|4@1+ (1.0,0.0) [0.0|15] ""  ZR_High
 SG_ ZV_SafeFunktion_aktiv : 46|1@1+ (1.0,0.0) [0.0|1] ""  ZR_High
 SG_ FBS_Warn_Schluessel_Batt : 47|1@1+ (1.0,0.0) [0.0|1] ""  ZR_High
 SG_ ZV_Oeffnungsmodus : 48|2@1+ (1.0,0.0) [0.0|3] ""  Vector__XXX
 SG_ HFS_verriegelt : 50|1@1+ (1.0,0.0) [0.0|1] ""  OTA_FC
 SG_ HFS_gesafet : 51|1@1+ (1.0,0.0) [0.0|1] ""  Vector__XXX
 SG_ HBFS_verriegelt : 52|1@1+ (1.0,0.0) [0.0|1] ""  OTA_FC
 SG_ HBFS_gesafet : 53|1@1+ (1.0,0.0) [0.0|1] ""  Vector__XXX
 SG_ ZV_ist_Zustand_verfuegbar : 54|1@1+ (1.0,0.0) [0.0|1] ""  OTA_FC,ZR_High
 SG_ IRUE_Taster_Fkts_LED : 55|1@1+ (1.0,0.0) [0.0|1] ""  ZR_High
 SG_ ZV_Tankklappe_offen : 56|1@1+ (1.0,0.0) [0.0|1] ""  ZR_High
 SG_ ZV_Rollo_auf : 57|1@1+ (1.0,0.0) [0.0|1] ""  ZR_High
 SG_ ZV_Rollo_zu : 58|1@1+ (1.0,0.0) [0.0|1] ""  ZR_High
 SG_ ZV_SAD_auf : 59|1@1+ (1.0,0.0) [0.0|1] ""  ZR_High
 SG_ ZV_SAD_zu : 60|1@1+ (1.0,0.0) [0.0|1] ""  ZR_High
 SG_ BCM_Tankklappensteller_Fehler : 61|1@1+ (1.0,0.0) [0.0|1] ""  ZR_High
 SG_ ZV_verriegelt_soll : 62|2@1+ (1.0,0.0) [0.0|3] ""  Vector__XXX

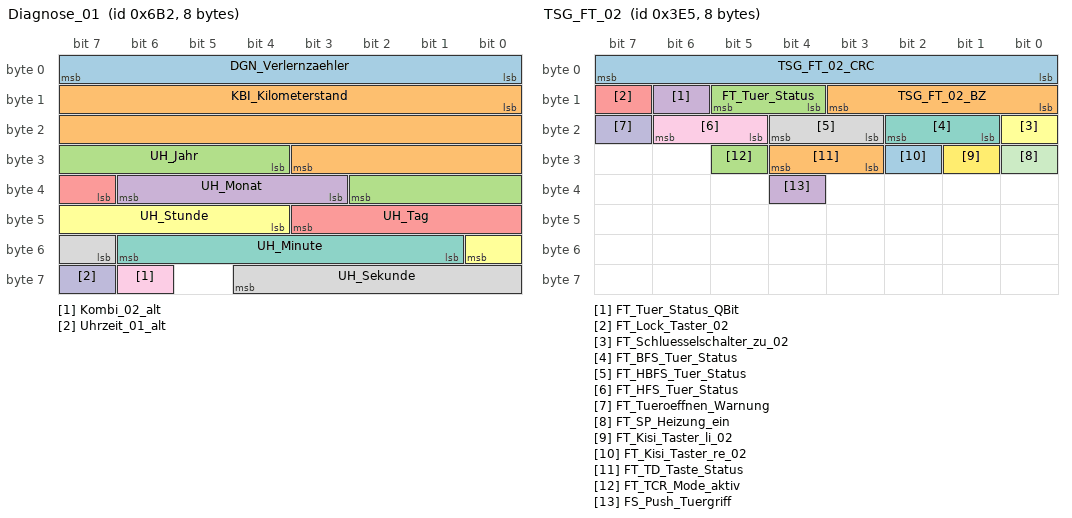
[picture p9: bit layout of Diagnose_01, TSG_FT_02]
BO_ 1714 Diagnose_01: 8 Gateway_MQB
 SG_ DGN_Verlernzaehler : 0|8@1+ (1,0) [0|254] "" Airbag_MQB,BMS_MQB,Getriebe_DQ_Hybrid_MQB,Getriebe_DQ_MQB,LEH_MQB,SAK_MQB
 SG_ KBI_Kilometerstand : 8|20@1+ (1,0) [0|1048573] "Unit_KiloMeter" Airbag_MQB,BMS_MQB,Getriebe_DQ_Hybrid_MQB,Getriebe_DQ_MQB,LEH_MQB,Motor_Diesel_MQB,Motor_Hybrid_MQB,Motor_Otto_MQB,SAK_MQB
 SG_ UH_Jahr : 28|7@1+ (1,2000) [2000|2127] "Unit_Year" Airbag_MQB,BMS_MQB,Getriebe_DQ_Hybrid_MQB,Getriebe_DQ_MQB,LEH_MQB,Motor_Diesel_MQB,Motor_Hybrid_MQB,Motor_Otto_MQB,SAK_MQB
 SG_ UH_Monat : 35|4@1+ (1,0) [1|12] "Unit_Month" Airbag_MQB,BMS_MQB,Getriebe_DQ_Hybrid_MQB,Getriebe_DQ_MQB,LEH_MQB,Motor_Diesel_MQB,Motor_Hybrid_MQB,Motor_Otto_MQB,SAK_MQB
 SG_ UH_Tag : 39|5@1+ (1,0) [1|31] "Unit_Day" Airbag_MQB,BMS_MQB,Getriebe_DQ_Hybrid_MQB,Getriebe_DQ_MQB,LEH_MQB,Motor_Diesel_MQB,Motor_Hybrid_MQB,Motor_Otto_MQB,SAK_MQB
 SG_ UH_Stunde : 44|5@1+ (1,0) [0|23] "Unit_Hours" Airbag_MQB,BMS_MQB,Getriebe_DQ_Hybrid_MQB,Getriebe_DQ_MQB,LEH_MQB,Motor_Diesel_MQB,Motor_Hybrid_MQB,Motor_Otto_MQB,SAK_MQB
 SG_ UH_Minute : 49|6@1+ (1,0) [0|59] "Unit_Minut" Airbag_MQB,BMS_MQB,Getriebe_DQ_Hybrid_MQB,Getriebe_DQ_MQB,LEH_MQB,Motor_Diesel_MQB,Motor_Hybrid_MQB,Motor_Otto_MQB,SAK_MQB
 SG_ UH_Sekunde : 55|6@1+ (1,0) [0|59] "Unit_Secon" Airbag_MQB,BMS_MQB,Getriebe_DQ_Hybrid_MQB,Getriebe_DQ_MQB,LEH_MQB,Motor_Diesel_MQB,Motor_Hybrid_MQB,Motor_Otto_MQB,SAK_MQB
 SG_ Kombi_02_alt : 62|1@1+ (1,0) [0|1] "" Airbag_MQB,BMS_MQB,LEH_MQB
 SG_ Uhrzeit_01_alt : 63|1@1+ (1,0) [0|1] "" Airbag_MQB,BMS_MQB,LEH_MQB

BO_ 1716 VIN_01: 8 Gateway_MQB
 SG_ VIN_01_MUX M : 0|2@1+ (1,0) [0|3] ""  Airbag_MQB
 SG_ KS_Geheimnis_1 m0 : 8|8@1+ (1,0) [0|255] "" Vector__XXX
 SG_ VIN_4 m1 : 8|8@1+ (1,0) [0|255] ""  Airbag_MQB
 SG_ VIN_11 m2 : 8|8@1+ (1,0) [0|255] ""  Airbag_MQB
 SG_ KS_Geheimnis_2 m0 : 16|8@1+ (1,0) [0|255] "" Vector__XXX
 SG_ VIN_5 m1 : 16|8@1+ (1,0) [0|255] ""  Airbag_MQB
 SG_ VIN_12 m2 : 16|8@1+ (1,0) [0|255] ""  Airbag_MQB
 SG_ KS_Geheimnis_3 m0 : 24|8@1+ (1,0) [0|255] "" Vector__XXX
 SG_ VIN_6 m1 : 24|8@1+ (1,0) [0|255] ""  Airbag_MQB
 SG_ VIN_13 m2 : 24|8@1+ (1,0) [0|255] ""  Airbag_MQB
 SG_ KS_Geheimnis_4 m0 : 32|8@1+ (1,0) [0|255] "" Vector__XXX
 SG_ VIN_7 m1 : 32|8@1+ (1,0) [0|255] ""  Airbag_MQB
 SG_ VIN_14 m2 : 32|8@1+ (1,0) [0|255] ""  Airbag_MQB
 SG_ VIN_1 m0 : 40|8@1+ (1,0) [0|255] ""  Airbag_MQB
 SG_ VIN_8 m1 : 40|8@1+ (1,0) [0|255] ""  Airbag_MQB
 SG_ VIN_15 m2 : 40|8@1+ (1,0) [0|255] ""  Airbag_MQB
 SG_ VIN_2 m0 : 48|8@1+ (1,0) [0|255] ""  Airbag_MQB
 SG_ VIN_9 m1 : 48|8@1+ (1,0) [0|255] ""  Airbag_MQB
 SG_ VIN_16 m2 : 48|8@1+ (1,0) [0|255] ""  Airbag_MQB
 SG_ VIN_3 m0 : 56|8@1+ (1,0) [0|255] ""  Airbag_MQB
 SG_ VIN_10 m1 : 56|8@1+ (1,0) [0|255] ""  Airbag_MQB
 SG_ VIN_17 m2 : 56|8@1+ (1,0) [0|255] ""  Airbag_MQB

BO_ 974 TSG_HFS_01: 8 Gateway
 SG_ HFS_Tuer_geoeffnet : 0|1@1+ (1,0) [0|1] "" Vector__XXX
 SG_ HFS_verriegelt : 1|1@1+ (1,0) [0|1] "" Vector__XXX
 SG_ HFS_gesafet : 2|1@1+ (1,0) [0|1] "" Vector__XXX
 SG_ HFS_Heckrollotaster_betaetigt : 3|1@1+ (1,0) [0|1] "" Vector__XXX
 SG_ HFS_Tuerschloss_defekt : 4|1@1+ (1,0) [0|1] "" Vector__XXX
 SG_ HFS_Unlock_Taster : 5|1@1+ (1,0) [0|1] "" Vector__XXX
 SG_ HFS_Lock_Taster : 6|1@1+ (1,0) [0|1] "" Vector__XXX
 SG_ HFS_Sperrklinke : 7|1@1+ (1,0) [0|1] "" Vector__XXX
 SG_ HFS_TAG_betaetigt : 8|1@1+ (1,0) [0|1] "" Vector__XXX
 SG_ HFS_TIG_betaetigt : 9|1@1+ (1,0) [0|1] "" Vector__XXX
 SG_ HFS_FH_S_HBFS_AutoHoch : 10|1@1+ (1,0) [0|1] "" Vector__XXX
 SG_ HFS_FH_S_HBFS_AutoTief : 11|1@1+ (1,0) [0|1] "" Vector__XXX
 SG_ HFS_FH_S_HBFS_ManHoch : 12|1@1+ (1,0) [0|1] "" Vector__XXX
 SG_ HFS_FH_S_HBFS_ManTief : 13|1@1+ (1,0) [0|1] "" Vector__XXX
 SG_ HFS_Tuer_Status : 14|2@1+ (1,0) [0|3] "" Vector__XXX
 SG_ HFS_SAD_Schalter : 16|4@1+ (1,0) [0|15] "" Vector__XXX
 SG_ HFS_FH_S_ManHoch : 20|1@1+ (1,0) [0|1] "" Vector__XXX
 SG_ HFS_FH_S_AutoHoch : 21|1@1+ (1,0) [0|1] "" Vector__XXX
 SG_ HFS_FH_S_ManTief : 22|1@1+ (1,0) [0|1] "" Vector__XXX
 SG_ HFS_FH_S_AutoTief : 23|1@1+ (1,0) [0|1] "" Vector__XXX
 SG_ HFS_FH_Oeffnung : 24|8@1+ (0.5,0) [0|100] "Unit_PerCent" Vector__XXX
 SG_ HFS_FH_Bew_hoch : 32|1@1+ (1,0) [0|1] "" Vector__XXX
 SG_ HFS_FH_Bew_tief : 33|1@1+ (1,0) [0|1] "" Vector__XXX
 SG_ HFS_FH_Fang : 34|1@1+ (1,0) [0|1] "" Vector__XXX
 SG_ HFS_FH_Block : 35|1@1+ (1,0) [0|1] "" Vector__XXX
 SG_ HFS_FH_Thermo : 36|1@1+ (1,0) [0|1] "" Vector__XXX
 SG_ HFS_UEKB_aktiviert : 37|1@1+ (1,0) [0|1] "" Vector__XXX
 SG_ HFS_Tueroeffnen_Warnung : 38|1@1+ (1,0) [0|1] "" Vector__XXX
 SG_ HFS_FH_normiert : 39|1@1+ (1,0) [0|1] "" Vector__XXX
 SG_ ASW_Warnung_aktiv_HFS : 40|1@1+ (1,0) [0|1] "" Vector__XXX
 SG_ HFS_Zuziehhilfe_aktiv : 41|1@1+ (1,0) [0|1] "" Vector__XXX
 SG_ HFS_Seitenrollo_hoch : 42|1@1+ (1,0) [0|1] ""  TME
 SG_ HFS_Seitenrollo_tief : 43|1@1+ (1,0) [0|1] ""  TME
 SG_ HFS_Status_KiSi : 44|1@1+ (1,0) [0|1] "" Vector__XXX
 SG_ SSR_HFS_Pos_Unten : 45|1@1+ (1,0) [0|1] "" Vector__XXX
 SG_ HFS_Oben_Block_erw : 46|1@1+ (1,0) [0|1] "" Vector__XXX
 SG_ HFS_Unten_Block_erw : 47|1@1+ (1,0) [0|1] "" Vector__XXX
 SG_ MTHFS_M_Taste : 48|1@1+ (1,0) [0|1] "" Vector__XXX
 SG_ MTHFS_Pos1 : 49|1@1+ (1,0) [0|1] "" Vector__XXX
 SG_ MTHFS_Pos2 : 50|1@1+ (1,0) [0|1] "" Vector__XXX
 SG_ MTHFS_Pos3 : 51|1@1+ (1,0) [0|1] "" Vector__XXX
 SG_ HFS_MRollo_Schalter : 52|3@1+ (1,0) [0|7] "" Vector__XXX
 SG_ HFS_Lock_Taster_inv : 55|1@1+ (1,0) [0|1] "" Vector__XXX
 SG_ HFS_Status_eTAG : 56|2@1+ (1,0) [0|3] "" Vector__XXX
 SG_ HFS_Tuer_Status_QBit : 58|1@1+ (1,0) [0|1] "" Vector__XXX
 SG_ HFS_TCR_Mode_aktiv : 59|1@1+ (1,0) [0|1] "" Vector__XXX

BO_ 975 TSG_HBFS_01: 8 Gateway
 SG_ HBFS_Tuer_geoeffnet : 0|1@1+ (1,0) [0|1] "" Vector__XXX
 SG_ HBFS_verriegelt : 1|1@1+ (1,0) [0|1] "" Vector__XXX
 SG_ HBFS_gesafet : 2|1@1+ (1,0) [0|1] "" Vector__XXX
 SG_ HBFS_Heckrollotaster_betaetigt : 3|1@1+ (1,0) [0|1] "" Vector__XXX
 SG_ HBFS_Tuerschloss_defekt : 4|1@1+ (1,0) [0|1] "" Vector__XXX
 SG_ HBFS_Unlock_Taster : 5|1@1+ (1,0) [0|1] "" Vector__XXX
 SG_ HBFS_Lock_Taster : 6|1@1+ (1,0) [0|1] "" Vector__XXX
 SG_ HBFS_Sperrklinke : 7|1@1+ (1,0) [0|1] "" Vector__XXX
 SG_ HBFS_TAG_betaetigt : 8|1@1+ (1,0) [0|1] "" Vector__XXX
 SG_ HBFS_TIG_betaetigt : 9|1@1+ (1,0) [0|1] "" Vector__XXX
 SG_ HBFS_FH_S_HFS_AutoHoch : 10|1@1+ (1,0) [0|1] "" Vector__XXX
 SG_ HBFS_FH_S_HFS_AutoTief : 11|1@1+ (1,0) [0|1] "" Vector__XXX
 SG_ HBFS_FH_S_HFS_ManHoch : 12|1@1+ (1,0) [0|1] "" Vector__XXX
 SG_ HBFS_FH_S_HFS_ManTief : 13|1@1+ (1,0) [0|1] "" Vector__XXX
 SG_ HBFS_Tuer_Status : 14|2@1+ (1,0) [0|3] "" Vector__XXX
 SG_ HBFS_SAD_Schalter : 16|4@1+ (1,0) [0|15] "" Vector__XXX
 SG_ HBFS_FH_S_ManHoch : 20|1@1+ (1,0) [0|1] "" Vector__XXX
 SG_ HBFS_FH_S_AutoHoch : 21|1@1+ (1,0) [0|1] "" Vector__XXX
 SG_ HBFS_FH_S_ManTief : 22|1@1+ (1,0) [0|1] "" Vector__XXX
 SG_ HBFS_FH_S_AutoTief : 23|1@1+ (1,0) [0|1] "" Vector__XXX
 SG_ HBFS_FH_Oeffnung : 24|8@1+ (0.5,0) [0|100] "Unit_PerCent" Vector__XXX
 SG_ HBFS_FH_Bew_hoch : 32|1@1+ (1,0) [0|1] "" Vector__XXX
 SG_ HBFS_FH_Bew_tief : 33|1@1+ (1,0) [0|1] "" Vector__XXX
 SG_ HBFS_FH_Fang : 34|1@1+ (1,0) [0|1] "" Vector__XXX
 SG_ HBFS_FH_Block : 35|1@1+ (1,0) [0|1] "" Vector__XXX
 SG_ HBFS_FH_Thermo : 36|1@1+ (1,0) [0|1] "" Vector__XXX
 SG_ HBFS_UEKB_aktiviert : 37|1@1+ (1,0) [0|1] "" Vector__XXX
 SG_ HBFS_Tueroeffnen_Warnung : 38|1@1+ (1,0) [0|1] "" Vector__XXX
 SG_ HBFS_FH_normiert : 39|1@1+ (1,0) [0|1] "" Vector__XXX
 SG_ ASW_Warnung_aktiv_HBFS : 40|1@1+ (1,0) [0|1] "" Vector__XXX
 SG_ HBFS_Zuziehhilfe_aktiv : 41|1@1+ (1,0) [0|1] "" Vector__XXX
 SG_ HBFS_Seitenrollo_hoch : 42|1@1+ (1,0) [0|1] ""  TME
 SG_ HBFS_Seitenrollo_tief : 43|1@1+ (1,0) [0|1] ""  TME
 SG_ HBFS_Status_KiSi : 44|1@1+ (1,0) [0|1] "" Vector__XXX
 SG_ SSR_HBFS_Pos_Unten : 45|1@1+ (1,0) [0|1] "" Vector__XXX
 SG_ HBFS_Oben_Block_erw : 46|1@1+ (1,0) [0|1] "" Vector__XXX
 SG_ HBFS_Unten_Block_erw : 47|1@1+ (1,0) [0|1] "" Vector__XXX
 SG_ MTHBFS_M_Taste : 48|1@1+ (1,0) [0|1] "" Vector__XXX
 SG_ MTHBFS_Pos1 : 49|1@1+ (1,0) [0|1] "" Vector__XXX
 SG_ MTHBFS_Pos2 : 50|1@1+ (1,0) [0|1] "" Vector__XXX
 SG_ MTHBFS_Pos3 : 51|1@1+ (1,0) [0|1] "" Vector__XXX
 SG_ HBFS_MRollo_Schalter : 52|3@1+ (1,0) [0|7] "" Vector__XXX
 SG_ HBFS_Lock_Taster_inv : 55|1@1+ (1,0) [0|1] "" Vector__XXX
 SG_ HBFS_Status_KiSi_inv : 56|1@1+ (1,0) [0|1] "" Vector__XXX
 SG_ HBFS_Status_eTAG : 57|2@1+ (1,0) [0|3] "" Vector__XXX
 SG_ HBFS_Tuer_Status_QBit : 59|1@1+ (1,0) [0|1] "" Vector__XXX
 SG_ HBFS_TIG_betaetigt_schliessen : 60|1@1+ (1,0) [0|1] "" Vector__XXX

BO_ 976 TSG_FT_01: 8 Gateway
 SG_ FT_Tuer_geoeffnet : 0|1@1+ (1,0) [0|1] ""  Ladegeraet_Konzern,TME
 SG_ FT_verriegelt : 1|1@1+ (1,0) [0|1] "" Vector__XXX
 SG_ FT_gesafet : 2|1@1+ (1,0) [0|1] "" Vector__XXX
 SG_ FT_Schluesselschalter_auf : 3|1@1+ (1,0) [0|1] ""  FCU_MLBevo_FCEV
 SG_ FT_Schluesselschalter_zu : 4|1@1+ (1,0) [0|1] ""  FCU_MLBevo_FCEV
 SG_ FT_Unlock_Taster : 5|1@1+ (1,0) [0|1] "" Vector__XXX
 SG_ FT_Lock_Taster : 6|1@1+ (1,0) [0|1] "" Vector__XXX
 SG_ FT_Sperrklinke : 7|1@1+ (1,0) [0|1] "" Vector__XXX
 SG_ FT_TAG_betaetigt : 8|1@1+ (1,0) [0|1] "" Vector__XXX
 SG_ FT_TIG_betaetigt : 9|1@1+ (1,0) [0|1] "" Vector__XXX
 SG_ FT_IRUE_Taste : 10|1@1+ (1,0) [0|1] "" Vector__XXX
 SG_ FT_HD_Taste : 11|1@1+ (1,0) [0|1] "" Vector__XXX
 SG_ FT_TD_Taste_Fehler : 12|1@1+ (1,0) [0|1] ""  Ladegeraet_Konzern
 SG_ FT_TD_Taste : 13|1@1+ (1,0) [0|1] ""  FCU_MLBevo_FCEV,Ladegeraet_Konzern
 SG_ SSR_Temp_Freigabe : 14|1@1+ (1,0) [0|1] "" Vector__XXX
 SG_ FT_Sp_Heizung_Anf : 15|1@1+ (100,0) [0|100] "Unit_PerCent" Vector__XXX
 SG_ FT_HD_Taste_2 : 16|1@1+ (1,0) [0|1] "" Vector__XXX
 SG_ FT_TSG_hinten_verbaut : 18|1@1+ (1,0) [0|1] "" Vector__XXX
 SG_ FT_Sp_Blk_def : 19|1@1+ (1,0) [0|1] "" Vector__XXX
 SG_ FT_FH_S_ManHoch : 20|1@1+ (1,0) [0|1] "" Vector__XXX
 SG_ FT_FH_S_AutoHoch : 21|1@1+ (1,0) [0|1] "" Vector__XXX
 SG_ FT_FH_S_ManTief : 22|1@1+ (1,0) [0|1] "" Vector__XXX
 SG_ FT_FH_S_AutoTief : 23|1@1+ (1,0) [0|1] "" Vector__XXX
 SG_ FT_FH_Oeffnung : 24|8@1+ (0.5,0) [0|100] "Unit_PerCent"  TME
 SG_ FT_FH_Bew_hoch : 32|1@1+ (1,0) [0|1] "" Vector__XXX
 SG_ FT_FH_Bew_tief : 33|1@1+ (1,0) [0|1] "" Vector__XXX
 SG_ FT_FH_Fang : 34|1@1+ (1,0) [0|1] "" Vector__XXX
 SG_ FT_FH_Block : 35|1@1+ (1,0) [0|1] "" Vector__XXX
 SG_ FT_FH_Thermo : 36|1@1+ (1,0) [0|1] "" Vector__XXX
 SG_ FT_UEKB_aktiviert : 37|1@1+ (1,0) [0|1] "" Vector__XXX
 SG_ ASW_HMI_defekt : 38|1@1+ (1,0) [0|1] "" Vector__XXX
 SG_ FT_FH_normiert : 39|1@1+ (1,0) [0|1] "" Vector__XXX
 SG_ FT_Schliesstaster : 40|1@1+ (1,0) [0|1] "" Vector__XXX
 SG_ FT_Zuziehhilfe_aktiv : 41|1@1+ (1,0) [0|1] "" Vector__XXX
 SG_ FT_SP_ausgerastet : 42|1@1+ (1,0) [0|1] "" Vector__XXX
 SG_ FT_SP_lr_aktiv : 43|1@1+ (1,0) [0|1] "" Vector__XXX
 SG_ FT_SP_ht_aktiv : 44|1@1+ (1,0) [0|1] "" Vector__XXX
 SG_ ASW_wakeup : 45|1@1+ (1,0) [0|1] "" Vector__XXX
 SG_ FT_Oben_Block_erw : 46|1@1+ (1,0) [0|1] "" Vector__XXX
 SG_ FT_Unten_Block_erw : 47|1@1+ (1,0) [0|1] "" Vector__XXX
 SG_ FT_Kisi_li_aktiv : 48|1@1+ (1,0) [0|1] "" Vector__XXX
 SG_ FT_Kisi_re_aktiv : 49|1@1+ (1,0) [0|1] "" Vector__XXX
 SG_ FT_Kisi_Taster_li : 50|1@1+ (1,0) [0|1] "" Vector__XXX
 SG_ FT_Kisi_Taster_re : 51|1@1+ (1,0) [0|1] "" Vector__XXX
 SG_ FT_BFS_Fond_Freigabe : 52|1@1+ (1,0) [0|1] "" Vector__XXX
 SG_ FT_Kisi_Fehler : 53|1@1+ (1,0) [0|1] "" Vector__XXX
 SG_ FT_Daemmglas : 54|1@1+ (1,0) [0|1] "" Vector__XXX
 SG_ FT_SP_Heizung_Status : 55|1@1+ (1,0) [0|1] "" Vector__XXX
 SG_ ASW_Warnung_aktiv_FS : 56|1@1+ (1,0) [0|1] "" Vector__XXX
 SG_ FT_FH_Pos_oben : 57|1@1+ (1,0) [0|1] "" Vector__XXX
 SG_ FT_Tuerschloss_defekt : 58|1@1+ (1,0) [0|1] "" Vector__XXX
 SG_ FT_SWA_Taster : 59|1@1+ (1,0) [0|1] "" Vector__XXX
 SG_ SWA_HMI_Diagnose : 60|2@1+ (1,0) [0|3] "" Vector__XXX
 SG_ FS_Status_eTAG : 62|2@1+ (1,0) [0|3] "" Vector__XXX

BO_ 997 TSG_FT_02: 8 Gateway
 SG_ TSG_FT_02_CRC : 0|8@1+ (1,0) [0|255] ""  Vector__XXX
 SG_ TSG_FT_02_BZ : 8|4@1+ (1,0) [0|15] ""  Vector__XXX
 SG_ FT_Tuer_Status : 12|2@1+ (1.0,0.0) [0.0|3] ""  OTA_FC,ZR_High
 SG_ FT_Tuer_Status_QBit : 14|1@1+ (1.0,0.0) [0.0|1] ""  ZR_High
 SG_ FT_Lock_Taster_02 : 15|1@1+ (1.0,0.0) [0.0|1] ""  ZR_High
 SG_ FT_Schluesselschalter_zu_02 : 16|1@1+ (1.0,0.0) [0.0|1] ""  ZR_High
 SG_ FT_BFS_Tuer_Status : 17|2@1+ (1.0,0.0) [0.0|3] ""  ZR_High
 SG_ FT_HBFS_Tuer_Status : 19|2@1+ (1.0,0.0) [0.0|3] ""  ZR_High
 SG_ FT_HFS_Tuer_Status : 21|2@1+ (1.0,0.0) [0.0|3] ""  ZR_High
 SG_ FT_Tueroeffnen_Warnung : 23|1@1+ (1.0,0.0) [0.0|1] ""  Vector__XXX
 SG_ FT_SP_Heizung_ein : 24|1@1+ (1.0,0.0) [0.0|1] ""  Vector__XXX
 SG_ FT_Kisi_Taster_li_02 : 25|1@1+ (1.0,0.0) [0.0|1] ""  ZR_High
 SG_ FT_Kisi_Taster_re_02 : 26|1@1+ (1.0,0.0) [0.0|1] ""  ZR_High
 SG_ FT_TD_Taste_Status : 27|2@1+ (1.0,0.0) [0.0|3] ""  ZR_High
 SG_ FT_TCR_Mode_aktiv : 29|1@1+ (1.0,0.0) [0.0|1] ""  Vector__XXX
 SG_ FS_Push_Tuergriff : 36|1@1+ (1.0,0.0) [0.0|1] ""  Vector__XXX

BO_ 64 Airbag_01: 8 Gateway
 SG_ Airbag_01_CRC : 0|8@1+ (1,0) [0|255] ""  AWC,BMC_MLBevo,BMS_NV,DCDC_800V_PAG,DCDC_HV,DCDC_HV_02,DCDC_IHEV,FCU_MLBevo_FCEV,Ladegeraet_2,Ladegeraet_Konzern,Sub_Gateway
 SG_ Airbag_01_BZ : 8|4@1+ (1,0) [0|15] ""  AWC,BMC_MLBevo,BMS_NV,DCDC_800V_PAG,DCDC_HV,DCDC_HV_02,DCDC_IHEV,FCU_MLBevo_FCEV,Ladegeraet_2,Ladegeraet_Konzern,Sub_Gateway
 SG_ AB_RGS_Anst : 12|4@1+ (1,0) [0|15] ""  FCU_MLBevo_FCEV,Sub_Gateway
 SG_ AB_Front_Crash : 16|1@1+ (1,0) [0|1] ""  FCU_MLBevo_FCEV,Sub_Gateway
 SG_ AB_Heck_Crash : 17|1@1+ (1,0) [0|1] ""  FCU_MLBevo_FCEV,Sub_Gateway
 SG_ AB_SF_Crash : 18|1@1+ (1,0) [0|1] ""  FCU_MLBevo_FCEV,Sub_Gateway
 SG_ AB_SB_Crash : 19|1@1+ (1,0) [0|1] ""  FCU_MLBevo_FCEV,Sub_Gateway
 SG_ AB_Rollover_Crash : 20|1@1+ (1,0) [0|1] ""  FCU_MLBevo_FCEV,Sub_Gateway
 SG_ AB_Crash_Int : 21|3@1+ (1,0) [0|7] ""  FCU_MLBevo_FCEV,Sub_Gateway,TME
 SG_ AB_Lampe : 24|1@1+ (1,0) [0|1] ""  FCU_MLBevo_FCEV,Sub_Gateway
 SG_ AB_Deaktiviert : 25|1@1+ (1,0) [0|1] ""  FCU_MLBevo_FCEV,Sub_Gateway
 SG_ AB_VB_deaktiviert : 26|1@1+ (1,0) [0|1] ""  FCU_MLBevo_FCEV,Sub_Gateway
 SG_ AB_Systemfehler : 27|1@1+ (1,0) [0|1] ""  FCU_MLBevo_FCEV,Sub_Gateway
 SG_ AB_Diagnose : 28|1@1+ (1,0) [0|1] ""  FCU_MLBevo_FCEV,Sub_Gateway
 SG_ AB_Stellgliedtest : 29|1@1+ (1,0) [0|1] ""  FCU_MLBevo_FCEV,Sub_Gateway,TME
 SG_ AB_Erh_Auf_VB : 30|2@1+ (1,0) [0|3] ""  FCU_MLBevo_FCEV,Sub_Gateway
 SG_ AB_Gurtwarn_VF : 32|1@1+ (1,0) [0|1] ""  FCU_MLBevo_FCEV,Sub_Gateway
 SG_ AB_Gurtwarn_VB : 33|1@1+ (1,0) [0|1] ""  FCU_MLBevo_FCEV,Sub_Gateway
 SG_ AB_Anzeige_Fussg : 34|2@1+ (1,0) [0|3] ""  FCU_MLBevo_FCEV,Sub_Gateway
 SG_ AB_Texte_AKS : 36|2@1+ (1,0) [0|3] ""  FCU_MLBevo_FCEV,Sub_Gateway
 SG_ AB_MKB_gueltig : 39|1@1+ (1,0) [0|1] ""  FCU_MLBevo_FCEV,Sub_Gateway
 SG_ AB_MKB_Anforderung : 40|1@1+ (1,0) [0|1] ""  FCU_MLBevo_FCEV,Sub_Gateway
 SG_ AB_Versorgungsspannung : 41|1@1+ (1,0) [0|1] ""  FCU_MLBevo_FCEV,Sub_Gateway
 SG_ AB_Deaktivierung_HV : 42|3@1+ (1,0) [0|7] ""  AWC,BMC_MLBevo,BMS_NV,DCDC_800V_PAG,DCDC_HV,DCDC_HV_02,DCDC_IHEV,FCU_MLBevo_FCEV,Ladegeraet_2,Ladegeraet_Konzern,Sub_Gateway,TME
 SG_ AB_EDR_Trigger : 45|2@1+ (1,0) [0|3] ""  FCU_MLBevo_FCEV,Sub_Gateway
 SG_ AB_Belegung_VF : 47|2@1+ (1,0) [0|3] ""  FCU_MLBevo_FCEV,Sub_Gateway
 SG_ SC_Masterzeit_Offset : 53|2@1+ (5.08,0) [0|15.24] "Unit_Secon"  FCU_MLBevo_FCEV,Sub_Gateway
 SG_ SC_LowSpeedCrashErkannt : 55|2@1+ (1,0) [0|3] ""  FCU_MLBevo_FCEV,Sub_Gateway
 SG_ SC_Masterzeit : 57|7@1+ (0.04,0) [0|5.04] "Unit_Secon"  FCU_MLBevo_FCEV,Sub_Gateway

BO_ 1312 Airbag_02: 8 Gateway
 SG_ LoGeWa_Event_Kombiwarnung : 12|4@1+ (1.0,0.0) [0.0|15] ""  ZR_High
 SG_ AB_Anforderung_eCall : 16|1@1+ (1.0,0.0) [0.0|1] ""  ZR_High
 SG_ AB_Anprall_Seite_Beifahrer : 17|1@1+ (1.0,0.0) [0.0|1] ""  Vector__XXX
 SG_ AB_Anprall_Rollover : 18|1@1+ (1.0,0.0) [0.0|1] ""  Vector__XXX
 SG_ AB_Anprall_FGS : 19|1@1+ (1.0,0.0) [0.0|1] ""  Vector__XXX
 SG_ AB_Anprall_Front_Beifahrer : 20|1@1+ (1.0,0.0) [0.0|1] ""  Vector__XXX
 SG_ AB_Anprall_Front_Fahrer : 21|1@1+ (1.0,0.0) [0.0|1] ""  Vector__XXX
 SG_ AB_Anprall_Heck_Beifahrer : 22|1@1+ (1.0,0.0) [0.0|1] ""  Vector__XXX
 SG_ AB_Anprall_Heck_Fahrer : 23|1@1+ (1.0,0.0) [0.0|1] ""  Vector__XXX
 SG_ AB_Wickelklappung_Reihe2_MI : 24|2@1+ (1.0,0.0) [0.0|3] ""  Vector__XXX
 SG_ AB_Belegung_VB : 26|2@1+ (1.0,0.0) [0.0|3] ""  BedienSG_hi,GurtMikrofon,ZR_High,ZR_LIMU,ZR_MIB_TOP_ab_Gen3
 SG_ AB_Abschaltanf_SIH_BF : 28|1@1+ (1.0,0.0) [0.0|1] ""  ZR_High
 SG_ AB_Anprall_Seite_Fahrer : 29|1@1+ (1.0,0.0) [0.0|1] ""  Vector__XXX
 SG_ SC_PAO_Schriftzug_Anf : 30|2@1+ (1.0,0.0) [0.0|3] ""  ZR_High
 SG_ SC_PAO_ON_Anf : 32|2@1+ (1.0,0.0) [0.0|3] ""  ZR_High
 SG_ SC_PAO_OFF_Anf : 34|2@1+ (1.0,0.0) [0.0|3] ""  ZR_High
 SG_ AB_Crashschwere : 36|3@1+ (1.0,0.0) [0.0|7] ""  Vector__XXX
 SG_ AB_Anforderung_USM : 39|1@1+ (1.0,0.0) [0.0|1] ""  ZR_Standard
 SG_ AB_Gurtschloss_FA : 40|2@1+ (1.0,0.0) [0.0|3] ""  BedienSG_hi,GurtMikrofon,ZR_High
 SG_ AB_Gurtschloss_BF : 42|2@1+ (1.0,0.0) [0.0|3] ""  BedienSG_hi,GurtMikrofon,ZR_High,ZR_LIMU,ZR_MIB_TOP_ab_Gen3
 SG_ AB_Gurtschloss_Reihe2_FA : 44|2@1+ (1.0,0.0) [0.0|3] ""  BedienSG_hi,ZR_High,ZR_LIMU,ZR_MIB_TOP_ab_Gen3
 SG_ AB_Gurtschloss_Reihe2_MI : 46|2@1+ (1.0,0.0) [0.0|3] ""  BedienSG_hi,ZR_High,ZR_LIMU,ZR_MIB_TOP_ab_Gen3
 SG_ AB_Gurtschloss_Reihe2_BF : 48|2@1+ (1.0,0.0) [0.0|3] ""  BedienSG_hi,ZR_High,ZR_LIMU,ZR_MIB_TOP_ab_Gen3
 SG_ AB_Gurtschloss_Reihe3_FA : 50|2@1+ (1.0,0.0) [0.0|3] ""  BedienSG_hi,ZR_High
 SG_ AB_Gurtschloss_Reihe3_MI : 52|2@1+ (1.0,0.0) [0.0|3] ""  BedienSG_hi,ZR_High
 SG_ AB_Gurtschloss_Reihe3_BF : 54|2@1+ (1.0,0.0) [0.0|3] ""  BedienSG_hi,ZR_High
 SG_ AB_Sitzpos_Sens_FA : 56|2@1+ (1.0,0.0) [0.0|3] ""  ZR_High
 SG_ AB_Sitzpos_Sens_BF : 58|2@1+ (1.0,0.0) [0.0|3] ""  ZR_High
 SG_ AB_Wickelklappung_Reihe2_BF : 60|2@1+ (1.0,0.0) [0.0|3] ""  ZR_High
 SG_ AB_Wickelklappung_Reihe2_FA : 62|2@1+ (1.0,0.0) [0.0|3] ""  ZR_High

BO_ 1601 Motor_Code_01: 8 Motor_Diesel_MQB
 SG_ Motor_Code_01_CRC : 0|8@1+ (1,0) [0|255] "" Gateway_MQB
 SG_ Motor_Code_01_BZ : 8|4@1+ (1,0) [0|15] "" Gateway_MQB
 SG_ MO_Faktor_Momente_02 : 12|2@1+ (1,0) [0|3] "" Gateway_MQB,Getriebe_DQ_Hybrid_MQB,Getriebe_DQ_MQB
 SG_ MO_Hybridfahrzeug : 14|2@1+ (1,0) [0|3] "" Gateway_MQB
 SG_ MO_Code : 16|8@1+ (1,0) [0|255] "" Gateway_MQB,SAK_MQB
 SG_ MO_Getriebe_Code : 24|6@1+ (1,0) [0|63] "" Gateway_MQB
 SG_ MO_StartStopp_Codiert : 30|1@1+ (1,0) [0|1] "" Gateway_MQB
 SG_ MO_Anzahl_Zyl : 32|4@1+ (1,0) [0|15] "" Gateway_MQB
 SG_ MO_Kraftstoffart : 36|4@1+ (1,0) [0|15] "" Gateway_MQB,Getriebe_DQ_Hybrid_MQB,Getriebe_DQ_MQB
 SG_ MO_Hubraum : 40|7@1+ (0.1,0) [0|12.7] "Unit_Liter" Gateway_MQB
 SG_ MO_Ansaugsystem : 47|1@1+ (1,0) [0|1] "" Gateway_MQB
 SG_ MO_Leistung : 48|9@1+ (1,0) [0|511] "Unit_KiloWatt" Gateway_MQB
 SG_ MO_Abgastyp_EOBD : 57|1@1+ (1,0) [0|1] "" BMS_MQB,Gateway_MQB,LEH_MQB
 SG_ MO_Abgastyp_OBD : 58|1@1+ (1,0) [0|1] "" BMS_MQB,Gateway_MQB,LEH_MQB
 SG_ MO_DPF_verbaut : 59|1@1+ (1,0) [0|1] "" Gateway_MQB
 SG_ TSK_Codierung : 60|3@1+ (1,0) [0|7] "" Gateway_MQB,Getriebe_DQ_Hybrid_MQB,Getriebe_DQ_MQB
 SG_ MO_Einspritzart : 63|1@1+ (1,0) [0|1] "" Gateway_MQB

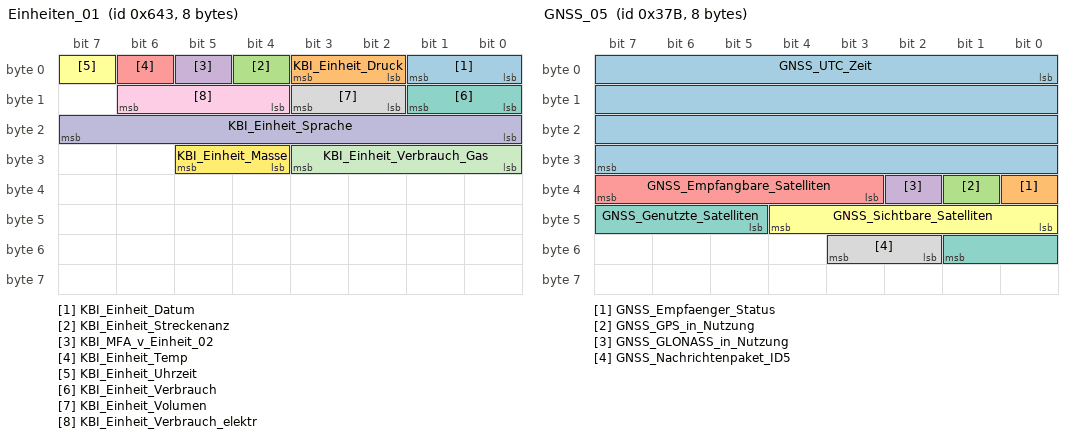
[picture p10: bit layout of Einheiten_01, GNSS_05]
BO_ 1603 Einheiten_01: 8 Gateway
 SG_ KBI_Einheit_Datum : 0|2@1+ (1,0) [0|3] "" Vector__XXX
 SG_ KBI_Einheit_Druck : 2|2@1+ (1,0) [0|3] "" Vector__XXX
 SG_ KBI_Einheit_Streckenanz : 4|1@1+ (1,0) [0|1] ""  Ladegeraet_Konzern
 SG_ KBI_MFA_v_Einheit_02 : 5|1@1+ (1,0) [0|1] "" Vector__XXX
 SG_ KBI_Einheit_Temp : 6|1@1+ (1,0) [0|1] ""  TME
 SG_ KBI_Einheit_Uhrzeit : 7|1@1+ (1,0) [0|1] ""  Ladegeraet_Konzern
 SG_ KBI_Einheit_Verbrauch : 8|2@1+ (1,0) [0|3] "" Vector__XXX
 SG_ KBI_Einheit_Volumen : 10|2@1+ (1,0) [0|3] "" Vector__XXX
 SG_ KBI_Einheit_Verbrauch_elektr : 12|3@1+ (1,0) [0|7] "" Vector__XXX
 SG_ KBI_Einheit_Sprache : 16|8@1+ (1,0) [0|255] "" Vector__XXX
 SG_ KBI_Einheit_Verbrauch_Gas : 24|4@1+ (1,0) [0|15] "" Vector__XXX
 SG_ KBI_Einheit_Masse : 28|2@1+ (1,0) [0|3] "" Vector__XXX

BO_ 1629 ESP_20: 8 Gateway
 SG_ ESP_20_CRC : 0|8@1+ (1,0) [0|255] "" Vector__XXX
 SG_ ESP_20_BZ : 8|4@1+ (1,0) [0|15] "" Vector__XXX
 SG_ BR_Systemart : 12|2@1+ (1,0) [0|3] "" Vector__XXX
 SG_ ESP_SpannungsAnf_02 : 14|2@1+ (1,0) [0|3] "" Vector__XXX
 SG_ ESP_Zaehnezahl : 16|8@1+ (1,0) [0|255] "" Vector__XXX
 SG_ ESP_Charisma_FahrPr : 24|4@1+ (1,0) [0|15] "" Vector__XXX
 SG_ ESP_Charisma_Status : 28|2@1+ (1,0) [0|3] "" Vector__XXX
 SG_ ESP_Wiederstart_Anz_01 : 30|1@1+ (1,0) [0|1] "" Vector__XXX
 SG_ ESP_Wiederstart_Anz_02 : 31|1@1+ (1,0) [0|1] "" Vector__XXX
 SG_ ESP_Wiederstart_Anz_03 : 32|1@1+ (1,0) [0|1] "" Vector__XXX
 SG_ ESP_Wiederstart_Anz_04 : 33|1@1+ (1,0) [0|1] "" Vector__XXX
 SG_ ESP_Stoppverbot_Anz_01 : 34|1@1+ (1,0) [0|1] "" Vector__XXX
 SG_ ESP_Stoppverbot_Anz_02 : 35|1@1+ (1,0) [0|1] "" Vector__XXX
 SG_ ESP_Stoppverbot_Anz_03 : 36|1@1+ (1,0) [0|1] "" Vector__XXX
 SG_ ESP_Stoppverbot_Anz_04 : 37|1@1+ (1,0) [0|1] "" Vector__XXX
 SG_ ESP_Stoppverbot_Anz_05 : 38|1@1+ (1,0) [0|1] "" Vector__XXX
 SG_ ESP_Stoppverbot_Anz_06 : 39|1@1+ (1,0) [0|1] "" Vector__XXX
 SG_ ESP_Stoppverbot_Anz_07 : 40|1@1+ (1,0) [0|1] "" Vector__XXX
 SG_ ESP_Stoppverbot_Anz_Std : 41|1@1+ (1,0) [0|1] "" Vector__XXX
 SG_ ESP_Dachrelingsensor : 42|2@1+ (1,0) [0|3] "" Vector__XXX
 SG_ ESP_Stoppverbot_Anz_08 : 44|1@1+ (1,0) [0|1] "" Vector__XXX
 SG_ HDC_Charisma_FahrPr : 45|4@1+ (1,0) [0|15] "" Vector__XXX
 SG_ HDC_Charisma_Status : 49|2@1+ (1,0) [0|3] "" Vector__XXX
 SG_ BR_QBit_Reifenumfang : 51|1@1+ (1,0) [0|1] ""  AWC
 SG_ BR_Reifenumfang : 52|12@1+ (1,0) [0|4095] "Unit_MilliMeter"  AWC

BO_ 1413 Systeminfo_01: 8 Gateway_MQB
 SG_ SI_Sammel_SG_Fehler : 0|6@1+ (1,0) [0|60] "" Vector__XXX
 SG_ SI_Rollenmode : 6|2@1+ (1,0) [0|3] "" Vector__XXX
 SG_ SI_QRS_Mode : 8|1@1+ (1,0) [0|1] "" Motor_Diesel_MQB,Motor_Hybrid_MQB,Motor_Otto_MQB
 SG_ SI_T_Mode : 9|1@1+ (1,0) [0|1] "" Vector__XXX
 SG_ SI_NWDF : 10|1@1+ (1,0) [0|1] "" SAK_MQB
 SG_ SI_NWDF_gueltig : 11|1@1+ (1,0) [0|1] "" SAK_MQB
 SG_ SI_Sammelfehler : 12|1@1+ (1,0) [0|1] "" Vector__XXX
 SG_ GW_KD_Fehler : 13|1@1+ (1,0) [0|1] "" Vector__XXX
 SG_ SI_BUS_01 : 16|1@1+ (1,0) [0|1] "" Vector__XXX
 SG_ SI_BUS_02 : 17|1@1+ (1,0) [0|1] "" Vector__XXX
 SG_ SI_BUS_03 : 18|1@1+ (1,0) [0|1] "" Vector__XXX
 SG_ SI_BUS_04 : 19|1@1+ (1,0) [0|1] "" Vector__XXX
 SG_ SI_BUS_05 : 20|1@1+ (1,0) [0|1] "" Vector__XXX
 SG_ SI_BUS_06 : 21|1@1+ (1,0) [0|1] "" Vector__XXX
 SG_ SI_BUS_07 : 22|1@1+ (1,0) [0|1] "" Vector__XXX
 SG_ SI_BUS_08 : 23|1@1+ (1,0) [0|1] "" Vector__XXX
 SG_ SI_BUS_09 : 24|1@1+ (1,0) [0|1] "" Vector__XXX
 SG_ SI_BUS_10 : 25|1@1+ (1,0) [0|1] "" Vector__XXX
 SG_ SI_BUS_11 : 26|1@1+ (1,0) [0|1] "" Vector__XXX
 SG_ SI_BUS_12 : 27|1@1+ (1,0) [0|1] "" Vector__XXX
 SG_ SI_BUS_13 : 28|1@1+ (1,0) [0|1] "" Vector__XXX
 SG_ SI_BUS_14 : 29|1@1+ (1,0) [0|1] "" Vector__XXX
 SG_ SI_BUS_15 : 30|1@1+ (1,0) [0|1] "" Vector__XXX

BO_ 891 GNSS_05: 8 Gateway
 SG_ GNSS_UTC_Zeit : 0|32@1+ (1,0) [1|4294967295] "Unit_Secon"  OTA_FC,ZR_High,ZR_LIMU,ZR_MIB_TOP_ab_Gen3,ZR_Standard
 SG_ GNSS_Empfaenger_Status : 32|1@1+ (1.0,0.0) [0.0|1] ""  OTA_FC,ZR_High,ZR_LIMU,ZR_MIB_TOP_ab_Gen3,ZR_Standard
 SG_ GNSS_GPS_in_Nutzung : 33|1@1+ (1.0,0.0) [0.0|1] ""  ZR_High,ZR_LIMU,ZR_MIB_TOP_ab_Gen3,ZR_Standard
 SG_ GNSS_GLONASS_in_Nutzung : 34|1@1+ (1.0,0.0) [0.0|1] ""  ZR_High,ZR_LIMU,ZR_MIB_TOP_ab_Gen3,ZR_Standard
 SG_ GNSS_Empfangbare_Satelliten : 35|5@1+ (1,0) [1|30] "Unit_None"  ZR_High,ZR_LIMU,ZR_MIB_TOP_ab_Gen3,ZR_Standard
 SG_ GNSS_Sichtbare_Satelliten : 40|5@1+ (1,0) [1|30] "Unit_None"  ZR_High,ZR_LIMU,ZR_MIB_TOP_ab_Gen3,ZR_Standard
 SG_ GNSS_Genutzte_Satelliten : 45|5@1+ (1,0) [1|30] "Unit_None"  ZR_High,ZR_LIMU,ZR_MIB_TOP_ab_Gen3,ZR_Standard
 SG_ GNSS_Nachrichtenpaket_ID5 : 50|2@1+ (1,0) [0|3] "Unit_Bit"  ZR_High,ZR_LIMU,ZR_MIB_TOP_ab_Gen3,ZR_Standard

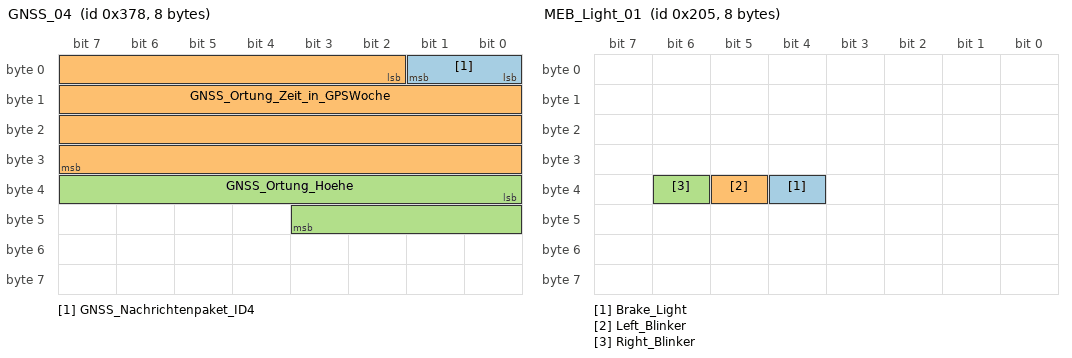
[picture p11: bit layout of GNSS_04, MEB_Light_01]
BO_ 888 GNSS_04: 8 Gateway
 SG_ GNSS_Nachrichtenpaket_ID4 : 0|2@1+ (1,0) [0|3] "Unit_Bit"  ZR_High,ZR_LIMU,ZR_MIB_TOP_ab_Gen3,ZR_Standard
 SG_ GNSS_Ortung_Zeit_in_GPSWoche : 2|30@1+ (1,0) [0|604800001] "Unit_MilliSecon"  ZR_High,ZR_LIMU,ZR_MIB_TOP_ab_Gen3,ZR_Standard
 SG_ GNSS_Ortung_Hoehe : 32|12@1+ (2,-500) [-500|7686] "Unit_Meter"  ZR_High,ZR_LIMU,ZR_MIB_TOP_ab_Gen3,ZR_Standard

BO_ 1524 Innenlicht_11: 8 Gateway
 SG_ IL_Dimmung_V_Tuerkontur : 0|8@1+ (1,0) [0|100] "Unit_PerCent"  ZR_High
 SG_ IL_Dimmung_H_Tuerkontur : 8|8@1+ (1,0) [0|100] "Unit_PerCent"  ZR_High
 SG_ IL_Dimmung_Tuerinnengriff : 16|8@1+ (1,0) [0|100] "Unit_PerCent"  ZR_High
 SG_ IL_Dimmung_Umfeldbel : 24|8@1+ (1,0) [0|100] "Unit_PerCent"  ZR_High
 SG_ IL_Bel_FS_Ausstieg : 32|1@1+ (1.0,0.0) [0.0|1] ""  ZR_High
 SG_ IL_Bel_BFS_Ausstieg : 33|1@1+ (1.0,0.0) [0.0|1] ""  ZR_High
 SG_ IL_Bel_HFS_Ausstieg : 34|1@1+ (1.0,0.0) [0.0|1] ""  ZR_High
 SG_ IL_Bel_HBFS_Ausstieg : 35|1@1+ (1.0,0.0) [0.0|1] ""  ZR_High
 SG_ BCM1_Innenlicht_gedimmt_V : 36|1@1+ (1.0,0.0) [0.0|1] ""  ZR_High
 SG_ BCM1_Innenlicht_gedimmt_H : 37|1@1+ (1.0,0.0) [0.0|1] ""  ZR_High
 SG_ IL_Innenlicht_aktiv : 38|1@1+ (1.0,0.0) [0.0|1] ""  ZR_High
 SG_ IL_Klemme_30G_aktiv : 39|1@1+ (1.0,0.0) [0.0|1] ""  Vector__XXX
 SG_ BCM1_DI_Rampe_Innenlicht : 40|1@1+ (1.0,0.0) [0.0|1] ""  ZR_High
 SG_ BCM1_DI_Rampe_Leselicht : 41|1@1+ (1.0,0.0) [0.0|1] ""  ZR_High
 SG_ BCM1_Innenlicht_H : 42|1@1+ (1.0,0.0) [0.0|1] ""  ZR_High
 SG_ BCM1_Innenlicht_V : 43|1@1+ (1.0,0.0) [0.0|1] ""  ZR_High
 SG_ BCM1_Leselicht_Anf_hl : 44|1@1+ (1.0,0.0) [0.0|1] ""  ZR_High
 SG_ BCM1_Leselicht_Anf_hr : 45|1@1+ (1.0,0.0) [0.0|1] ""  ZR_High
 SG_ BCM1_Leselicht_Anf_vl : 46|1@1+ (1.0,0.0) [0.0|1] ""  ZR_High
 SG_ BCM1_Leselicht_Anf_vr : 47|1@1+ (1.0,0.0) [0.0|1] ""  ZR_High
 SG_ BCM1_Leuchten_Aus : 48|1@1+ (1.0,0.0) [0.0|1] ""  ZR_High
 SG_ AMB_Charisma_FahrPr : 49|4@1+ (1.0,0.0) [0.0|15] ""  Vector__XXX
 SG_ AMB_Charisma_Status : 53|2@1+ (1.0,0.0) [0.0|3] ""  Vector__XXX
 SG_ IL_Dimmung_Lautspr : 56|8@1+ (1,0) [0|100] "Unit_PerCent"  ZR_High

BO_ 1624 Licht_vorne_01: 8 Gateway
 SG_ Licht_Vorne_01_CRC : 0|8@1+ (1,0) [0|255] ""  Vector__XXX
 SG_ Licht_Vorne_01_BZ : 8|4@1+ (1,0) [0|15] ""  Vector__XXX
 SG_ LV_Standlicht_Anzeige : 12|1@1+ (1.0,0.0) [0.0|1] ""  OTA_FC,ZR_High
 SG_ LV_Abblendlicht_Anzeige : 13|1@1+ (1.0,0.0) [0.0|1] ""  OTA_FC,ZR_High
 SG_ LV_Fernlicht_Anzeige : 14|1@1+ (1.0,0.0) [0.0|1] ""  OTA_FC,ZR_High
 SG_ LV_Nebellicht_Anzeige : 15|1@1+ (1.0,0.0) [0.0|1] ""  OTA_FC,ZR_High
 SG_ LV_Nebelschlusslicht_Anzeige : 16|1@1+ (1.0,0.0) [0.0|1] ""  OTA_FC,ZR_High
 SG_ LV_Tagfahrlicht_Anzeige : 17|1@1+ (1.0,0.0) [0.0|1] ""  BedienSG_hi,OTA_FC,ZR_High
 SG_ LV_AFL_aktiv_Anzeige : 18|1@1+ (1.0,0.0) [0.0|1] ""  BedienSG_hi,OTA_FC,ZR_High
 SG_ LV_AFL_defekt : 19|1@1+ (1.0,0.0) [0.0|1] ""  ZR_High
 SG_ LV_Blinker_li_def : 20|1@1+ (1.0,0.0) [0.0|1] ""  ZR_High
 SG_ LV_Standlicht_li_def : 21|1@1+ (1.0,0.0) [0.0|1] ""  ZR_High
 SG_ LV_Abblendlicht_li_def : 22|1@1+ (1.0,0.0) [0.0|1] ""  ZR_High
 SG_ LV_Fernlicht_li_def : 23|1@1+ (1.0,0.0) [0.0|1] ""  ZR_High
 SG_ LV_Nebellicht_li_def : 24|1@1+ (1.0,0.0) [0.0|1] ""  ZR_High
 SG_ LV_Blk_li_Seite_def : 25|1@1+ (1.0,0.0) [0.0|1] ""  ZR_High
 SG_ LV_Tagfahrlicht_li_def : 26|1@1+ (1.0,0.0) [0.0|1] ""  ZR_High
 SG_ LV_FLA_aktiv_Anzeige : 27|1@1+ (1.0,0.0) [0.0|1] ""  OTA_FC,ZR_High
 SG_ LV_FLA_defekt : 28|1@1+ (1.0,0.0) [0.0|1] ""  ZR_High
 SG_ LV_FLA_Sensor_blockiert : 29|1@1+ (1.0,0.0) [0.0|1] ""  OTA_FC,ZR_High
 SG_ LV_Blinker_re_def : 30|1@1+ (1.0,0.0) [0.0|1] ""  ZR_High
 SG_ LV_Standlicht_re_def : 31|1@1+ (1.0,0.0) [0.0|1] ""  ZR_High
 SG_ LV_Abblendlicht_re_def : 32|1@1+ (1.0,0.0) [0.0|1] ""  ZR_High
 SG_ LV_Fernlicht_re_def : 33|1@1+ (1.0,0.0) [0.0|1] ""  ZR_High
 SG_ LV_Nebellicht_re_def : 34|1@1+ (1.0,0.0) [0.0|1] ""  ZR_High
 SG_ LV_Blk_re_Seite_def : 35|1@1+ (1.0,0.0) [0.0|1] ""  ZR_High
 SG_ LV_Tagfahrlicht_re_def : 36|1@1+ (1.0,0.0) [0.0|1] ""  ZR_High
 SG_ LV_Aussenlicht_def : 37|1@1+ (1.0,0.0) [0.0|1] ""  ZR_High
 SG_ LV_Abblendlicht_TFL_li_def : 38|1@1+ (1.0,0.0) [0.0|1] ""  ZR_High
 SG_ LV_Nebellicht_TFL_li_def : 39|1@1+ (1.0,0.0) [0.0|1] ""  ZR_High
 SG_ LV_Standlicht_TFL_li_def : 40|1@1+ (1.0,0.0) [0.0|1] ""  ZR_High
 SG_ LV_Abblend_Fernlicht_li_def : 41|1@1+ (1.0,0.0) [0.0|1] ""  ZR_High
 SG_ LV_Abblendlicht_TFL_re_def : 42|1@1+ (1.0,0.0) [0.0|1] ""  ZR_High
 SG_ LV_Nebellicht_TFL_re_def : 43|1@1+ (1.0,0.0) [0.0|1] ""  ZR_High
 SG_ LV_Standlicht_TFL_re_def : 44|1@1+ (1.0,0.0) [0.0|1] ""  ZR_High
 SG_ LV_Abblend_Fernlicht_re_def : 45|1@1+ (1.0,0.0) [0.0|1] ""  ZR_High
 SG_ LV_Abbiegelicht_li_def : 46|1@1+ (1.0,0.0) [0.0|1] ""  Vector__XXX
 SG_ LV_Abbiegelicht_re_def : 47|1@1+ (1.0,0.0) [0.0|1] ""  Vector__XXX
 SG_ BCM1_Linksverkehr : 48|1@1+ (1.0,0.0) [0.0|1] ""  OTA_FC,ZR_High
 SG_ BCM1_Licht_Dunkelheit_aktiv : 49|1@1+ (1.0,0.0) [0.0|1] ""  OTA_FC,ZR_High
 SG_ LV_LED_Scheinwerfer_li_def : 50|1@1+ (1.0,0.0) [0.0|1] ""  Vector__XXX
 SG_ LV_LED_Scheinwerfer_re_def : 51|1@1+ (1.0,0.0) [0.0|1] ""  Vector__XXX
 SG_ LV_Blinker_VL_aktiv : 52|1@1+ (1.0,0.0) [0.0|1] ""  OTA_FC,ZR_High
 SG_ LV_Blinker_VR_aktiv : 53|1@1+ (1.0,0.0) [0.0|1] ""  OTA_FC,ZR_High
 SG_ LV_MXB_Status_Anzeige : 54|2@1+ (1.0,0.0) [0.0|3] ""  Vector__XXX

BO_ 982 Licht_hinten_01: 8 Gateway
 SG_ BCM2_Bremsl_durch_ECD : 5|1@1+ (1.0,0.0) [0.0|1] ""  OTA_FC,ZR_High
 SG_ LH_Aussenlicht_def : 7|1@1+ (1.0,0.0) [0.0|1] ""  ZR_High
 SG_ LH_Standlicht_H_aktiv : 8|1@1+ (1.0,0.0) [0.0|1] ""  OTA_FC,ZR_High
 SG_ LH_Parklicht_HL_aktiv : 9|1@1+ (1.0,0.0) [0.0|1] ""  OTA_FC,ZR_High
 SG_ LH_Parklicht_HR_aktiv : 10|1@1+ (1.0,0.0) [0.0|1] ""  OTA_FC,ZR_High
 SG_ LH_Bremslicht_H_aktiv : 11|1@1+ (1.0,0.0) [0.0|1] ""  OTA_FC,ZR_High
 SG_ LH_Nebelschluss_aktiv : 12|1@1+ (1.0,0.0) [0.0|1] ""  OTA_FC,ZR_High
 SG_ LH_Rueckfahrlicht_aktiv : 13|1@1+ (1.0,0.0) [0.0|1] ""  OTA_FC,ZR_High
 SG_ LH_Blinker_HL_akt : 14|1@1+ (1.0,0.0) [0.0|1] ""  OTA_FC,ZR_High
 SG_ LH_Blinker_HR_akt : 15|1@1+ (1.0,0.0) [0.0|1] ""  OTA_FC,ZR_High
 SG_ LH_Blinker_li_def : 16|1@1+ (1.0,0.0) [0.0|1] ""  ZR_High
 SG_ LH_Bremsl_li_def : 17|1@1+ (1.0,0.0) [0.0|1] ""  ZR_High
 SG_ LH_Schlusslicht_li_def : 18|1@1+ (1.0,0.0) [0.0|1] ""  ZR_High
 SG_ LH_Rueckf_li_def : 19|1@1+ (1.0,0.0) [0.0|1] ""  ZR_High
 SG_ LH_Nebel_li_def : 20|1@1+ (1.0,0.0) [0.0|1] ""  ZR_High
 SG_ LH_Schluss_Brems_Nebel_li_def : 21|1@1+ (1.0,0.0) [0.0|1] ""  ZR_High
 SG_ LH_Schluss_Brems_Nebel_re_def : 22|1@1+ (1.0,0.0) [0.0|1] ""  ZR_High
 SG_ LH_Zusatzschlussl_def : 23|1@1+ (1.0,0.0) [0.0|1] ""  Vector__XXX
 SG_ LH_Schluss_Brems_li_def : 24|1@1+ (1.0,0.0) [0.0|1] ""  ZR_High
 SG_ LH_Schluss_Nebel_li_def : 25|1@1+ (1.0,0.0) [0.0|1] ""  ZR_High
 SG_ LH_SL_BRL_BLK_li_def : 26|1@1+ (1.0,0.0) [0.0|1] ""  ZR_High
 SG_ LH_Brems_Blk_li_def : 27|1@1+ (1.0,0.0) [0.0|1] ""  Vector__XXX
 SG_ LH_Diag_Status_re_def : 28|1@1+ (1.0,0.0) [0.0|1] ""  ZR_High
 SG_ LH_Diag_Status_li_def : 29|1@1+ (1.0,0.0) [0.0|1] ""  ZR_High
 SG_ LH_Diag_LED_li_def : 30|1@1+ (1.0,0.0) [0.0|1] ""  ZR_High
 SG_ LH_Diag_LED_re_def : 31|1@1+ (1.0,0.0) [0.0|1] ""  ZR_High
 SG_ LH_Blinker_re_def : 32|1@1+ (1.0,0.0) [0.0|1] ""  ZR_High
 SG_ LH_Bremsl_re_def : 33|1@1+ (1.0,0.0) [0.0|1] ""  ZR_High
 SG_ LH_Schlusslicht_re_def : 34|1@1+ (1.0,0.0) [0.0|1] ""  ZR_High
 SG_ LH_Rueckf_re_def : 35|1@1+ (1.0,0.0) [0.0|1] ""  ZR_High
 SG_ LH_Nebel_re_def : 36|1@1+ (1.0,0.0) [0.0|1] ""  ZR_High
 SG_ LH_Schluss_Brems_mi_def : 37|1@1+ (1.0,0.0) [0.0|1] ""  Vector__XXX
 SG_ LH_Schluss_Brems_re_def : 40|1@1+ (1.0,0.0) [0.0|1] ""  ZR_High
 SG_ LH_Schluss_Nebel_re_def : 41|1@1+ (1.0,0.0) [0.0|1] ""  ZR_High
 SG_ LH_SL_BRL_BLK_re_def : 42|1@1+ (1.0,0.0) [0.0|1] ""  ZR_High
 SG_ LH_Brems_Blk_re_def : 43|1@1+ (1.0,0.0) [0.0|1] ""  ZR_High
 SG_ LH_Kennzl_def : 48|1@1+ (1.0,0.0) [0.0|1] ""  ZR_High
 SG_ LH_3_Bremsl_def : 49|1@1+ (1.0,0.0) [0.0|1] ""  ZR_High
 SG_ LH_Nebel_mi_def : 50|1@1+ (1.0,0.0) [0.0|1] ""  ZR_High
 SG_ LH_Rueckf_mi_def : 51|1@1+ (1.0,0.0) [0.0|1] ""  ZR_High
 SG_ LH_Schlusslicht_mi_def : 52|1@1+ (1.0,0.0) [0.0|1] ""  Vector__XXX
 SG_ LH_Bremsl_mi_def : 53|1@1+ (1.0,0.0) [0.0|1] ""  Vector__XXX
 SG_ LH_Bremsl_li_ges_def : 54|1@1+ (1.0,0.0) [0.0|1] ""  ZR_High
 SG_ LH_Bremsl_re_ges_def : 55|1@1+ (1.0,0.0) [0.0|1] ""  ZR_High

BO_ 517 MEB_Light_01: 8 XXX
 SG_ Brake_Light : 36|1@0+ (1,0) [0|1] "" XXX
 SG_ Left_Blinker : 37|1@0+ (1,0) [0|1] "" XXX
 SG_ Right_Blinker : 38|1@0+ (1,0) [0|1] "" XXX

BO_ 817 MFL_01: 8 Gateway
 SG_ MFL_Zaehler : 0|4@1+ (1,0) [0|15] ""  Vector__XXX
 SG_ MFL_Toggle : 4|1@1+ (1,0) [0|1] ""  Vector__XXX
 SG_ MFL_Lokalaktiv : 5|1@1+ (1.0,0.0) [0.0|1] ""  Vector__XXX
 SG_ MFL_M_Taste : 6|1@1+ (1.0,0.0) [0.0|1] ""  ZR_High
 SG_ MFL_Paddle_Verbau : 7|1@1+ (1.0,0.0) [0.0|1] ""  ZR_High
 SG_ MFL_Tastencode_1 : 8|8@1+ (1.0,0.0) [0.0|255] ""  Vector__XXX
 SG_ MFL_Tastencode_2 : 16|8@1+ (1.0,0.0) [0.0|255] ""  Vector__XXX
 SG_ MFL_Eventcode_1 : 24|4@1+ (1.0,0.0) [0.0|15] ""  Vector__XXX
 SG_ MFL_Eventcode_2 : 28|4@1+ (1.0,0.0) [0.0|15] ""  Vector__XXX
 SG_ MFL_Marke : 32|4@1+ (1.0,0.0) [0.0|15] ""  Vector__XXX
 SG_ MFL_Variante : 36|4@1+ (1,0) [0|15] ""  Vector__XXX
 SG_ MFL_Dummy_0_Signal_1 : 40|8@1+ (1.0,0.0) [0.0|255] ""  Vector__XXX
 SG_ MFL_Tip_Down : 48|1@1+ (1.0,0.0) [0.0|1] ""  ZR_High
 SG_ MFL_Tip_Up : 49|1@1+ (1.0,0.0) [0.0|1] ""  ZR_High
 SG_ MFL_SatModul_links_Err : 50|1@1+ (1.0,0.0) [0.0|1] ""  ZR_High
 SG_ MFL_SatModul_rechts_Err : 51|1@1+ (1.0,0.0) [0.0|1] ""  ZR_High
 SG_ MFL_Dummy_0_Signal_2 : 52|1@1+ (1.0,0.0) [0.0|1] ""  Vector__XXX
 SG_ MFL_Dummy_0_Signal_3 : 53|1@1+ (1.0,0.0) [0.0|1] ""  Vector__XXX
 SG_ MFL_LR_HZG_Status : 54|1@1+ (1.0,0.0) [0.0|1] ""  ZR_High
 SG_ MFL_LR_HZG_Err : 55|1@1+ (1.0,0.0) [0.0|1] ""  ZR_High
 SG_ MFL_Signalhorn : 56|1@1+ (1.0,0.0) [0.0|1] ""  OTA_FC,ZR_High
 SG_ MFL_Signalhorn_Err : 57|1@1+ (1.0,0.0) [0.0|1] ""  ZR_High
 SG_ MFL_Tip_links_Err : 58|1@1+ (1.0,0.0) [0.0|1] ""  ZR_High
 SG_ MFL_Tip_rechts_Err : 59|1@1+ (1.0,0.0) [0.0|1] ""  ZR_High
 SG_ MFL_Taste_links_Err : 60|1@1+ (1.0,0.0) [0.0|1] ""  ZR_High
 SG_ MFL_Taste_rechts_Err : 61|1@1+ (1.0,0.0) [0.0|1] ""  ZR_High
 SG_ MFL_ECU_Err : 62|1@1+ (1.0,0.0) [0.0|1] ""  ZR_High
 SG_ MFL_Response_Err : 63|1@1+ (1.0,0.0) [0.0|1] ""  Vector__XXX

BO_ 706 Motor_41: 8 Gateway
 SG_ MO_Anzeige_StSt_Text : 12|4@1+ (1.0,0.0) [0.0|15] ""  Vector__XXX
 SG_ MO_Anzeige_StSt_Symbol : 16|3@1+ (1.0,0.0) [0.0|7] ""  Vector__XXX
 SG_ MO_ADR_Status : 19|2@1+ (1.0,0.0) [0.0|3] ""  ZR_High
 SG_ MO_AGA_Sound_Texte : 21|2@1+ (1.0,0.0) [0.0|3] ""  Vector__XXX
 SG_ MO_Anzeige_FMAus_Text : 23|1@1+ (1.0,0.0) [0.0|1] ""  Vector__XXX
 SG_ MO_Fehler_MSpG : 24|1@1+ (1.0,0.0) [0.0|1] ""  Vector__XXX
 SG_ PEA_Texte : 25|3@1+ (1.0,0.0) [0.0|7] ""  Vector__XXX
 SG_ TSK_Ueberstimmt_vMax_FahrerInfo : 28|2@1+ (1.0,0.0) [0.0|3] ""  Vector__XXX
 SG_ MO_Avus_Motorschutz : 30|2@1+ (1.0,0.0) [0.0|3] ""  Vector__XXX
 SG_ MO_Rekuperationsstufe : 32|3@1+ (1.0,0.0) [0.0|7] ""  OTA_FC
 SG_ TSK_Einheit_vMax_FahrerInfo : 35|1@1+ (1.0,0.0) [0.0|1] ""  Vector__XXX
 SG_ TSK_Status_vMax_FahrerInfo : 36|2@1+ (1.0,0.0) [0.0|3] ""  Vector__XXX
 SG_ MO_Red_Fahrleistung : 38|3@1+ (1.0,0.0) [0.0|7] ""  Vector__XXX
 SG_ MO_Anz_Kuehlerluefter : 47|3@1+ (1.0,0.0) [0.0|7] ""  Vector__XXX
 SG_ MO_im_Leerlauf : 50|1@1+ (1.0,0.0) [0.0|1] ""  Vector__XXX
 SG_ WIV_Enable_Oeldr_Motor : 51|1@1+ (1.0,0.0) [0.0|1] ""  Vector__XXX
 SG_ MO_OelMessung_Dauer : 52|4@1+ (15,15) [15|225] "Unit_Secon"  Vector__XXX
 SG_ TSK_vMax_FahrerInfo : 56|8@1+ (1,15) [16|270] ""  Vector__XXX

BO_ 1122 PSD_04: 8 ZR_High
 SG_ PSD_Segment_ID : 0|6@1+ (1,0) [2|63] ""  Gateway,Gateway_PAG
 SG_ PSD_Vorgaenger_Segment_ID : 6|6@1+ (1,0) [2|63] ""  Gateway,Gateway_PAG
 SG_ PSD_Segmentlaenge : 12|7@1+ (2,0) [0|254] "Unit_Meter"  Gateway,Gateway_PAG,OTA_FC
 SG_ PSD_Strassenkategorie : 19|3@1+ (1.0,0.0) [0.0|7] ""  Gateway,Gateway_PAG,OTA_FC
 SG_ PSD_Endkruemmung : 22|8@1+ (1,0) [0|254] "Unit_None"  Gateway,Gateway_PAG
 SG_ PSD_Endkruemmung_Vorz : 30|1@1+ (1.0,0.0) [0.0|1] ""  Gateway,Gateway_PAG
 SG_ PSD_Idenditaets_ID : 31|6@1+ (1,0) [2|63] ""  Gateway,Gateway_PAG
 SG_ PSD_ADAS_Qualitaet : 37|1@1+ (1.0,0.0) [0.0|1] ""  Gateway,Gateway_PAG
 SG_ PSD_wahrscheinlichster_Pfad : 38|1@1+ (1.0,0.0) [0.0|1] ""  Gateway,Gateway_PAG
 SG_ PSD_Geradester_Pfad : 39|1@1+ (1.0,0.0) [0.0|1] ""  Gateway,Gateway_PAG
 SG_ PSD_Fahrspuren_Anzahl : 40|3@1+ (1.0,0.0) [0.0|7] ""  Gateway,Gateway_PAG,OTA_FC
 SG_ PSD_Bebauung : 43|1@1+ (1.0,0.0) [0.0|1] ""  Gateway,Gateway_PAG
 SG_ PSD_Segment_Komplett : 44|1@1+ (1.0,0.0) [0.0|1] ""  Gateway,Gateway_PAG
 SG_ PSD_Rampe : 45|2@1+ (1.0,0.0) [0.0|3] ""  Gateway,Gateway_PAG
 SG_ PSD_Anfangskruemmung : 47|8@1+ (1,0) [0|254] ""  Gateway,Gateway_PAG
 SG_ PSD_Anfangskruemmung_Vorz : 55|1@1+ (1.0,0.0) [0.0|1] ""  Gateway,Gateway_PAG
 SG_ PSD_Abzweigerichtung : 56|1@1+ (1.0,0.0) [0.0|1] ""  Gateway,Gateway_PAG
 SG_ PSD_Abzweigewinkel : 57|7@1+ (1.417323,0) [0.000000|180.000021] ""  Gateway,Gateway_PAG

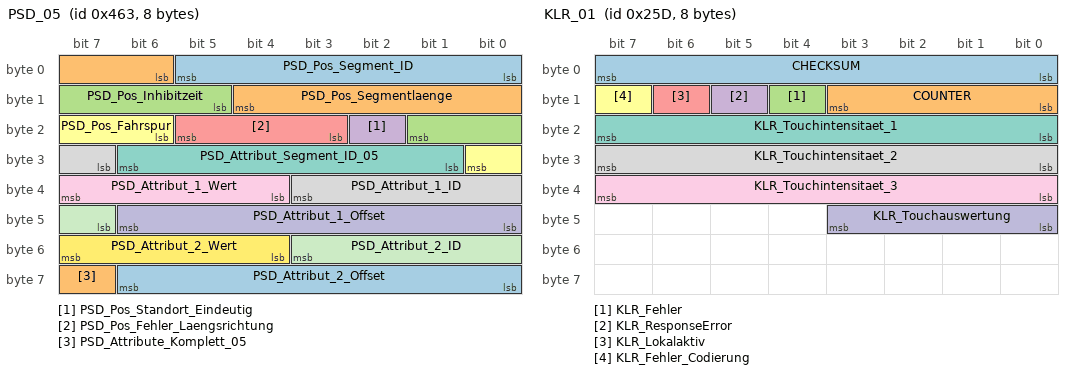
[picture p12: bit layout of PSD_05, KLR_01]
BO_ 1123 PSD_05: 8 ZR_High
 SG_ PSD_Pos_Segment_ID : 0|6@1+ (1,0) [2|63] ""  Gateway,Gateway_PAG
 SG_ PSD_Pos_Segmentlaenge : 6|7@1+ (2,0) [0|254] "Unit_Meter"  Gateway,Gateway_PAG
 SG_ PSD_Pos_Inhibitzeit : 13|5@1+ (10,0) [0|310] "Unit_MilliSecon"  Gateway,Gateway_PAG
 SG_ PSD_Pos_Standort_Eindeutig : 18|1@1+ (1.0,0.0) [0.0|1] ""  Gateway,Gateway_PAG
 SG_ PSD_Pos_Fehler_Laengsrichtung : 19|3@1+ (1.0,0.0) [0.0|7] ""  Gateway,Gateway_PAG
 SG_ PSD_Pos_Fahrspur : 22|3@1+ (1.0,0.0) [0.0|7] ""  Gateway,Gateway_PAG,OTA_FC
 SG_ PSD_Attribut_Segment_ID_05 : 25|6@1+ (1,0) [2|63] ""  Gateway,Gateway_PAG
 SG_ PSD_Attribut_1_ID : 31|5@1+ (1,0) [1|31] ""  Gateway,Gateway_PAG
 SG_ PSD_Attribut_1_Wert : 36|4@1+ (1.0,0.0) [0.0|15] ""  Gateway,Gateway_PAG
 SG_ PSD_Attribut_1_Offset : 40|7@1+ (2,0) [0|254] "Unit_Meter"  Gateway,Gateway_PAG
 SG_ PSD_Attribut_2_ID : 47|5@1+ (1,0) [1|31] ""  Gateway,Gateway_PAG
 SG_ PSD_Attribut_2_Wert : 52|4@1+ (1.0,0.0) [0.0|15] ""  Gateway,Gateway_PAG
 SG_ PSD_Attribut_2_Offset : 56|7@1+ (2,0) [0|254] "Unit_Meter"  Gateway,Gateway_PAG
 SG_ PSD_Attribute_Komplett_05 : 63|1@1+ (1.0,0.0) [0.0|1] ""  Gateway,Gateway_PAG

BO_ 1124 PSD_06: 8 ZR_High
 SG_ PSD_06_Mux M  : 0|3@1+ (1.0,0.0) [0.0|7] ""  Gateway,Gateway_PAG
 SG_ PSD_Sys_Segment_ID m0  : 3|6@1+ (1,0) [2|63] ""  Gateway,Gateway_PAG
 SG_ PSD_Attribut_Segment_ID m1  : 3|6@1+ (1,0) [2|63] ""  Gateway,Gateway_PAG
 SG_ PSD_Ges_Segment_ID m2  : 3|6@1+ (1,0) [2|63] ""  Gateway,Gateway_PAG
 SG_ PSD_Baum_Laenge_VZ m3  : 3|1@1+ (1.0,0.0) [0.0|1] ""  Gateway,Gateway_PAG
 SG_ PSD_Steigung_1_Segment_ID m4  : 3|6@1+ (1,0) [2|63] ""  Gateway,Gateway_PAG
 SG_ PSD_Baum_Laenge m3  : 4|25@1+ (0.00001,0) [0.00000|180.00000] "Unit_DegreOfArc"  Gateway,Gateway_PAG
 SG_ PSD_Sys_Laendercode m0  : 9|8@1+ (1.0,0.0) [0.0|255] ""  Gateway,Gateway_PAG
 SG_ PSD_Attribut_3_ID m1  : 9|5@1+ (1,0) [1|31] ""  Gateway,Gateway_PAG
 SG_ PSD_Ges_Offset m2  : 9|7@1+ (2,0) [0|254] "Unit_Meter"  Gateway,Gateway_PAG
 SG_ PSD_Steigung_1_A_Steigung m4  : 9|7@1+ (0.12,0) [0.00|15.00] "Unit_PerCent"  Gateway,Gateway_PAG
 SG_ PSD_Attribut_3_Offset m1  : 14|7@1+ (2,0) [0|254] "Unit_Meter"  Gateway,Gateway_PAG
 SG_ PSD_Ges_Geschwindigkeit m2  : 16|5@1+ (1.0,0.0) [0.0|31] ""  Gateway,Gateway_PAG,OTA_FC
 SG_ PSD_Steigung_1_A_Vorz m4  : 16|1@1+ (1.0,0.0) [0.0|1] ""  Gateway,Gateway_PAG
 SG_ PSD_Sys_Geschwindigkeit_Einheit m0  : 17|1@1+ (1.0,0.0) [0.0|1] ""  Gateway,Gateway_PAG
 SG_ PSD_Steigung_1_A_Offset m4  : 17|7@1+ (2,0) [0|254] "Unit_Meter"  Gateway,Gateway_PAG
 SG_ PSD_Sys_Verkehrsrichtung m0  : 18|1@1+ (1.0,0.0) [0.0|1] ""  Gateway,Gateway_PAG
 SG_ PSD_Sys_Geometrieguete m0  : 19|2@1+ (1.0,0.0) [0.0|3] ""  Gateway,Gateway_PAG
 SG_ PSD_Sys_Mapmatchingguete m0  : 21|2@1+ (1.0,0.0) [0.0|3] ""  Gateway,Gateway_PAG
 SG_ PSD_Attribut_3_Wert m1  : 21|4@1+ (1.0,0.0) [0.0|15] ""  Gateway,Gateway_PAG
 SG_ PSD_Ges_Typ m2  : 21|2@1+ (1.0,0.0) [0.0|3] ""  Gateway,Gateway_PAG
 SG_ PSD_Sys_Alter_Karte m0  : 23|3@1+ (1.0,0.0) [0.0|7] ""  Gateway,Gateway_PAG
 SG_ PSD_Ges_Spur_Geschw_Begrenzung m2  : 23|6@1+ (1.0,0.0) [0.0|63] ""  Gateway,Gateway_PAG
 SG_ PSD_Steigung_1_B_Steigung m4  : 24|7@1+ (0.12,0) [0.00|15.00] "Unit_PerCent"  Gateway,Gateway_PAG
 SG_ PSD_Attribut_4_ID m1  : 25|5@1+ (1,0) [1|31] ""  Gateway,Gateway_PAG
 SG_ PSD_Sys_Zielfuehrung m0  : 26|1@1+ (1.0,0.0) [0.0|1] ""  Gateway,Gateway_PAG,OTA_FC
 SG_ PSD_Sys_US_State m0  : 27|6@1+ (1.0,0.0) [0.0|63] ""  Gateway,Gateway_PAG
 SG_ PSD_Ges_Geschwindigkeit_Gespann m2  : 29|2@1+ (1.0,0.0) [0.0|3] ""  Gateway,Gateway_PAG
 SG_ PSD_Baum_Breite_VZ m3  : 29|1@1+ (1.0,0.0) [0.0|1] ""  Gateway,Gateway_PAG
 SG_ PSD_Attribut_4_Wert m1  : 30|4@1+ (1,0) [0|15] ""  Gateway,Gateway_PAG
 SG_ PSD_Baum_Breite m3  : 30|24@1+ (0.00001,0) [0.00000|90.00000] "Unit_DegreOfArc"  Gateway,Gateway_PAG
 SG_ PSD_Ges_Geschwindigkeit_Witter m2  : 31|2@1+ (1.0,0.0) [0.0|3] ""  Gateway,Gateway_PAG
 SG_ PSD_Steigung_1_B_Vorz m4  : 31|1@1+ (1.0,0.0) [0.0|1] ""  Gateway,Gateway_PAG
 SG_ PSD_Steigung_1_B_Offset m4  : 32|7@1+ (2,0) [0|254] "Unit_Meter"  Gateway,Gateway_PAG
 SG_ PSD_Sys_Quali_Geometrien m0  : 33|3@1+ (1,0) [0|7] "Unit_None"  Gateway,Gateway_PAG
 SG_ PSD_Ges_Geschwindigkeit_Tag_Anf m2  : 33|3@1+ (1.0,0.0) [0.0|7] ""  Gateway,Gateway_PAG
 SG_ PSD_Attribut_4_Offset m1  : 34|7@1+ (2,0) [0|254] "Unit_Meter"  Gateway,Gateway_PAG
 SG_ PSD_Sys_Quali_Ortsinfo m0  : 36|2@1+ (1,0) [0|3] "Unit_None"  Gateway,Gateway_PAG
 SG_ PSD_Ges_Geschwindigkeit_Tag_Ende m2  : 36|3@1+ (1.0,0.0) [0.0|7] ""  Gateway,Gateway_PAG
 SG_ PSD_Sys_Quali_verfuegbar m0  : 38|1@1+ (1.0,0.0) [0.0|1] ""  Gateway,Gateway_PAG
 SG_ PSD_Sys_Zielfuehrung_geaendert m0  : 39|1@1+ (1.0,0.0) [0.0|1] ""  Gateway,Gateway_PAG
 SG_ PSD_Ges_Geschwindigkeit_Std_Anf m2  : 39|5@1+ (1,0) [0|24] "Unit_Hours"  Gateway,Gateway_PAG
 SG_ PSD_Steigung_1_Attribute_kompl m4  : 39|1@1+ (1.0,0.0) [0.0|1] ""  Gateway,Gateway_PAG
 SG_ PSD_Sys_Geometrieguete_erweitert m0  : 40|8@1+ (1.0,0.0) [0.0|255] ""  Gateway,Gateway_PAG
 SG_ PSD_Steigung_2_Segment_ID m4  : 40|6@1+ (1,0) [2|63] ""  Gateway,Gateway_PAG
 SG_ PSD_Attribut_5_ID m1  : 41|5@1+ (1,0) [1|31] ""  Gateway,Gateway_PAG
 SG_ PSD_Ges_Geschwindigkeit_Std_Ende m2  : 44|5@1+ (1,0) [0|24] "Unit_Hours"  Gateway,Gateway_PAG
 SG_ PSD_Attribut_5_Offset m1  : 46|7@1+ (2,0) [0|254] "Unit_Meter"  Gateway,Gateway_PAG
 SG_ PSD_Steigung_2_Steigung m4  : 46|7@1+ (0.12,0) [0.00|15.00] "Unit_PerCent"  Gateway,Gateway_PAG
 SG_ PSD_Sys_Quali_sonstige_Attribute m0  : 48|3@1+ (1,0) [0|7] "Unit_None"  Gateway,Gateway_PAG
 SG_ PSD_Ges_Ueberholverbot m2  : 49|2@1+ (1.0,0.0) [0.0|3] ""  Gateway,Gateway_PAG
 SG_ PSD_Sys_Quali_Steigungen m0  : 51|3@1+ (1,0) [0|7] ""  Gateway,Gateway_PAG
 SG_ PSD_Ges_Wechselverkehrszeichen m2  : 51|3@1+ (1.0,0.0) [0.0|7] ""  Gateway,Gateway_PAG
 SG_ PSD_Attribut_5_Wert m1  : 53|4@1+ (1,0) [0|15] ""  Gateway,Gateway_PAG
 SG_ PSD_Steigung_2_Vorz m4  : 53|1@1+ (1.0,0.0) [0.0|1] ""  Gateway,Gateway_PAG
 SG_ PSD_Sys_Quali_Strassenkennz m0  : 54|3@1+ (1,0) [0|7] "Unit_None"  Gateway,Gateway_PAG
 SG_ PSD_Wechselverkehrszeichen_Typ m2  : 54|2@1+ (1.0,0.0) [0.0|3] ""  Gateway,Gateway_PAG
 SG_ PSD_Baum_Ausrichtung m3  : 54|10@1+ (0.3515625,0) [0E-7|359.6484375] "Unit_DegreOfArc"  Gateway,Gateway_PAG
 SG_ PSD_Steigung_2_Offset m4  : 54|7@1+ (2,0) [0|254] "Unit_Meter"  Gateway,Gateway_PAG
 SG_ PSD_Ges_Gesetzlich_Kategorie m2  : 56|3@1+ (1.0,0.0) [0.0|7] ""  Gateway,Gateway_PAG
 SG_ PSD_Sys_Quali_Tempolimits m0  : 57|3@1+ (1,0) [0|7] "Unit_None"  Gateway,Gateway_PAG
 SG_ PSD_Attribute_Komplett_06 m1  : 57|1@1+ (1.0,0.0) [0.0|1] ""  Gateway,Gateway_PAG
 SG_ PSD_Ges_Gesetzlich_Zusatz m2  : 59|2@1+ (1.0,0.0) [0.0|3] ""  Gateway,Gateway_PAG
 SG_ PSD_Sys_Quali_Vorfahrtsregelung m0  : 60|3@1+ (1,0) [0|7] "Unit_None"  Gateway,Gateway_PAG
 SG_ PSD_Ges_Verkehrszeichen_Quelle m2  : 61|2@1+ (1.0,0.0) [0.0|3] ""  Gateway,Gateway_PAG
 SG_ PSD_Steigung_2_Attribute_kompl m4  : 61|1@1+ (1.0,0.0) [0.0|1] ""  Gateway,Gateway_PAG
 SG_ PSD_Ges_Attribute_Komplett m2  : 63|1@1+ (1.0,0.0) [0.0|1] ""  Gateway,Gateway_PAG

BO_ 980 SMLS_01: 8 Gateway
 SG_ SMLS_01_CRC : 0|8@1+ (1,0) [0|255] ""  Vector__XXX
 SG_ SMLS_01_BZ : 8|4@1+ (1,0) [0|15] ""  Vector__XXX
 SG_ BH_Blinker_li : 12|1@1+ (1.0,0.0) [0.0|1] ""  ZR_High,ZR_Standard
 SG_ BH_Blinker_re : 13|1@1+ (1.0,0.0) [0.0|1] ""  ZR_High,ZR_Standard
 SG_ BH_Lichthupe : 14|1@1+ (1.0,0.0) [0.0|1] ""  ZR_High
 SG_ BH_Fernlicht : 15|1@1+ (1.0,0.0) [0.0|1] ""  ZR_High
 SG_ WH_Tipwischen : 16|1@1+ (1.0,0.0) [0.0|1] ""  ZR_High
 SG_ WH_Intervall : 17|1@1+ (1.0,0.0) [0.0|1] ""  ZR_High
 SG_ WH_WischerStufe1 : 18|1@1+ (1.0,0.0) [0.0|1] ""  ZR_High
 SG_ WH_WischerStufe2 : 19|1@1+ (1.0,0.0) [0.0|1] ""  ZR_High
 SG_ WH_Frontwaschen : 20|1@1+ (1.0,0.0) [0.0|1] ""  ZR_High
 SG_ WH_Heckintervall : 21|1@1+ (1.0,0.0) [0.0|1] ""  ZR_High
 SG_ WH_Heckwaschen : 22|1@1+ (1.0,0.0) [0.0|1] ""  ZR_High
 SG_ WH_Intervallstufen : 23|4@1+ (1.0,0.0) [0.0|15] ""  ZR_High
 SG_ FAS_Taster : 27|1@1+ (1.0,0.0) [0.0|1] ""  ZR_High,ZR_Standard
 SG_ FAS_Taster_Fehler : 28|1@1+ (1.0,0.0) [0.0|1] ""  ZR_High
 SG_ SMLS_Hupe : 29|1@1+ (1.0,0.0) [0.0|1] ""  Vector__XXX
 SG_ LRH_On_Off : 30|2@1+ (1.0,0.0) [0.0|3] ""  ZR_High
 SG_ LRH_aktiv : 40|1@1+ (1.0,0.0) [0.0|1] ""  ZR_High
 SG_ SMLS_P_verriegelt_plausibel : 43|1@1+ (1.0,0.0) [0.0|1] ""  Vector__XXX
 SG_ WH_SRA : 44|1@1+ (1.0,0.0) [0.0|1] ""  OTA_FC,ZR_High
 SG_ WH_Wischer_Fehler : 45|1@1+ (1.0,0.0) [0.0|1] ""  ZR_High
 SG_ BH_Blinker_Fehler : 46|1@1+ (1.0,0.0) [0.0|1] ""  ZR_High
 SG_ SMLS_PTT : 47|1@1+ (1.0,0.0) [0.0|1] ""  ZR_High,ZR_LIMU,ZR_MIB_TOP_ab_Gen3,ZR_Standard
 SG_ WH_Tipwischen_lang : 48|1@1+ (1.0,0.0) [0.0|1] ""  ZR_High

BO_ 1710 Spiegel_01: 8 Gateway
 SG_ SP_FT_oben : 0|1@1+ (1.0,0.0) [0.0|1] ""  OTA_FC,ZR_High
 SG_ SP_FT_unten : 1|1@1+ (1.0,0.0) [0.0|1] ""  OTA_FC,ZR_High
 SG_ SP_FT_links : 2|1@1+ (1.0,0.0) [0.0|1] ""  OTA_FC,ZR_High
 SG_ SP_FT_rechts : 3|1@1+ (1.0,0.0) [0.0|1] ""  OTA_FC,ZR_High
 SG_ SP_BT_oben : 4|1@1+ (1.0,0.0) [0.0|1] ""  OTA_FC,ZR_High
 SG_ SP_BT_unten : 5|1@1+ (1.0,0.0) [0.0|1] ""  OTA_FC,ZR_High
 SG_ SP_BT_links : 6|1@1+ (1.0,0.0) [0.0|1] ""  OTA_FC,ZR_High
 SG_ SP_BT_rechts : 7|1@1+ (1.0,0.0) [0.0|1] ""  OTA_FC,ZR_High
 SG_ SP_abklappen : 8|1@1+ (1.0,0.0) [0.0|1] ""  OTA_FC,ZR_High
 SG_ SP_anklappen : 9|1@1+ (1.0,0.0) [0.0|1] ""  OTA_FC,ZR_High
 SG_ SP_normieren : 10|1@1+ (1.0,0.0) [0.0|1] ""  OTA_FC,ZR_High
 SG_ SP_Hzg_Taster : 12|1@1+ (1.0,0.0) [0.0|1] ""  OTA_FC,ZR_High
 SG_ SP_S_oben : 16|1@1+ (1.0,0.0) [0.0|1] ""  ZR_High
 SG_ SP_S_unten : 17|1@1+ (1.0,0.0) [0.0|1] ""  ZR_High
 SG_ SP_S_links : 18|1@1+ (1.0,0.0) [0.0|1] ""  ZR_High
 SG_ SP_S_rechts : 19|1@1+ (1.0,0.0) [0.0|1] ""  ZR_High
 SG_ SP_Auswahl_li : 20|1@1+ (1.0,0.0) [0.0|1] ""  ZR_High
 SG_ SP_Auswahl_re : 21|1@1+ (1.0,0.0) [0.0|1] ""  ZR_High
 SG_ SP_ARA_Status : 22|1@1+ (1.0,0.0) [0.0|1] ""  ZR_High
 SG_ SP_S_Klappen : 23|1@1+ (1.0,0.0) [0.0|1] ""  ZR_High
 SG_ SP_Verstellschalter_Fehler : 24|1@1+ (1.0,0.0) [0.0|1] ""  ZR_High

BO_ 605 KLR_01: 8 Gateway
 SG_ CHECKSUM : 0|8@1+ (1,0) [0|255] ""  Vector__XXX
 SG_ COUNTER : 8|4@1+ (1,0) [0|15] ""  Vector__XXX
 SG_ KLR_Fehler : 12|1@1+ (1.0,0.0) [0.0|1] ""  Vector__XXX
 SG_ KLR_ResponseError : 13|1@1+ (1.0,0.0) [0.0|1] ""  Vector__XXX
 SG_ KLR_Lokalaktiv : 14|1@1+ (1.0,0.0) [0.0|1] ""  Vector__XXX
 SG_ KLR_Fehler_Codierung : 15|1@1+ (1.0,0.0) [0.0|1] ""  Vector__XXX
 SG_ KLR_Touchintensitaet_1 : 16|8@1+ (1,0) [0|250] "Unit_None"  Vector__XXX
 SG_ KLR_Touchintensitaet_2 : 24|8@1+ (1,0) [0|250] "Unit_None"  Vector__XXX
 SG_ KLR_Touchintensitaet_3 : 32|8@1+ (1,0) [0|250] "Unit_None"  Vector__XXX
 SG_ KLR_Touchauswertung : 40|4@1+ (1.0,0.0) [0.0|15] ""  ZR_High

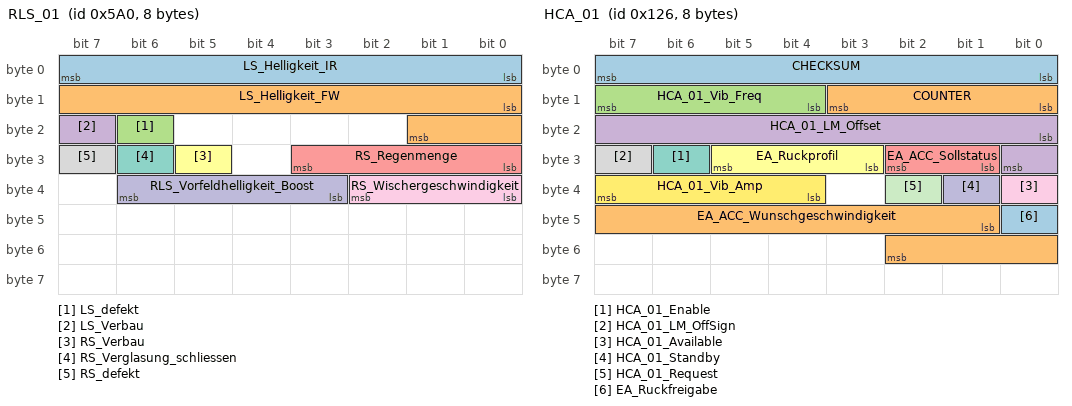
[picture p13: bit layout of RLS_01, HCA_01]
BO_ 1440 RLS_01: 8 Gateway
 SG_ LS_Helligkeit_IR : 0|8@1+ (400,0) [0|101200] "Unit_Lux"  ZR_High
 SG_ LS_Helligkeit_FW : 8|10@1+ (6,0) [0|6126] "Unit_Lux"  ZR_High
 SG_ LS_defekt : 22|1@1+ (1.0,0.0) [0.0|1] ""  ZR_High
 SG_ LS_Verbau : 23|1@1+ (1.0,0.0) [0.0|1] ""  ZR_High
 SG_ RS_Regenmenge : 24|4@1+ (10,0) [0|100] "Unit_PerCent"  OTA_FC,ZR_High
 SG_ RS_Verbau : 29|1@1+ (1.0,0.0) [0.0|1] ""  ZR_High
 SG_ RS_Verglasung_schliessen : 30|1@1+ (1.0,0.0) [0.0|1] ""  ZR_High
 SG_ RS_defekt : 31|1@1+ (1.0,0.0) [0.0|1] ""  ZR_High
 SG_ RS_Wischergeschwindigkeit : 32|3@1+ (1.0,0.0) [0.0|7] ""  OTA_FC,ZR_High
 SG_ RLS_Vorfeldhelligkeit_Boost : 35|4@1+ (1.0,0.0) [0.0|15] ""  ZR_High

BO_ 294 HCA_01: 8 Frontsensorik
 SG_ CHECKSUM : 0|8@1+ (1,0) [0|255] "" Vector__XXX
 SG_ COUNTER : 8|4@1+ (1,0) [0|15] "" Vector__XXX
 SG_ HCA_01_Vib_Freq : 12|4@1+ (1,15) [18|30] "Unit_Hertz" Vector__XXX
 SG_ HCA_01_LM_Offset : 16|9@1+ (1,0) [0|511] "Unit_centiNewtoMeter" Vector__XXX
 SG_ EA_ACC_Sollstatus : 25|2@1+ (1,0) [0|3] ""  Frontradar
 SG_ EA_Ruckprofil : 27|3@1+ (1,0) [0|7] "" Vector__XXX
 SG_ HCA_01_Enable : 30|1@1+ (1,0) [0|1] "" Vector__XXX
 SG_ HCA_01_LM_OffSign : 31|1@1+ (1,0) [0|1] "" Vector__XXX
 SG_ HCA_01_Available : 32|1@1+ (1,0) [0|1] "" Vector__XXX
 SG_ HCA_01_Standby : 33|1@1+ (1,0) [0|1] "" Vector__XXX
 SG_ HCA_01_Request : 34|1@1+ (1,0) [0|1] "" Vector__XXX
 SG_ HCA_01_Vib_Amp : 36|4@1+ (0.2,0) [0|3] "Unit_NewtoMeter" Vector__XXX
 SG_ EA_Ruckfreigabe : 40|1@1+ (1,0) [0|1] "" Vector__XXX
 SG_ EA_ACC_Wunschgeschwindigkeit : 41|10@1+ (0.32,0) [0|327.04] "Unit_KiloMeterPerHour"  Frontradar

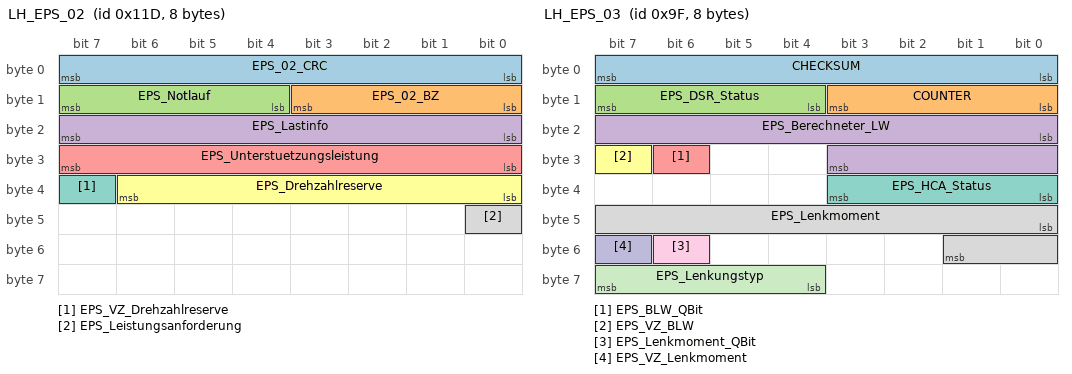
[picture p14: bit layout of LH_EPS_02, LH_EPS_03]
BO_ 285 LH_EPS_02: 8 Gateway_D4C7
 SG_ EPS_02_CRC : 0|8@1+ (1,0) [0|255] ""  SCU_D4
 SG_ EPS_02_BZ : 8|4@1+ (1,0) [0|15] ""  SCU_D4
 SG_ EPS_Notlauf : 12|4@1+ (1.0,0.0) [0.0|15] ""  Vector__XXX
 SG_ EPS_Lastinfo : 16|8@1+ (1,0) [0|253] "Unit_Amper"  Vector__XXX
 SG_ EPS_Unterstuetzungsleistung : 24|8@1+ (0.5,0) [0.0|100.0] "Unit_PerCent"  SCU_D4
 SG_ EPS_Drehzahlreserve : 32|7@1+ (10,0) [0|1000] "Unit_DegreOfArcPerSecon"  SCU_D4
 SG_ EPS_VZ_Drehzahlreserve : 39|1@1+ (1.0,0.0) [0.0|1] ""  SCU_D4
 SG_ EPS_Leistungsanforderung : 40|1@1+ (1.0,0.0) [0.0|1] ""  Vector__XXX

BO_ 159 LH_EPS_03: 8 XXX
 SG_ CHECKSUM : 0|8@1+ (1,0) [0|255] ""  XXX
 SG_ COUNTER : 8|4@1+ (1,0) [0|15] ""  XXX
 SG_ EPS_DSR_Status : 12|4@1+ (1,0) [0|15] ""  XXX
 SG_ EPS_Berechneter_LW : 16|12@1+ (0.15,0) [0|613.95] "Unit_DegreOfArc"  XXX
 SG_ EPS_BLW_QBit : 30|1@1+ (1,0) [0|1] ""  XXX
 SG_ EPS_VZ_BLW : 31|1@1+ (1,0) [0|1] ""  XXX
 SG_ EPS_HCA_Status : 32|4@1+ (1,0) [0|15] ""  XXX
 SG_ EPS_Lenkmoment : 40|10@1+ (1,0) [0|8] "Unit_centiNewtoMeter"  XXX
 SG_ EPS_Lenkmoment_QBit : 54|1@1+ (1,0) [0|1] ""  XXX
 SG_ EPS_VZ_Lenkmoment : 55|1@1+ (1,0) [0|1] ""  XXX
 SG_ EPS_Lenkungstyp : 60|4@1+ (1,0) [0|15] ""  XXX

BO_ 919 LDW_02: 8 XXX
 SG_ LDW_Gong : 12|2@1+ (1,0) [0|3] ""  XXX
 SG_ LDW_SW_Warnung_links : 14|1@1+ (1,0) [0|1] ""  XXX
 SG_ LDW_SW_Warnung_rechts : 15|1@1+ (1,0) [0|1] ""  XXX
 SG_ LDW_Texte : 16|4@1+ (1,0) [0|15] ""  XXX
 SG_ LDW_Seite_DLCTLC : 20|1@1+ (1,0) [0|1] ""  XXX
 SG_ LDW_Lernmodus : 21|3@1+ (1,0) [0|7] ""  XXX
 SG_ LDW_Anlaufsp_VLR : 24|4@1+ (1,0) [0|15] ""  XXX
 SG_ LDW_Vib_Amp_VLR : 28|4@1+ (1,0) [0|15] ""  XXX
 SG_ LDW_Anlaufzeit_VLR : 32|4@1+ (1,0) [0|15] ""  XXX
 SG_ LDW_Lernmodus_rechts : 36|2@1+ (1,0) [0|3] ""  XXX
 SG_ LDW_Lernmodus_links : 38|2@1+ (1,0) [0|3] ""  XXX
 SG_ LDW_DLC : 40|8@1+ (0.01,-1.25) [-1.25|1.25] "Unit_Meter"  XXX
 SG_ LDW_TLC : 48|5@1+ (0.1,0) [0|3] "Unit_Secon"  XXX
 SG_ LDW_Warnung_links : 56|1@1+ (1,0) [0|1] ""  XXX
 SG_ LDW_Warnung_rechts : 57|1@1+ (1,0) [0|1] ""  XXX
 SG_ LDW_Codierinfo_fuer_VLR : 58|2@1+ (1,0) [0|3] ""  XXX
 SG_ LDW_Frontscheibenheizung_aktiv : 60|1@1+ (1,0) [0|1] ""  XXX
 SG_ LDW_Status_LED_gelb : 61|1@1+ (1,0) [0|1] ""  XXX
 SG_ LDW_Status_LED_gruen : 62|1@1+ (1,0) [0|1] ""  XXX
 SG_ LDW_KD_Fehler : 63|1@1+ (1,0) [0|1] ""  XXX

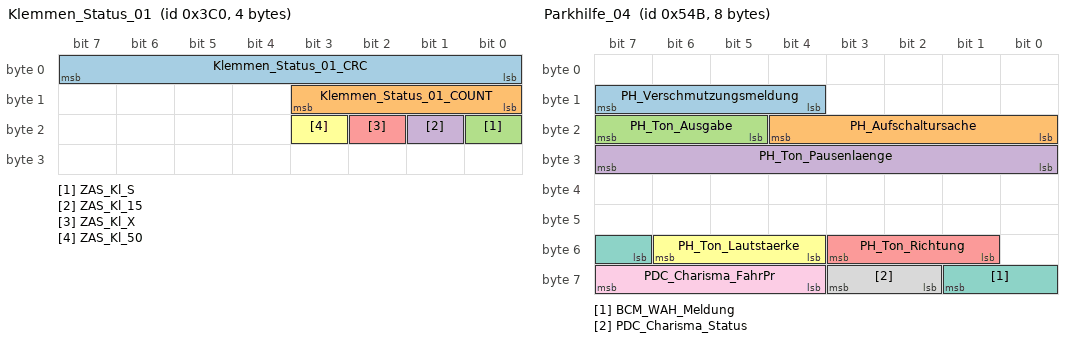
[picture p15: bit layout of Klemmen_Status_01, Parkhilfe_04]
BO_ 960 Klemmen_Status_01: 4 Gateway_MQB
 SG_ Klemmen_Status_01_CRC : 0|8@1+ (1,0) [0|255] "" Airbag_MQB,BMS_MQB,Motor_Diesel_MQB,Motor_Hybrid_MQB,Motor_Otto_MQB
 SG_ Klemmen_Status_01_COUNT : 8|4@1+ (1,0) [0|15] "" Airbag_MQB,BMS_MQB,Motor_Diesel_MQB,Motor_Hybrid_MQB,Motor_Otto_MQB
 SG_ ZAS_Kl_S : 16|1@1+ (1,0) [0|1] "" Vector__XXX
 SG_ ZAS_Kl_15 : 17|1@1+ (1,0) [0|1] "" Airbag_MQB,BMS_MQB,Motor_Diesel_MQB,Motor_Hybrid_MQB,Motor_Otto_MQB
 SG_ ZAS_Kl_X : 18|1@1+ (1,0) [0|1] "" Vector__XXX
 SG_ ZAS_Kl_50 : 19|1@1+ (1,0) [0|1] "" Vector__XXX

BO_ 1175 Parkhilfe_01: 8 Gateway
 SG_ PH_Visualisierung : 0|3@1+ (1,0) [0|7] ""  AWC
 SG_ PDC_Tonausgabe_Front : 4|4@1+ (1,0) [0|15] "" Vector__XXX
 SG_ PDC_Tonausgabe_Heck : 8|4@1+ (1,0) [0|15] "" Vector__XXX
 SG_ PH_nachtr_Stopp_Anf : 12|1@1+ (1,0) [0|1] "" Vector__XXX
 SG_ PH_Abschaltursache : 13|3@1+ (1,0) [0|7] ""  AWC
 SG_ PH_Opt_Anzeige_V_ein : 16|1@1+ (1,0) [0|1] "" Vector__XXX
 SG_ PH_Opt_Anzeige_H_ein : 17|1@1+ (1,0) [0|1] "" Vector__XXX
 SG_ PH_Opt_Anz_V_Hindernis : 18|1@1+ (1,0) [0|1] "" Vector__XXX
 SG_ PH_Opt_Anz_H_Hindernis : 19|1@1+ (1,0) [0|1] "" Vector__XXX
 SG_ PH_Tongeber_V_aktiv : 20|1@1+ (1,0) [0|1] "" Vector__XXX
 SG_ PH_Tongeber_H_aktiv : 21|1@1+ (1,0) [0|1] "" Vector__XXX
 SG_ PH_Tongeber_mute : 22|1@1+ (1,0) [0|1] "" Vector__XXX
 SG_ PH_Anf_Audioabsenkung : 23|1@1+ (1,0) [0|1] "" Vector__XXX
 SG_ PH_Tongeber_H_verfuegbar : 24|1@1+ (1,0) [0|1] "" Vector__XXX
 SG_ PLA_Anf_Aufschaltung_RVC : 25|1@1+ (1,0) [0|1] "" Vector__XXX
 SG_ PH_Taster : 28|2@1+ (1,0) [0|3] "" Vector__XXX
 SG_ PH_Anf_Verdeck : 30|2@1+ (1,0) [0|3] "" Vector__XXX
 SG_ PH_Frequenz_hinten : 32|4@1+ (1,0) [0|15] "" Vector__XXX
 SG_ PH_Lautstaerke_hinten : 36|4@1+ (1,0) [0|15] "" Vector__XXX
 SG_ PH_Frequenz_vorn : 40|4@1+ (1,0) [0|15] "" Vector__XXX
 SG_ PH_Lautstaerke_vorn : 44|4@1+ (1,0) [0|15] "" Vector__XXX
 SG_ PH_StartStopp_Info : 49|2@1+ (1,0) [0|3] "" Vector__XXX
 SG_ PH_Stoermeldung : 52|4@1+ (1,0) [0|15] "" Vector__XXX
 SG_ PH_defekt : 56|1@1+ (1,0) [0|1] "" Vector__XXX
 SG_ PH_gestoert : 57|1@1+ (1,0) [0|1] "" Vector__XXX
 SG_ PH_Systemzustand : 58|3@1+ (1,0) [0|7] ""  AWC
 SG_ PH_Display_Kundenwunsch : 61|2@1+ (1,0) [0|3] "" Vector__XXX

BO_ 1355 Parkhilfe_04: 8 Gateway
 SG_ PH_Verschmutzungsmeldung : 12|4@1+ (1,0) [0|15] "" Vector__XXX
 SG_ PH_Aufschaltursache : 16|5@1+ (1,0) [0|31] ""  AWC
 SG_ PH_Ton_Ausgabe : 21|3@1+ (1,0) [0|7] "" Vector__XXX
 SG_ PH_Ton_Pausenlaenge : 24|8@1+ (1,0) [0|255] "" Vector__XXX
 SG_ PH_Ton_Richtung : 49|3@1+ (1,0) [0|7] "" Vector__XXX
 SG_ PH_Ton_Lautstaerke : 52|3@1+ (1,0) [0|7] "" Vector__XXX
 SG_ BCM_WAH_Meldung : 55|3@1+ (1,0) [0|7] "" Vector__XXX
 SG_ PDC_Charisma_Status : 58|2@1+ (1,0) [0|3] "" Vector__XXX
 SG_ PDC_Charisma_FahrPr : 60|4@1+ (1,0) [0|15] "" Vector__XXX

BO_ 896 MEB_PDC_01: 8 XXX
 SG_ Active : 54|1@0+ (1,0) [0|1] "" XXX
 SG_ Distance : 55|9@1+ (1,0) [0|255] "" XXX

BO_ 252 MEB_ESP_01: 48 XXX
 SG_ CHECKSUM : 0|8@1+ (1,0) [0|255] "" XXX
 SG_ COUNTER : 8|4@1+ (1,0) [0|15] "" XXX
 SG_ AEB_Breaking_01 : 24|8@1+ (1,0) [0|255] "" XXX
 SG_ AEB_Breaking_02 : 32|8@1+ (1,0) [0|255] "" XXX
 SG_ Accelerator_Higher_Speed : 40|1@0+ (1,0) [0|1] "" XXX
 SG_ Brake_Pressure : 42|9@1+ (0.195,0) [0|100] "Unit_Percent" XXX
 SG_ HL_Radgeschw : 64|16@1+ (0.0075,0) [0|491.5125] "Unit_KilometerPerHour" XXX
 SG_ HR_Radgeschw : 80|16@1+ (0.0075,0) [0|491.5125] "Unit_KilometerPerHour" XXX
 SG_ VL_Radgeschw : 96|16@1+ (0.0075,0) [0|491.5125] "Unit_KilometerPerHour" XXX
 SG_ VR_Radgeschw : 112|16@1+ (0.0075,0) [0|491.5125] "Unit_KilometerPerHour" XXX
 SG_ HL_Brake_Pressure : 152|8@1+ (1,0) [0|100] "" XXX
 SG_ HR_Brake_Pressure : 160|8@1+ (1,0) [0|100] "" XXX
 SG_ VL_Brake_Pressure : 168|8@1+ (1,0) [0|100] "" XXX
 SG_ VR_Brake_Pressure : 176|8@1+ (1,0) [0|100] "" XXX
 SG_ Steering_Wheel_CW : 184|8@1+ (1.67,0) [0|255] "" XXX
 SG_ Steering_Wheel_CCW : 192|8@1+ (1.67,0) [0|255] "" XXX

BO_ 192 MEB_ESP_02: 32 XXX
 SG_ Schubbetrieb : 79|1@0+ (1,0) [0|1] "" XXX

BO_ 332 MEB_ESP_03: 32 XXX
 SG_ CHECKSUM : 0|8@1+ (1,0) [0|255] "" XXX
 SG_ COUNTER : 8|4@1+ (1,0) [0|15] "" XXX
 SG_ Accelerator_Pressure : 175|8@0+ (0.391,-14.467) [0|100] "Unit_Percent" XXX

BO_ 258 MEB_ESP_04: 48 XXX
 SG_ CHECKSUM : 0|8@1+ (1,0) [0|255] "" XXX
 SG_ COUNTER : 8|4@1+ (1,0) [0|15] "" XXX
 SG_ Lateral_Accel : 16|8@1+ (0.15,-18.9) [0|255] "Unit_MeterPerSquareSecond" XXX
 SG_ Longitudinal_Accel : 24|10@1+ (0.03125,-16) [0|255] "Unit_MeterPerSquareSecond" XXX
 SG_ Yaw_Rate : 40|14@1+ (0.01,0) [0|16383] "Unit_DegreePerSecond" XXX
 SG_ Yaw_Rate_Sign : 54|1@0+ (1,0) [0|1] "" XXX
 SG_ Regen_Braking : 123|1@1+ (1,0) [0|7] "" XXX
 SG_ Standstill : 171|1@0+ (1,0) [0|1] "" XXX
 SG_ Longitudinal_Speed : 181|10@1+ (0.25,0) [0|255] "Unit_KilometerPerHour" XXX

BO_ 313 MEB_ESP_05: 32 XXX
 SG_ CHECKSUM : 0|8@1+ (1,0) [0|255] "" XXX
 SG_ COUNTER : 8|4@1+ (1,0) [0|15] "" XXX
 SG_ Brake_Pressed_1 : 16|1@0+ (1,0) [0|1] "" XXX
 SG_ Brake_Pressed_2 : 27|1@0+ (1,0) [0|1] "" XXX
 SG_ AEB_Active : 31|1@0+ (1,0) [0|1] "" XXX
 SG_ ESP_Hold : 35|1@0+ (1,0) [0|1] "" XXX
 SG_ Brake_Pressed_3 : 48|1@0+ (1,0) [0|1] "" XXX
 SG_ FCW_Active : 56|1@1+ (1,0) [0|1] "" XXX
 SG_ Brake_Pressure : 76|11@1+ (1,0) [0|100] "" XXX

BO_ 522 MEB_ABS_01: 64 XXX
 SG_ CHECKSUM : 0|8@1+ (1,0) [0|255] "" XXX
 SG_ COUNTER : 8|4@1+ (1,0) [0|15] "" XXX
 SG_ Yaw_Rate_VZ : 33|1@1+ (1,0) [0|1] "" XXX
 SG_ Yaw_Rate : 200|16@1+ (0.007,-229.34) [0|255] "" XXX

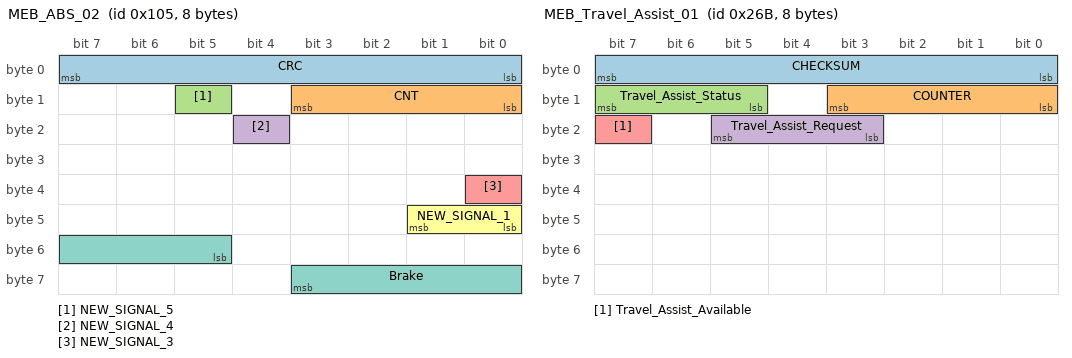
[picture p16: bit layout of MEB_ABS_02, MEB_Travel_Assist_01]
BO_ 261 MEB_ABS_02: 8 XXX
 SG_ CRC : 0|8@1+ (1,0) [0|255] "" XXX
 SG_ CNT : 8|4@1+ (1,0) [0|15] "" XXX
 SG_ NEW_SIGNAL_5 : 13|1@0+ (1,0) [0|1] "" XXX
 SG_ NEW_SIGNAL_4 : 20|1@0+ (1,0) [0|1] "" XXX
 SG_ NEW_SIGNAL_3 : 32|1@0+ (1,0) [0|1] "" XXX
 SG_ NEW_SIGNAL_1 : 40|2@1+ (1,0) [0|3] "" XXX
 SG_ Brake : 53|7@1+ (1,0) [0|3] "" XXX

BO_ 988 MEB_EPB_01: 8 XXX
 SG_ EPB_Status : 53|3@1+ (1,0) [0|7] "" XXX

BO_ 317 MEB_EPS_01: 32 XXX
 SG_ CHECKSUM : 0|8@1+ (1,0) [0|255] "" XXX
 SG_ COUNTER : 8|4@1+ (1,0) [0|15] "" XXX
 SG_ LatCon_HCA_Accept : 17|2@1+ (1,0) [0|3] "" XXX
 SG_ LatCon_HCA_Status : 20|3@1+ (1,0) [0|15] "" XXX
 SG_ Steering_Angle_VZ_02 : 36|1@0+ (1,0) [0|1] "" XXX
 SG_ Steering_Angle_02 : 40|15@1+ (0.0171,0) [0|65535] "" XXX
 SG_ Steering_Angle_VZ : 55|1@0+ (1,0) [0|1] "" XXX
 SG_ Steering_Angle : 76|17@1+ (0.00906,0) [0|32767] "" XXX

BO_ 771 HCA_03: 24 XXX
 SG_ Standby : 13|1@1+ (1,0) [0|1] "" XXX
 SG_ Request : 14|1@1+ (1,0) [0|1] "" XXX
 SG_ Unknown_02 : 15|1@1+ (1,0) [0|1] "" XXX
 SG_ Power : 16|7@1+ (1,0) [0|125] "" XXX
 SG_ Power_Boost : 23|1@1+ (1,0) [0|1] "" XXX
 SG_ Curvature : 24|15@1+ (0.0000067,0) [0|0.219] "Unit_rad/m" XXX
 SG_ VZ : 39|1@1+ (1,0) [0|1] "" XXX
 SG_ Unknown_01 : 53|1@0+ (1,0) [0|1] "" XXX
 SG_ Vibration : 56|1@0+ (1,0) [0|1] "" XXX
 SG_ Active : 66|1@1+ (1,0) [0|1] "" XXX

BO_ 267 MEB_Motor_01: 32 XXX
 SG_ CHECKSUM : 0|8@1+ (1,0) [0|255] "" XXX
 SG_ COUNTER : 8|4@1+ (1,0) [0|15] "" XXX
 SG_ Accel_Pedal_Pressure : 12|9@1+ (0.4,0) [0|255] "" XXX
 SG_ Accel_Low_Pressed_Support : 21|1@1+ (1,0) [0|7] "" XXX
 SG_ TSK_Status : 88|3@1+ (1,0) [0|7] "" XXX
 SG_ TSK_Limiter_ausgewaehlt : 95|1@1+ (1,0) [0|3] "" XXX

BO_ 588 MEB_Side_Assist_01: 16 XXX
 SG_ Blind_Spot_Right : 12|7@1+ (1,0) [0|15] "" XXX
 SG_ Blind_Spot_Left : 19|7@1+ (1,0) [0|15] "" XXX
 SG_ Blind_Spot_Warn_Right : 26|1@0+ (1,0) [0|1] "" XXX
 SG_ Blind_Spot_Pre_Warn_Right : 27|1@0+ (1,0) [0|1] "" XXX
 SG_ Blind_Spot_Warn_Left : 29|1@0+ (1,0) [0|1] "" XXX
 SG_ Blind_Spot_Pre_Warn_Left : 30|1@0+ (1,0) [0|1] "" XXX
 SG_ Lower_Speed_01 : 32|1@0+ (1,0) [0|1] "" XXX
 SG_ Higher_Speed_01 : 33|1@0+ (1,0) [0|1] "" XXX
 SG_ Higher_Speed_02 : 83|1@0+ (1,0) [0|1] "" XXX
 SG_ Lower_Speed_02 : 84|1@0+ (1,0) [0|1] "" XXX
 SG_ Standstill : 86|1@0+ (1,0) [0|1] "" XXX
 SG_ NEW_SIGNAL_1 : 98|1@0+ (1,0) [0|1] "" XXX
 SG_ NEW_SIGNAL_6 : 119|1@0+ (1,0) [0|1] "" XXX

BO_ 589 MEB_Side_Assist_02: 64 XXX
 SG_ Unknown_01 : 100|3@0+ (1,0) [0|7] "" XXX
 SG_ Unknown_02 : 108|3@0+ (1,0) [0|7] "" XXX

BO_ 591 MEB_Distance_01: 64 XXX
 SG_ Unknown_01 : 12|1@0+ (1,0) [0|1] "" XXX
 SG_ Same_Lane_01_ObjectID : 16|6@1+ (1,0) [0|63] "Unit_ObjectID" XXX
 SG_ Left_Lane_01_ObjectID : 22|6@1+ (1,0) [0|63] "Unit_ObjectID" XXX
 SG_ Right_Lane_01_ObjectID : 28|6@1+ (1,0) [0|63] "Unit_ObjectID" XXX
 SG_ Same_Lane_02_ObjectID : 34|6@1+ (1,0) [0|63] "Unit_ObjectID" XXX
 SG_ Left_Lane_02_ObjectID : 40|6@1+ (1,0) [0|63] "Unit_ObjectID" XXX
 SG_ Right_Lane_02_ObjectID : 46|6@1+ (1,0) [0|63] "Unit_ObjectID" XXX
 SG_ Unknown_02 : 52|2@1+ (1,0) [0|3] "" XXX
 SG_ Unknown_03 : 54|10@1+ (1,0) [0|3] "" XXX
 SG_ Same_Lane_01_Long_Distance : 64|12@1+ (0.07,-6) [0|300] "Unit_Meter" XXX
 SG_ Same_Lane_01_Lat_Distance : 76|10@1+ (0.065,-33.28) [-50|50] "Unit_Meter" XXX
 SG_ Same_Lane_01_Rel_Velo : 86|10@1+ (0.25,-128) [-100|100] "Unit_MeterPerSecond" XXX
 SG_ Left_Lane_01_Long_Distance : 96|12@1+ (0.07,-6) [0|300] "Unit_Meter" XXX
 SG_ Left_Lane_01_Lat_Distance : 108|10@1+ (0.065,-33.28) [-50|50] "Unit_Meter" XXX
 SG_ Left_Lane_01_Rel_Velo : 118|10@1+ (0.25,-128) [-100|100] "Unit_MeterPerSecond" XXX
 SG_ Right_Lane_01_Long_Distance : 128|12@1+ (0.07,-6) [0|300] "Unit_Meter" XXX
 SG_ Right_Lane_01_Lat_Distance : 140|10@1+ (0.065,-33.28) [-50|50] "Unit_Meter" XXX
 SG_ Right_Lane_01_Rel_Velo : 150|10@1+ (0.25,-128) [-100|100] "Unit_MeterPerSecond" XXX
 SG_ Same_Lane_02_Long_Distance : 160|12@1+ (0.07,-6) [0|300] "Unit_Meter" XXX
 SG_ Same_Lane_02_Lat_Distance : 172|10@1+ (0.065,-33.28) [-50|50] "Unit_Meter" XXX
 SG_ Same_Lane_02_Rel_Velo : 182|10@1+ (0.25,-128) [-100|100] "Unit_MeterPerSecond" XXX
 SG_ Left_Lane_02_Long_Distance : 192|12@1+ (0.07,-6) [0|300] "Unit_Meter" XXX
 SG_ Left_Lane_02_Lat_Distance : 204|10@1+ (0.065,-33.28) [-50|50] "Unit_Meter" XXX
 SG_ Left_Lane_02_Rel_Velo : 214|10@1+ (0.25,-128) [-100|100] "Unit_MeterPerSecond" XXX
 SG_ Right_Lane_02_Long_Distance : 224|12@1+ (0.07,-6) [0|300] "Unit_Meter" XXX
 SG_ Right_Lane_02_Lat_Distance : 236|10@1+ (0.065,-33.28) [-50|50] "Unit_Meter" XXX
 SG_ Right_Lane_02_Rel_Velo : 246|10@1+ (0.25,-128) [-100|100] "Unit_MeterPerSecond" XXX
 SG_ Unknown_04 : 256|8@1+ (1,-128) [0|31] "" XXX
 SG_ Unknown_05 : 264|6@1+ (1,-15) [0|31] "" XXX
 SG_ Unknown_06 : 270|6@1+ (1,0) [0|127] "" XXX
 SG_ Unknown_07 : 277|6@1+ (1,0) [0|7] "" XXX
 SG_ Unknown_08 : 284|6@1+ (1,0) [0|1] "" XXX

BO_ 219 MEB_AEB_01: 48 XXX
 SG_ CHK : 0|8@1+ (1,0) [0|255] "" XXX
 SG_ CNT : 8|4@1+ (1,0) [0|15] "" XXX
 SG_ FCW_Active : 64|1@0+ (1,0) [0|1] "" XXX
 SG_ Pre_Brake_Fill : 76|1@0+ (1,0) [0|1] "" XXX

BO_ 518 MEB_AEB_02: 24 XXX
 SG_ CHK : 0|8@1+ (1,0) [0|255] "" XXX
 SG_ CNT : 8|4@1+ (1,0) [0|15] "" XXX
 SG_ AEB_Active : 16|1@0+ (1,0) [0|1] "" XXX

BO_ 768 MEB_ACC_01: 48 XXX
 SG_ ACC_Tempolimit : 64|5@1+ (1,0) [0|31] "" OTA_FC
 SG_ ACC_Wunschgeschw_Farbe : 69|1@1+ (1,0) [0|1] "" Vector__XXX
 SG_ ACC_Warnung_Verkehrszeichen_1 : 70|1@1+ (1,0) [0|1] "" Vector__XXX
 SG_ ACA_Querfuehrung : 71|2@1+ (1,0) [0|3] "" Vector__XXX
 SG_ Unknown_02 : 73|1@0+ (1,0) [0|1] "" XXX
 SG_ ACC_Regelung_AIO : 75|1@1+ (1,0) [0|1] "" ZR_High,ZR_LIMU,ZR_MIB_TOP_ab_Gen3
 SG_ ACC_Wunschgeschw_02 : 76|10@1+ (0.32,0) [0|327.04] "Unit_KiloMeterPerHour" Vector__XXX
 SG_ ACC_Abstandsindex_02 : 86|10@1+ (1,0) [1|1021] "" Vector__XXX
 SG_ ACC_Display_Prio : 96|2@1+ (1,0) [0|3] "" Vector__XXX
 SG_ ACC_rel_Objekt_Zusatzanz : 98|2@1+ (1,0) [0|3] "" Vector__XXX
 SG_ ACC_Gesetzte_Zeitluecke : 101|3@1+ (1,0) [0|7] "" Vector__XXX
 SG_ ACC_Optischer_Fahrerhinweis : 104|1@1+ (1,0) [0|1] "" Vector__XXX
 SG_ ACC_Warnhinweis : 105|1@1+ (1,0) [0|1] "" Vector__XXX
 SG_ ACC_EGO_Fahrzeug : 106|3@1+ (1,0) [0|7] "" Vector__XXX
 SG_ ACC_Relevantes_Objekt_02 : 109|2@1+ (1,0) [0|3] "" OTA_FC,ZR_High,ZR_LIMU,ZR_MIB_TOP_ab_Gen3
 SG_ ACC_Wunschgeschw_erreicht : 112|1@1+ (1,0) [0|1] "" OTA_FC
 SG_ ACC_Anzeige_Zeitluecke : 113|1@1+ (1,0) [0|1] "" Vector__XXX
 SG_ ACC_Texte_Primaeranz_02 : 114|6@1+ (1,0) [0|63] "" Vector__XXX
 SG_ ACC_Texte_Zusatzanz_02 : 120|6@1+ (1,0) [0|63] "" Vector__XXX
 SG_ STA_Primaeranz : 126|2@1+ (1,0) [0|3] "" Vector__XXX
 SG_ SET_ME_0X3FF : 140|10@1+ (1,0) [0|15] "" XXX
 SG_ Heartbeat : 150|9@1+ (1,0) [0|3] "" XXX
 SG_ SET_ME_0XFFFF : 160|16@1+ (1,0) [0|65535] "" XXX
 SG_ ACC_Enabled : 186|1@0+ (1,0) [0|1] "" XXX
 SG_ Zeitluecke_Farbe : 189|1@0+ (1,0) [0|1] "" XXX
 SG_ SET_ME_0X1 : 199|1@0+ (1,0) [0|1] "" XXX
 SG_ ACC_Status_ACC : 208|3@1+ (1,0) [0|7] "" XXX
 SG_ ACC_Akustischer_Fahrerhinweis : 211|2@1+ (1,0) [0|1] "" XXX
 SG_ Unknown_08 : 224|1@0+ (1,0) [0|1] "" XXX
 SG_ Unknown_01 : 225|1@0+ (1,0) [0|1] "" XXX
 SG_ Unknown_06 : 226|1@0+ (1,0) [0|1] "" XXX
 SG_ Unknown_07 : 228|1@0+ (1,0) [0|1] "" XXX
 SG_ SET_ME_0X7FFF : 240|16@1+ (1,0) [0|65535] "" XXX
 SG_ Unknown_09 : 262|1@0+ (1,0) [0|3] "" XXX
 SG_ Lead_Type_Detected : 265|1@0+ (1,0) [0|1] "" XXX
 SG_ ACC_Standby_Override : 266|1@0+ (1,0) [0|1] "" XXX
 SG_ Street_Color : 267|1@0+ (1,0) [0|1] "" XXX
 SG_ ACC_Limiter_Mode : 268|1@0+ (1,0) [0|1] "" XXX
 SG_ Lead_Brightness : 269|4@1+ (1,0) [0|7] "" XXX
 SG_ SET_ME_0X6A : 273|8@1+ (1,0) [0|7] "" XXX
 SG_ Lead_Type : 287|3@1+ (1,0) [0|3] "" XXX
 SG_ Lead_Distance : 290|10@1+ (0.2,0) [0|7] "Unit_Meter" XXX
 SG_ ACC_Events : 332|4@0+ (1,0) [0|3] "Unit_Meter" XXX
 SG_ Zeitluecke_1 : 334|9@1+ (0.171,0) [0|100] "Unit_Meter" XXX
 SG_ Zeitluecke_2 : 344|9@1+ (0.171,0) [0|100] "Unit_Meter" XXX
 SG_ Zeitluecke_3 : 354|9@1+ (0.171,0) [0|100] "Unit_Meter" XXX
 SG_ Zeitluecke_4 : 364|9@1+ (0.171,0) [0|100] "Unit_Meter" XXX
 SG_ Zeitluecke_5 : 374|9@1+ (0.171,0) [0|100] "Unit_Meter" XXX

BO_ 333 MEB_ACC_02: 32 XXX
 SG_ CHECKSUM : 0|8@1+ (1,0) [0|255] "" XXX
 SG_ COUNTER : 8|4@1+ (1,0) [0|15] "" XXX
 SG_ ACC_limitierte_Anfahrdyn : 12|1@1+ (1,0) [0|1] "" XXX
 SG_ ACC_nachtr_Stopp_Anf : 13|1@1+ (1,0) [0|1] "" XXX
 SG_ ACC_DynErhoehung : 14|1@1+ (1,0) [0|1] "" XXX
 SG_ ACC_Freilaufstrategie_TSK : 15|1@1+ (1,0) [0|1] "" XXX
 SG_ ACC_zul_Regelabw_unten : 16|6@1+ (0.024,0) [0|1.512] "Unit_MeterPerSeconSquar" XXX
 SG_ ACC_StartStopp_Info : 22|2@1+ (1,0) [0|3] "" XXX
 SG_ ACC_Sollbeschleunigung_02 : 24|11@1+ (0.005,-7.22) [-7.22|3.005] "Unit_MeterPerSeconSquar" XXX
 SG_ ACC_zul_Regelabw_oben : 35|5@1+ (0.0625,0) [0|1.9375] "Unit_MeterPerSeconSquar" XXX
 SG_ ACC_neg_Sollbeschl_Grad_02 : 40|8@1+ (0.05,0) [0|12.75] "Unit_MeterPerCubicSecon" XXX
 SG_ ACC_pos_Sollbeschl_Grad_02 : 48|8@1+ (0.05,0) [0|12.75] "Unit_MeterPerCubicSecon" XXX
 SG_ ACC_Anfahren : 56|1@1+ (1,0) [0|1] "" XXX
 SG_ ACC_Anhalten : 57|1@1+ (1,0) [0|1] "" XXX
 SG_ ACC_Typ : 58|2@1+ (1,0) [0|3] "" XXX
 SG_ ACC_Status_ACC : 60|3@1+ (1,0) [0|7] "" XXX
 SG_ ACC_Minimale_Bremsung : 63|1@1+ (1,0) [0|1] "" XXX
 SG_ ACC_Anhalteweg : 64|11@1+ (0.01,0) [0|2046] "" XXX
 SG_ ACC_Anforderung_HMS : 77|3@1+ (1,0) [0|7] "" XXX
 SG_ SET_ME_0XFE : 80|8@1+ (1,0) [0|255] "" XXX
 SG_ ACC_AKTIV_regelt : 90|1@0+ (1,0) [0|1] "" XXX
 SG_ SET_ME_0X1 : 92|1@0+ (1,0) [0|1] "" XXX
 SG_ SET_ME_0X9 : 232|4@1+ (1,0) [0|15] "" XXX
 SG_ Speed : 236|11@1+ (0.1,0) [0|15] "" XXX
 SG_ Accel_Boost : 248|6@1+ (1,0) [0|3] "" XXX
 SG_ Reversing : 254|1@0+ (1,0) [0|1] "" XXX

BO_ 1004 MEB_TSK_01: 8 XXX
 SG_ TSK_State : 53|3@1+ (1,0) [0|7] "" XXX

BO_ 619 MEB_Travel_Assist_01: 8 XXX
 SG_ CHECKSUM : 0|8@1+ (1,0) [0|255] "" XXX
 SG_ COUNTER : 8|4@1+ (1,0) [0|15] "" XXX
 SG_ Travel_Assist_Status : 13|3@1+ (1,0) [0|3] "" XXX
 SG_ Travel_Assist_Request : 19|3@1+ (1,0) [0|7] "" XXX
 SG_ Travel_Assist_Available : 23|1@1+ (1,0) [0|1] "" XXX

BO_ 387 MEB_Camera_01: 64 XXX
 SG_ NEW_SIGNAL_1 : 191|1@0+ (1,0) [0|1] "" XXX
 SG_ NEW_SIGNAL_2 : 200|9@1+ (1,0) [0|255] "" XXX
 SG_ NEW_SIGNAL_3 : 209|9@1+ (1,0) [0|127] "" XXX
 SG_ NEW_SIGNAL_9 : 218|6@1+ (1,0) [0|63] "" XXX
 SG_ NEW_SIGNAL_10 : 224|8@1+ (1,0) [0|127] "" XXX
 SG_ NEW_SIGNAL_4 : 232|9@1+ (1,0) [0|255] "" XXX
 SG_ NEW_SIGNAL_5 : 241|9@1+ (1,0) [0|127] "" XXX
 SG_ NEW_SIGNAL_8 : 250|6@1+ (1,0) [0|63] "" XXX
 SG_ Lane_Center_Offset : 256|12@1+ (0.001,-2.5) [0|255] "Unit_Meter" XXX
 SG_ NEW_SIGNAL_6 : 268|12@1+ (1,0) [0|255] "" XXX

BO_ 190 MEB_HVEM_01: 48 XXX
 SG_ CRC : 0|8@1+ (1,0) [0|255] "" XXX
 SG_ CNT : 8|4@1+ (1,0) [0|15] "" XXX
 SG_ Engine_RPM_Max : 12|13@1- (2,6732) [0|15] "RPM" XXX
 SG_ Engine_RPM_Min : 26|13@1- (2,6084) [0|63] "RPM" XXX
 SG_ Engine_Power : 56|11@1- (0.25,0.5) [0|255] "kW" XXX
 SG_ Unknown_04 : 72|10@1+ (1,0) [0|255] "" XXX
 SG_ Power_01 : 86|10@1+ (1,0) [0|3] "" XXX
 SG_ Unknown_01 : 100|9@1+ (1,0) [0|7] "" XXX
 SG_ Power_02 : 113|10@1+ (1,0) [0|127] "" XXX

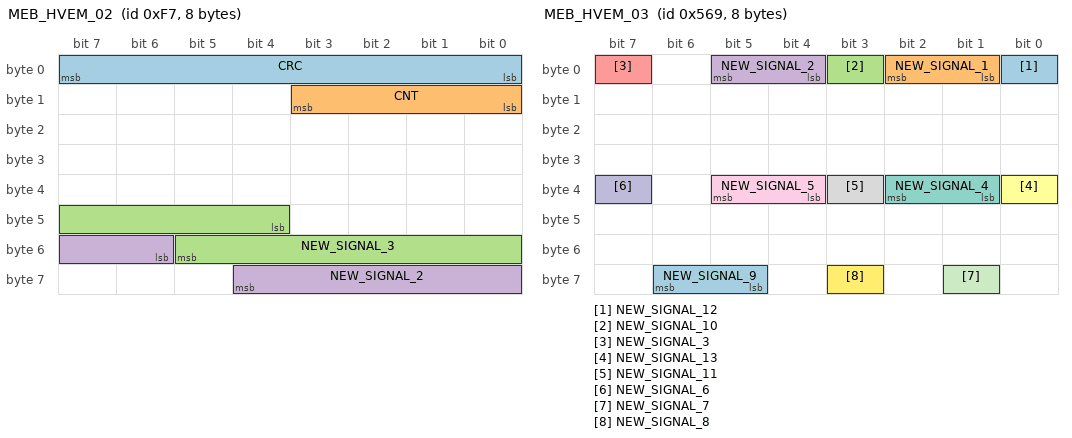
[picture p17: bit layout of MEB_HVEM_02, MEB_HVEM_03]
BO_ 247 MEB_HVEM_02: 8 XXX
 SG_ CRC : 0|8@1+ (1,0) [0|255] "" XXX
 SG_ CNT : 8|4@1+ (1,0) [0|15] "" XXX
 SG_ NEW_SIGNAL_3 : 44|10@1+ (1,0) [0|7] "" XXX
 SG_ NEW_SIGNAL_2 : 54|7@1+ (1,0) [0|3] "" XXX

BO_ 1385 MEB_HVEM_03: 8 XXX
 SG_ NEW_SIGNAL_12 : 0|1@0+ (1,0) [0|1] "" XXX
 SG_ NEW_SIGNAL_1 : 1|2@1+ (1,0) [0|3] "" XXX
 SG_ NEW_SIGNAL_10 : 3|1@0+ (1,0) [0|1] "" XXX
 SG_ NEW_SIGNAL_2 : 4|2@1+ (1,0) [0|3] "" XXX
 SG_ NEW_SIGNAL_3 : 7|1@0+ (1,0) [0|1] "" XXX
 SG_ NEW_SIGNAL_13 : 32|1@0+ (1,0) [0|1] "" XXX
 SG_ NEW_SIGNAL_4 : 33|2@1+ (1,0) [0|3] "" XXX
 SG_ NEW_SIGNAL_11 : 35|1@0+ (1,0) [0|1] "" XXX
 SG_ NEW_SIGNAL_5 : 36|2@1+ (1,0) [0|3] "" XXX
 SG_ NEW_SIGNAL_6 : 39|1@0+ (1,0) [0|1] "" XXX
 SG_ NEW_SIGNAL_7 : 57|1@0+ (1,0) [0|1] "" XXX
 SG_ NEW_SIGNAL_8 : 59|1@0+ (1,0) [0|1] "" XXX
 SG_ NEW_SIGNAL_9 : 61|2@1+ (1,0) [0|3] "" XXX

VAL_ 159 EPS_HCA_Status 0 "disabled" 1 "initializing" 2 "fault" 3 "ready" 4 "rejected" 5 "active" 8 "preempted";
VAL_ 173 GE_Fahrstufe 5 "P" 6 "R" 7 "N" 8 "D" 9 "D" 10 "E" 13 "T" 14 "T";
VAL_ 253 BR_Eingriffsmoment 1022 "Init" 1023 "Fehler" ;
VAL_ 253 ESP_Diagnose 0 "ESP_nicht_in_Diagnose" 1 "ESP_in_Diagnose" ;
VAL_ 253 ESC_v_Signal_Qualifier_High_Low 0 "Gueteschwelle_kleiner_1kmh" 1 "Gueteschwelle_kleiner_3kmh" 2 "Gueteschwelle_kleiner_5kmh" 3 "Gueteschwelle_kleiner_10kmh" 4 "Gueteschwelle_kleiner_20kmh" 5 "Gueteschwelle_groessergleich_20kmh" 6 "Init" 7 "Fehler" ;
VAL_ 253 ESP_Vorsteuerung 0 "keine_Vorsteuerung_aktiv" 1 "Vorsteuerung_aktiv" ;
VAL_ 253 OBD_Schlechtweg 0 "kein_Schlechtweg_erkannt" 1 "Schlechtweg_erkannt" ;
VAL_ 253 OBD_QBit_Schlechtweg 0 "gueltiger_Wert" 1 "Ersatz_Init_oder_Fehlerwert" ;
VAL_ 253 ESP_v_Signal 65533 "Unterspannung" 65534 "Init" 65535 "Fehler" ;
VAL_ 253 ASR_Tastung_passiv 0 "ASR_aktiviert" 1 "ASR_passiv_getastet_oder_Schwellen_geaendert" ;
VAL_ 253 ESP_Tastung_passiv 0 "ESP_aktiviert" 1 "ESP_passiv_getastet_oder_Schwellen_geaendert" ;
VAL_ 253 ESP_Systemstatus 0 "iO" 1 "Fehler" ;
VAL_ 253 ASR_Schalteingriff 0 "keine_Anforderung" 1 "ASR_Schaltkennfeld" 2 "Rueckschaltung" 3 "Schaltverbot" ;
VAL_ 253 ESP_QBit_v_Signal 0 "gueltiger_Wert" 1 "Ersatz_Init_oder_Fehlerwert" ;
VAL_ 253 ABS_Bremsung 0 "keine_ABS_Regelung" 1 "ABS_Regelung_aktiv" ;
VAL_ 253 ASR_Anf 0 "keine_Anforderung" 1 "ASR_Anforderung" ;
VAL_ 253 MSR_Anf 0 "keine Anfoderung" 1 "MSR-Anforderung" ;
VAL_ 253 EBV_Eingriff 0 "kein_EBV_Eingriff" 1 "EBV_Eingriff" ;
VAL_ 253 EDS_Eingriff 0 "kein_EDS_Eingriff" 1 "EDS_Eingriff" ;
VAL_ 253 ESP_Eingriff 0 "kein_ESP_Eingriff" 1 "ESP_Eingriff_aktiv" ;
VAL_ 253 ESP_ASP 0 "inaktiv" 1 "aktiv" ;
VAL_ 253 ESC_Neutralschaltung 0 "keine_Anforderung" 1 "Neutralschaltung_angefordert" ;
VAL_ 317 LatCon_HCA_Status 0 "disabled" 1 "initializing" 2 "ready" 3 "fault" 4 "active" 5 "preempted" 6 "fault" 7 "rejected";
VAL_ 333 ACC_limitierte_Anfahrdyn 0 "keine_Limitierung" 1 "Limitierung_Anfahrdynamik_angefordert";
VAL_ 333 ACC_nachtr_Stopp_Anf 0 "nicht_angefordert" 1 "angefordert";
VAL_ 333 ACC_StartStopp_Info 0 "Motorlauf_langfristig_nicht_notwendig_Stoppfreigabe" 1 "Motoranlauf_nicht_zwingend_notwendig_Stoppverbot_keine_Startanforderung" 2 "Motoranlauf_zwingend_notwendig_Startanforderung" 3 "Systemfehler";
VAL_ 333 ACC_Sollbeschleunigung_02 2046 "Neutralwert" 2047 "Fehler";
VAL_ 333 ACC_Anfahren 0 "keine_Anforderung_Anfahren" 1 "Anforderung_Anfahren";
VAL_ 333 ACC_Anhalten 0 "kein_Anhalten_gewuenscht" 1 "Anhalten_gewuenscht";
VAL_ 333 ACC_Typ 0 "Basis_ACC" 1 "ACC_mit_FollowToStop" 2 "ACC_mit_StopAndGo" 3 "ACC_nicht_codiert";
VAL_ 333 ACC_Status_ACC 0 "ACC_OFF_Hauptschalter_aus" 1 "ACC_INIT" 2 "ACC_STANDBY" 3 "ACC_AKTIV_regelt" 4 "ACC_OVERRIDE" 5 "ACC_Abschaltreaktion" 6 "reversibler_Fehler_im_ACC_System" 7 "irreversibler_Fehler_im_ACC_System";
VAL_ 333 ACC_Minimale_Bremsung 0 "Anforderung_Minimale_Bremsung_nicht_aktiv" 1 "Anforderung_Minimale_Bremsung_aktiv";
VAL_ 333 ACC_Anhalteweg 2046 "Neutralwert" 2047 "Fehler";
VAL_ 333 ACC_Anforderung_HMS 0 "keine_Anforderung" 1 "halten" 2 "parken" 3 "halten_Standby" 4 "anfahren" 5 "Loesen_ueber_Rampe";
VAL_ 333 Accel_Boost 3 "Driving" 0 "Stop" 2 "Driving" 1 "Driving";
VAL_ 420 EA_Parken_beibehalten_HMS 0 "Parken_nicht_beibehalten" 1 "Parken_beibehalten" 2 "Init" 3 "Fehler" ;
VAL_ 420 EA_Warnruckprofil 0 "keine_Ruckanforderung" 1 "Profil_1" 2 "Profil_2" 3 "Profil_3" 4 "Profil_4" 5 "Profil_5" 6 "Profil_6" 7 "Profil_7" ;
VAL_ 420 EA_eCall_Anf 0 "Keine_Anforderung" 1 "Ausloesen_eCall" ;
VAL_ 420 EA_Funktionsstatus 0 "EA_INIT" 1 "EA_OFF" 2 "EA_STANDBY" 3 "EA_PHASE0_AKTIV" 4 "EA_PHASE1_AKTIV" 5 "EA_PHASE2_AKTIV" 6 "EA_PHASE3_AKTIV" 7 "EA_REVERSIBLER_FEHLER" 8 "EA_IRREVERSIBLER_FEHLER" ;
VAL_ 420 EA_Gurtstraffer_Anf 0 "Keine_Anforderung" 1 "Haptik_1" 2 "Haptik_2" 3 "Haptik_3" ;
VAL_ 420 EA_Anforderung_HMS 0 "keine_Anforderung" 1 "halten" 2 "parken" 3 "halten_Standby" 4 "anfahren" 5 "Loesen_ueber_Rampe" 6 "Parken_mit_P" ;
VAL_ 420 EA_Sollbeschleunigung 2046 "Neutralwert" 2047 "Fehler" ;
VAL_ 496 EA_Texte 0 "keine_Anzeige" 1 "Nothalteassistent_fehlende_Fahreraktivitaet" 2 "Nothalteassistent_aktiv_Fahrzeugfuehrung_uebernehmen" 3 "Nothalteassistent_automatischer_Nothalt_wird_durchgefuehrt" 4 "Nothalteassistent_automatischer_Nothalt_durchgefuehrt" 5 "Nothalteassistent_Verbindung_zum_Notruf_wird_aufgebaut" 6 "Nothalteassistent_deaktiviert" 7 "Nothalteassistent_Eingriff_abgebrochen" 8 "Nothalteassistent_fehlende_Fahreraktivitaet_2" 9 "Sekundenschlaf_erkannt" 10 "LaneAssist_Lenkung_uebernehmen" 11 "ACA_Fahrzeugfuehrung_uebernehmen" 12 "EA_Fahr_Standstreifenwechsel" 14 "Nothalteassistent_nicht_verfuegbar_reversibel" 15 "Nothalteassistent_Stoerung_irreversibel" ;
VAL_ 496 ACF_Lampe_Hands_Off 0 "keine_Anzeige" 1 "Hands_Off_erkannt" ;
VAL_ 496 EA_Infotainment_Anf 0 "Init" 1 "Keine_Absenkung" 2 "Absenkung" 3 "Mute" ;
VAL_ 496 EA_Tueren_Anf 0 "Keine_Anforderung" 1 "Tueren_entriegeln" ;
VAL_ 496 EA_Innenraumlicht_Anf 0 "Innenraumbeleuchtung_ausschalten" 1 "Innenraumbeleuchtung_einschalten" ;
VAL_ 496 zFAS_Warnblinken 0 "Aus" 1 "Statisch" 2 "Taster" 3 "Statisch_ohne_WBT" ;
VAL_ 496 STP_Primaeranz 0 "keine_Anzeige" 1 "Verfuegbar" 2 "Aktiv" 3 "Uebernahme" 4 "Aktiv_Warnung" 5 "Nicht_Verfuegbar" ;
VAL_ 496 EA_Bremslichtblinken 0 "kein_Blinken" 1 "Anforderung_Bremslichtblinken" ;
VAL_ 496 EA_Blinken 0 "Kein_Blinken" 1 "Wechselblinken_links" 2 "Wechselblinken_rechts" 3 "Warnblinken" 4 "Warnblinken_Taster" ;
VAL_ 619 Travel_Assist_Status 4 "enabled" 0 "disabled" 2 "ready" 3 "pre_ready";
VAL_ 619 Travel_Assist_Request 4 "enable" 3 "disable" 0 "no_request" 1 "error";
VAL_ 619 Travel_Assist_Available 0 "not_available" 1 "available";
VAL_ 768 ACC_Tempolimit 0 "keine_Anzeige" 1 "5_zulHoechstgeschw" 2 "7_zulHoechstgeschw" 3 "10_zulHoechstgeschw" 4 "15_zulHoechstgeschw" 5 "20_zulHoechstgeschw" 6 "25_zulHoechstgeschw" 7 "30_zulHoechstgeschw" 8 "35_zulHoechstgeschw" 9 "40_zulHoechstgeschw" 10 "45_zulHoechstgeschw" 11 "50_zulHoechstgeschw" 12 "55_zulHoechstgeschw" 13 "60_zulHoechstgeschw" 14 "65_zulHoechstgeschw" 15 "70_zulHoechstgeschw" 16 "75_zulHoechstgeschw" 17 "80_zulHoechstgeschw" 18 "85_zulHoechstgeschw" 19 "90_zulHoechstgeschw" 20 "95_zulHoechstgeschw" 21 "100_zulHoechstgeschw" 22 "110_zulHoechstgeschw" 23 "120_zulHoechstgeschw" 24 "130_zulHoechstgeschw" 25 "140_zulHoechstgeschw" 26 "150_zulHoechstgeschw" 27 "160_zulHoechstgeschw" 28 "200_zulHoechstgeschw" 30 "250_zulHoechstgeschw" 31 "Ende_zulHoechstgeschw";
VAL_ 768 ACC_Wunschgeschw_Farbe 0 "Grundfarbe" 1 "Farbe_1";
VAL_ 768 ACC_Warnung_Verkehrszeichen_1 0 "keine_Warnung_Initialwert" 1 "Warnung";
VAL_ 768 ACA_Querfuehrung 0 "keine_Anzeige_oder_init" 1 "passiv" 2 "aktiv" 3 "Warnung";
VAL_ 768 ACC_Regelung_AIO 0 "Regelung_Ampel_nicht_aktiv" 1 "Regelung_Ampel_aktiv";
VAL_ 768 ACC_Wunschgeschw_02 1023 "keine_Anzeige";
VAL_ 768 ACC_Abstandsindex_02 0 "Audi (Init), VW (passiv/aktiv_Freifahrt)" 1022 "aus_passiv" 1023 "aktiv_Freifahrt";
VAL_ 768 ACC_Display_Prio 0 "hoechste_Prio" 1 "mittlere_Prio" 2 "geringe_Prio" 3 "keine_Prio";
VAL_ 768 ACC_rel_Objekt_Zusatzanz 0 "keine Anzeige" 1 "Relevantes_Objekt_erkannt" 2 "Relevantes_Objekt_Abstandswarnung";
VAL_ 768 ACC_Gesetzte_Zeitluecke 0 "keine_Anzeige" 1 "Zeitluecke_1" 2 "Zeitluecke_2" 3 "Zeitluecke_3" 4 "Zeitluecke_4" 5 "Zeitluecke_5" 6 "nicht_definiert" 7 "nicht_definiert";
VAL_ 768 ACC_Optischer_Fahrerhinweis 0 "optischer_Fahrerhinweis_AUS" 1 "optischer_Fahrerhinweis_EIN";
VAL_ 768 ACC_Warnhinweis 0 "kein_Warnhinweis" 1 "Warnhinweis";
VAL_ 768 ACC_EGO_Fahrzeug 0 "keine_Anzeige" 1 "aktiv" 2 "Warnung" 3 "aktiv_stop" 4 "passiv";
VAL_ 768 ACC_Relevantes_Objekt_02 0 "keine_Anzeige" 1 "Relevantes_Objekt_erkannt" 2 "Relevantes_Objekt_Warnung" 3 "passiv";
VAL_ 768 ACC_Wunschgeschw_erreicht 0 "Wunschgeschwindigkeit_nicht_erreicht" 1 "Wunschgeschwindigkeit_erreicht";
VAL_ 768 ACC_Anzeige_Zeitluecke 0 "Anzeige_Zeitluecke_nicht_angefordert" 1 "Anzeige_Zeitluecke_angefordert";
VAL_ 768 ACC_Texte_Primaeranz_02 0 "keine Anzeige" 1 "VDA_ACC_Symbol_YYY_kmh_mph" 2 "Kurven_Symbol_YYY_kmh_mph" 3 "Tempolimit_Symbol_YYY_kmh_mph" 4 "ACC_anfahrbereit" 5 "eingestellte_Zeitluecke" 6 "Tuer offen !" 7 "Stehendes Objekt voraus" 8 "o  o  o" 9 "ACC aus" 10 "ACC startet" 11 "ACC Sensor Sicht !" 12 "ACC nicht verfuegbar" 13 "ACC Fehler" 14 "ESP Eingriff" 15 "ESP PASSIV !" 16 "Parkbremse !" 17 "Geschwindigkeitsgrenze" 18 "Waehlhebelposition !" 19 "Fahrer Gurtschloss offen !" 20 "Schalthebelposition !" 21 "Drehzahl !" 22 "HDC aktiv" 23 "Kupplung betaetigt" 24 "Gang einlegen !" 25 "Bremse ueberhitzt !" 26 "Steigung_Gefaelle_zu_gross" 27 "ABSTAND" 28 "Rechtsueberholen_verhindert" 29 "Linksueberholen_verhindert" 30 "Kreuzungs_Symbol" 31 "Kreisverkehr_Symbol" 32 "Gefaelle_Symbol" 33 "Tempolimit_Kurvenassistent_ein" 34 "Kurvenassistent_ein" 35 "Tempolimitassistent_ein" 36 "Achtung_Geschwindigkeitsueberschreitung" 37 "Tempolimit_und_Kurvenassistent_nicht_verfuegbar" 38 "Tempolimit_nicht_verfuegbar" 39 "Kurvenassistent_nicht_verfuegbar" 40 "Autobahnausfahrt_Symbol" 41 "Stauende_Symbol" 42 "Engstelle_Symbol" 43 "STP_verfuegbar" 44 "Ampel_vertikal" 45 "Ampel_horizontal" 46 "STA_verfuegbar";
VAL_ 768 ACC_Texte_Zusatzanz_02 0 "keine_Anzeige" 1 "ACC_AUS" 2 "Standby" 3 "UEBERTRETEN" 4 "ABSTAND" 5 "DISTANZ_1" 6 "DISTANZ_2" 7 "DISTANZ_3" 8 "DISTANZ_4" 9 "DISTANZ_5" 10 "DISTANZ_1__dyn" 11 "DISTANZ_2__dyn" 12 "DISTANZ_3__dyn" 13 "DISTANZ_4__dyn" 14 "DISTANZ_5__dyn" 15 "DISTANZ_1__comf" 16 "DISTANZ_2__comf" 17 "DISTANZ_3__comf" 18 "DISTANZ_4__comf" 19 "DISTANZ_5__comf" 20 "DISTANZ_1__efficiency" 21 "DISTANZ_2__efficiency" 22 "DISTANZ_3__efficiency" 23 "DISTANZ_4__efficiency" 24 "DISTANZ_5__efficiency" 25 "DISTANZ_1__Stau" 26 "DISTANZ_2__Stau" 27 "DISTANZ_3__Stau" 28 "DISTANZ_4__Stau" 29 "DISTANZ_5__Stau" 30 "ACHTUNG" 31 "Abstandsanzeige" 32 "Abstandsanzeige_Warnung_aktiviert" 33 "STA_verfuegbar" 34 "Engstelle" 35 "RUV_aktiv_Rechtsverkehr" 36 "RUV_aktiv_Linksverkehr" 37 "STP_Verfuegbar" 38 "AW_Warnschwelle_1" 39 "AW_Warnschwelle_2" 40 "AW_Warnschwelle_3" 41 "AW_Warnung_1" 42 "AW_Warnung_2" 43 "AW_Warnung_3";
VAL_ 768 STA_Primaeranz 0 "keine_Anzeige" 1 "STA_standby" 2 "STA_aktiv" 3 "STA_Warnung";
VAL_ 768 Heartbeat 1 "ACC_Init_Low" 420 "ACC_Init_High" 221 "ACC_Available_Low" 360 "ACC_Available_High";
VAL_ 768 ACC_Status_ACC 0 "ACC_OFF_Hauptschalter_aus" 1 "ACC_INIT" 2 "ACC_STANDBY" 3 "ACC_AKTIV_regelt" 4 "ACC_OVERRIDE" 5 "ACC_Abschaltreaktion" 6 "reversibler_Fehler_im_ACC_System" 7 "irreversibler_Fehler_im_ACC_System";
VAL_ 768 Lead_Type_Detected 1 "Lead_Detected" 0 "No_Lead_Detected";
VAL_ 768 ACC_Driving_Type 3 "Following_Lead" 0 "None" 4 "PACC_Regulating_Speed" 8 "PACC_Regulating_Speed";
VAL_ 768 Unknown_03 0 "None" 106 "State_01" 208 "State_02";
VAL_ 768 Lead_Type 5 "Bicycle" 3 "Car" 0 "None" 2 "Truck" 4 "Motorcycle";
VAL_ 768 ACC_Events 3 "Starting_Available" 0 "None" 5 "Speed_Limit_Camera" 9 "Street_Type" 4 "Speed_Limit_in_Nav";
VAL_ 768 Zeitluecke_1 0 "keine Anzeige";
VAL_ 768 Zeitluecke_2 0 "keine Anzeige" 32 "Minimum";
VAL_ 768 Zeitluecke_3 0 "keine Anzeige";
VAL_ 768 Zeitluecke_4 0 "keine Anzeige" 40 "Minimum";
VAL_ 768 Zeitluecke_5 0 "keine Anzeige";
VAL_ 768 ACC_Zeitluecke_Farbe 0 "white" 1 "yellow";
VAL_ 267 TSK_Status 0 "init" 1 "disabled" 2 "enabled" 3 "regulating" 4 "accel_pedal_override" 5 "brake_only" 6 "temp_fault" 7 "perm_fault";
VAL_ 988 EPB_Status 0 "offen" 1 "geschlossen_Parken" 2 "teilgespannt_Halten" 3 "im_Lauf_oeffnen" 4 "im_Lauf_schliessen" 5 "tbd" 6 "Init" 7 "unbekannt" ;
VAL_ 1004 TSK_State 0 "init" 1 "disabled" 2 "enabled" 3 "regulating" 4 "accel_pedal_override" 5 "brake_only" 6 "temp_fault" 7 "perm_fault";
VAL_ 1124 PSD_06_Mux 0 "Init" ;
VAL_ 1124 PSD_Sys_Segment_ID 0 "keine Segmentinformationen vorhanden" 1 "nicht zulaessig" ;
VAL_ 1124 PSD_Attribut_Segment_ID 0 "keine_Segment_Information_vorhanden" 1 "Fehler" ;
VAL_ 1124 PSD_Ges_Segment_ID 0 "keine Segmentinformationen vorhanden" 1 "nicht zulaessig" ;
VAL_ 1124 PSD_Baum_Laenge_VZ 0 "Ost" 1 "West" ;
VAL_ 1124 PSD_Steigung_1_Segment_ID 0 "keine_Segment_Information_vorhanden" 1 "Fehler" ;
VAL_ 1124 PSD_Baum_Laenge 33554431 "keine_GPS_Information" ;
VAL_ 1124 PSD_Attribut_3_ID 0 "keine_Information" ;
VAL_ 1124 PSD_Steigung_1_A_Steigung 126 "mehr_als_15_Prozent" 127 "Steigung_unbekannt" ;
VAL_ 1124 PSD_Ges_Geschwindigkeit 0 "Kein Geschwindigkeitsgebot" 1 "0 km/h < v_max <  5 km/h" 2 "5 km/h < v_max < 10km/h" 3 "10 km/h < v_max < 15 km/h" 4 "15 km/h < v_max < 20 km/h" 5 "20 km/h < v_max < 25 km/h" 6 "25 km/h < v_max < 30 km/h" 7 "30 km/h < v_max < 35 km/h" 8 "35 km/h < v_max < 40 km/h" 9 "40 km/h < v_max < 45 km/h" 10 "45 km/h < v_max < 50 km/h" 11 "50 km/h < v_max < 60 km/h" 12 "60 km/h < v_max < 70 km/h" 13 "70 km/h < v_max < 80 km/h" 14 "80 km/h < v_max < 90 km/h" 15 "90 km/h < v_max < 100 km/h" 16 "100 km/h < v_max < 110 km/h" 17 "110 km/h < v_max < 120 km/h" 18 " 120 km/h < v_max < 130 km/h" 19 "130 km/h < v_max < 140 km/h" 20 "140 km/h < v_max < 150 km/h" 21 "150 km/h < v_max < 160 km/h" 22 "160 km/h < v_max" 23 "Geschwindigkeitsgebot aufgehoben" 24 "..0x1F ung�ltig" ;
VAL_ 1124 PSD_Steigung_1_A_Vorz 0 "Gefaelle" 1 "Steigung" ;
VAL_ 1124 PSD_Sys_Geschwindigkeit_Einheit 0 "km/h" 1 "mph" ;
VAL_ 1124 PSD_Sys_Verkehrsrichtung 0 "Rechtsverkehr" 1 "Linksverkehr" ;
VAL_ 1124 PSD_Sys_Geometrieguete 0 "Geringe_Guete" 1 "tbd" 2 "tbd" 3 "Hohe_Guete" ;
VAL_ 1124 PSD_Sys_Mapmatchingguete 0 "geringe_Guete" 1 "res" 2 "res" 3 "hohe_Guete" ;
VAL_ 1124 PSD_Ges_Typ 0 "Geschw_Klasse_des_Kartendatensuppliers" 1 "Explizit_abgeleiteten_Begrenzung" 2 "Durch_Gesetzg_vorgeg_allgem_Gebot_fuer_uebertr_Rahmenbed" 3 "Init" ;
VAL_ 1124 PSD_Sys_Alter_Karte 0 "kleiner_1_Jahr" 1 "1_Jahr" 2 "2_Jahre" 3 "3_Jahre" 4 "4_Jahre" 5 "5_Jahre" 6 "6_Jahre" 7 "groesser_7_Jahre" ;
VAL_ 1124 PSD_Ges_Spur_Geschw_Begrenzung 0 "Gebot_fuer_alle_spuren_gueltig" ;
VAL_ 1124 PSD_Steigung_1_B_Steigung 126 "mehr_als_15_Prozent" 127 "Steigung_unbekannt" ;
VAL_ 1124 PSD_Attribut_4_ID 0 "keine_Information" ;
VAL_ 1124 PSD_Sys_Zielfuehrung 0 "Zielfuehrung nicht aktiv" 1 "Zielfuehrung aktiv" ;
VAL_ 1124 PSD_Sys_US_State 0 "kein_US_State" 1 "Alabama" 2 "Alaska" 3 "Arkansas" 4 "Arizona" 5 "California" 6 "Colorado" 7 "Conneticut" 8 "District_of_Columbia" 9 "Delaware" 10 "Florida" 11 "Georgia" 12 "Hawaii" 13 "Idaho" 14 "Illinois" 15 "Iowa" 16 "Indiana" 17 "Kansas" 18 "Kentucky" 19 "Louisiana" 20 "Massachusetts" 21 "Maryland" 22 "Maine" 23 "Michigan" 24 "Minnesota" 25 "Missouri" 26 "Mississippi" 27 "Montana" 28 "North_Carolina" 29 "North_Dakota" 30 "Nebraska" 31 "Nevada" 32 "New_Hampshire" 33 "New_Jersey" 34 "New_Mexico" 35 "New_York" 36 "Ohio" 37 "Oklahoma" 38 "Oregon" 39 "Pennsylvania" 40 "Puerto_Rico" 41 "Rhode_Island" 42 "South_Carolina" 43 "South_Dakota" 44 "Tennessee" 45 "Texas" 46 "Utah" 47 "Virginia" 48 "Virgin_Islands" 49 "Vermont" 50 "Washington" 51 "Wisconsin" 52 "West_Virginia" 53 "Wyoming" ;
VAL_ 1124 PSD_Ges_Geschwindigkeit_Gespann 0 "alle Fahrzeuge" 1 "PKW mit Gespann" 2 "LKW, Busse, etc." ;
VAL_ 1124 PSD_Baum_Breite_VZ 0 "Nord" 1 "Sued" ;
VAL_ 1124 PSD_Ges_Geschwindigkeit_Witter 0 "Witterungsunabh�ngig" 1 "N�sse, Regen, Niederschlag" 2 "Gl�tte" 3 "Nebel" ;
VAL_ 1124 PSD_Steigung_1_B_Vorz 0 "Gefaelle" 1 "Steigung" ;
VAL_ 1124 PSD_Ges_Geschwindigkeit_Tag_Anf 0 "kein Beginn definiert" 1 "Montag" 2 "Dienstag" 3 "Mittwoch" 4 "Donnerstag" 5 "Freitag" 6 "Samstag" 7 "Sonntag" ;
VAL_ 1124 PSD_Ges_Geschwindigkeit_Tag_Ende 0 "kein Ende definiert" 1 "Montag" 2 "Dienstag" 3 "Mittwoch" 4 "Donnerstag" 5 "Freitag" 6 "Samstag" 7 "Sonntag" ;
VAL_ 1124 PSD_Sys_Quali_verfuegbar 0 "Qualitaetskriterien_nicht_verfuegbar" 1 "Qualitaetskriterien_verfuegbar" ;
VAL_ 1124 PSD_Sys_Zielfuehrung_geaendert 0 "Zielfuehrung_nicht_geaendert" 1 "Zielfuehrung_geaendert" ;
VAL_ 1124 PSD_Ges_Geschwindigkeit_Std_Anf 25 "kein Beginn f�r stundenweise Einschr�nkungen" ;
VAL_ 1124 PSD_Steigung_1_Attribute_kompl 0 "Steigungen_nicht_komplett" 1 "Steigungen_komplett" ;
VAL_ 1124 PSD_Sys_Geometrieguete_erweitert 0 "Init" ;
VAL_ 1124 PSD_Steigung_2_Segment_ID 0 "keine_Segment_Information_vorhanden" 1 "Fehler" ;
VAL_ 1124 PSD_Attribut_5_ID 0 "keine_Information" ;
VAL_ 1124 PSD_Ges_Geschwindigkeit_Std_Ende 25 "kein Ende f�r stundenweise Einschr�nkungen" ;
VAL_ 1124 PSD_Steigung_2_Steigung 126 "mehr_als_15_Prozent" 127 "Steigung_unbekannt" ;
VAL_ 1124 PSD_Ges_Ueberholverbot 0 "kein �berholverbot" 1 "alle Fahrzeuge" 2 "�berholverbot f�r PKW mit Gespann" 3 "�berholverbot f�r LKW, Busse, etc." ;
VAL_ 1124 PSD_Ges_Wechselverkehrszeichen 0 "Kein Wechselverkehrszeichen" 1 "Wechselverkehrszeichen links" 2 "Wechselverkehrszeichen rechts" 3 "Wechselverkehrszeichen links und rechts" 4 "Wechselverkerhszeichen �ber der Fahrbahn" ;
VAL_ 1124 PSD_Steigung_2_Vorz 0 "Gefaelle" 1 "Steigung" ;
VAL_ 1124 PSD_Wechselverkehrszeichen_Typ 0 "kein_Wechselverkehrszeichen" 1 "LED_Wechselverkehrszeichen" 2 "nicht_LED_Wechselverkehrszeichen" ;
VAL_ 1124 PSD_Ges_Gesetzlich_Kategorie 0 "kein_legales_Verbot" 1 "innerorts" 2 "ausserorts" 3 "Autobahn" ;
VAL_ 1124 PSD_Attribute_Komplett_06 0 "Attribute_nicht_komplett" 1 "Attribute_komplett" ;
VAL_ 1124 PSD_Ges_Gesetzlich_Zusatz 0 "kein_Zusatz_zu_legalem_Gebot" 1 "Anhaenger_Klasse_1" 2 "Anhaenger_Klasse_2" ;
VAL_ 1124 PSD_Ges_Verkehrszeichen_Quelle 0 "VZA_kein_Onlinedienst" 1 "nur_VZA" 2 "nur_VZO" 3 "VZA_und_VZO" ;
VAL_ 1124 PSD_Steigung_2_Attribute_kompl 0 "Steigungen_nicht_komplett" 1 "Steigungen_komplett" ;
VAL_ 1124 PSD_Ges_Attribute_Komplett 0 "Attribute_nicht_komplett" 1 "Attribute_komplett" ;
VAL_ 1631 TSK_QBit_Steigung 0 "gueltiger_Wert" 1 "Ersatz_Init_oder_Fehlerwert" ;
VAL_ 1631 TSK_QBit_Fahrzeugmasse 0 "gueltiger_Wert" 1 "Ersatz_Init_oder_Fehlerwert" ;
VAL_ 1631 MO_SpannungsAnf_02 0 "keine_Anforderung" 1 "Anforderung_Stufe_1" 2 "Anforderung_Stufe_2" 3 "Anforderung_Stufe_3" ;
VAL_ 1631 MO_DPF_reg 0 "DPF_regeneriert_nicht" 1 "DPF_regeneriert" ;
VAL_ 1631 MO_Heizstrom_EKAT 127 "Fehler" ;
VAL_ 1631 MO_Heizstrom_SCR 63 "Fehler" ;
VAL_ 1631 MO_Anzeige_Kaltleuchte 0 "Lampe_aus" 1 "Lampe_an" ;
VAL_ 1631 MO_P_Generator_ungefiltert_Anf 0 "nicht_angefordert" 1 "angefordert" ;
VAL_ 1631 TSK_Getriebeinfo 0 "Handschalter" 1 "AL_AQ_Getriebe" 2 "DL_DQ_Getriebe" 3 "CVT_Getriebe" ;
VAL_ 1631 MO_Energieinhalt_BMS 4094 "Init" 4095 "Fehler" ;
VAL_ 1631 TSK_Fahrzeugmasse_02 255 "Fehler" ;
VAL_ 1631 TSK_Steigung_02 0 "Init_oder_nicht_verbaut" 255 "Fehler" ;
